VERSION "HNNBNNNYNNNNNNNNNNNNNNNNNNNNNNNNNNNNNNNNNN/4/%%%/4/'%**4NNN///"

NS_ :

BS_:

BU_: _4CL_C6 _6HP_C6 Airbag_C6 CVT_C6 DME_EDC16CP3000 DME_ME7_MED9_C6 DME_SIMOS6_C6 DME_Slave EPB_C6 ESP8_C6 Gateway_C6 LWR_AFS_C6 LWS_C6

BO_ 1088 Getriebe_1: 8 _6HP_C6
 SG_ Schaltung_aktiv : 0|1@1+ (1.0,0.0) [0.0|1.0] ""  DME_EDC16CP3000,DME_ME7_MED9_C6,DME_SIMOS6_C6,ESP8_C6,Gateway_C6
 SG_ Status_Wandlerschutz : 1|1@1+ (1.0,0.0) [0.0|1.0] ""  DME_ME7_MED9_C6,DME_SIMOS6_C6,Gateway_C6
 SG_ Klimakompressor_aus : 2|1@1+ (1.0,0.0) [0.0|1.0] ""  DME_EDC16CP3000,DME_ME7_MED9_C6,DME_SIMOS6_C6,Gateway_C6
 SG_ Wandlerkupplung : 3|2@1+ (1.0,0.0) [0.0|3.0] ""  DME_EDC16CP3000,DME_ME7_MED9_C6,DME_SIMOS6_C6,EPB_C6,Gateway_C6
 SG_ Geschwindigkeit_halten : 5|1@1+ (1.0,0.0) [0.0|1.0] ""  Gateway_C6
 SG_ Codierung_MSG : 6|1@1+ (1.0,0.0) [0.0|1.0] ""  DME_SIMOS6_C6,ESP8_C6,Gateway_C6
 SG_ EGS_Anforderung : 7|1@1+ (1.0,0.0) [0.0|1.0] ""  DME_EDC16CP3000,DME_ME7_MED9_C6,DME_SIMOS6_C6,Gateway_C6
 SG_ Zielgang : 8|4@1+ (1.0,0.0) [0.0|15.0] ""  DME_EDC16CP3000,DME_ME7_MED9_C6,DME_SIMOS6_C6,EPB_C6,ESP8_C6,Gateway_C6
 SG_ Waehlhebelposition : 12|4@1+ (1.0,0.0) [0.0|15.0] ""  DME_EDC16CP3000,DME_ME7_MED9_C6,DME_SIMOS6_C6,EPB_C6,ESP8_C6,Gateway_C6
 SG_ Uebertragungsfunktion_8Bit : 16|8@1+ (0.1,0.0) [0.0|25.4] ""  DME_EDC16CP3000,DME_ME7_MED9_C6,Gateway_C6
 SG_ Inneres_Sollmotormoment : 24|8@1+ (0.39,0.0) [0.0|99.06] "%MDI"  DME_EDC16CP3000,DME_ME7_MED9_C6,DME_SIMOS6_C6,Gateway_C6
 SG_ Fahrwiderstandsindex : 32|8@1+ (0.249,-31.623) [-31.623|31.623] ""  DME_EDC16CP3000,DME_ME7_MED9_C6,DME_SIMOS6_C6,Gateway_C6
 SG_ Getriebe_Notlauf : 40|4@1+ (1.0,0.0) [0.0|15.0] ""  DME_EDC16CP3000,DME_ME7_MED9_C6,DME_SIMOS6_C6,Gateway_C6
 SG_ Kuehlleistung : 44|2@1+ (1.0,0.0) [0.0|3.0] ""  DME_ME7_MED9_C6,DME_SIMOS6_C6,Gateway_C6
 SG_ Geschwindigkeit_Umkehr : 46|1@1+ (1.0,0.0) [0.0|1.0] ""  Gateway_C6
 SG_ OBD_Status : 47|1@1+ (1.0,0.0) [0.0|1.0] ""  DME_EDC16CP3000,DME_ME7_MED9_C6,DME_SIMOS6_C6,Gateway_C6
 SG_ Motor_aus : 48|1@1+ (1.0,0.0) [0.0|1.0] ""  Gateway_C6
 SG_ Getriebeinfo : 49|1@1+ (1.0,0.0) [0.0|1.0] ""  Gateway_C6
 SG_ SIB_Getriebe : 50|1@1+ (1.0,0.0) [0.0|1.0] ""  Gateway_C6
 SG_ BZ_Getriebe1 : 51|4@1+ (1.0,0.0) [0.0|15.0] ""  DME_ME7_MED9_C6,DME_SIMOS6_C6,EPB_C6,ESP8_C6,Gateway_C6
 SG_ FSPE_Getriebe1 : 55|1@1+ (1.0,0.0) [0.0|1.0] ""  Gateway_C6
 SG_ Aufnahmemoment_Leerlauf : 56|8@1+ (0.39,0.0) [0.0|99.06] "%MDI"  DME_EDC16CP3000,DME_ME7_MED9_C6,DME_SIMOS6_C6,Gateway_C6

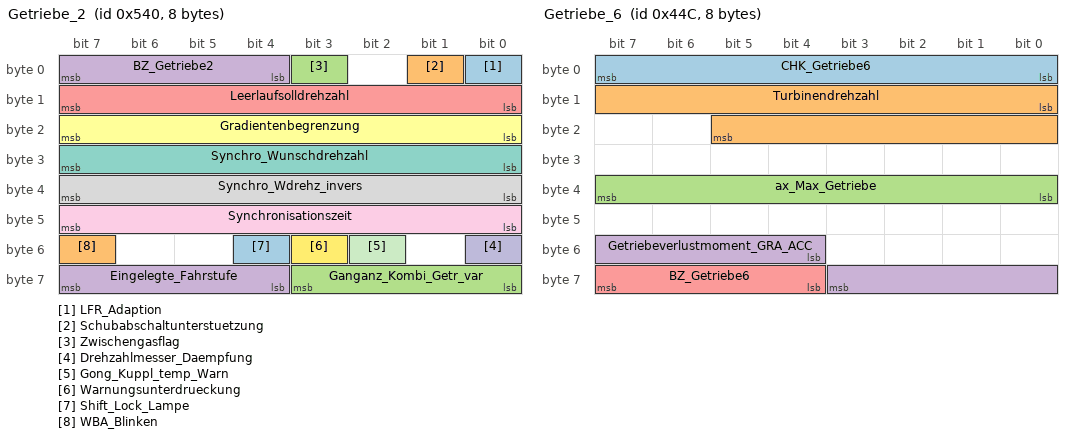
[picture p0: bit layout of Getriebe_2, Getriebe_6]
BO_ 1344 Getriebe_2: 8 _6HP_C6
 SG_ LFR_Adaption : 0|1@1+ (1.0,0.0) [0.0|1.0] ""  DME_EDC16CP3000,DME_ME7_MED9_C6,DME_SIMOS6_C6,Gateway_C6
 SG_ Schubabschaltunterstuetzung : 1|1@1+ (1.0,0.0) [0.0|1.0] ""  DME_ME7_MED9_C6,DME_SIMOS6_C6,Gateway_C6
 SG_ Zwischengasflag : 3|1@1+ (1.0,0.0) [0.0|1.0] ""  DME_EDC16CP3000,DME_ME7_MED9_C6,Gateway_C6
 SG_ BZ_Getriebe2 : 4|4@1+ (1.0,0.0) [0.0|15.0] ""  DME_EDC16CP3000,DME_ME7_MED9_C6,DME_SIMOS6_C6,Gateway_C6
 SG_ Leerlaufsolldrehzahl : 8|8@1+ (10.0,0.0) [0.0|2540.0] "1/min"  DME_EDC16CP3000,DME_ME7_MED9_C6,DME_SIMOS6_C6,Gateway_C6
 SG_ Gradientenbegrenzung : 16|8@1+ (10.0,0.0) [0.0|2540.0] "Nm/s"  DME_EDC16CP3000,DME_ME7_MED9_C6,DME_SIMOS6_C6,Gateway_C6
 SG_ Synchro_Wunschdrehzahl : 24|8@1+ (25.0,0.0) [0.0|6350.0] "1/min"  DME_EDC16CP3000,DME_ME7_MED9_C6,Gateway_C6
 SG_ Synchro_Wdrehz_invers : 32|8@1+ (-25.0,6375.0) [0.0|6350.0] "1/min"  DME_EDC16CP3000,DME_ME7_MED9_C6,Gateway_C6
 SG_ Synchronisationszeit : 40|8@1+ (20.0,0.0) [0.0|5080.0] "ms"  DME_ME7_MED9_C6,Gateway_C6
 SG_ Drehzahlmesser_Daempfung : 48|1@1+ (1.0,0.0) [0.0|1.0] ""  Gateway_C6
 SG_ Gong_Kuppl_temp_Warn : 50|1@1+ (1.0,0.0) [0.0|1.0] ""  Gateway_C6
 SG_ Warnungsunterdrueckung : 51|1@1+ (1.0,0.0) [0.0|1.0] ""  Gateway_C6
 SG_ Shift_Lock_Lampe : 52|1@1+ (1.0,0.0) [0.0|1.0] ""  Gateway_C6
 SG_ WBA_Blinken : 55|1@1+ (1.0,0.0) [0.0|1.0] ""  DME_ME7_MED9_C6,Gateway_C6
 SG_ Ganganz_Kombi_Getr_var : 56|4@1+ (1.0,0.0) [0.0|15.0] ""  Gateway_C6
 SG_ Eingelegte_Fahrstufe : 60|4@1+ (1.0,0.0) [0.0|15.0] ""  Gateway_C6

BO_ 1100 Getriebe_6: 8 _6HP_C6
 SG_ CHK_Getriebe6 : 0|8@1+ (1.0,0.0) [0.0|255.0] ""  DME_EDC16CP3000,Gateway_C6
 SG_ Turbinendrehzahl : 8|14@1+ (1.0,0.0) [0.0|16381.0] "1/min"  DME_EDC16CP3000,Gateway_C6
 SG_ ax_Max_Getriebe : 32|8@1+ (0.024,-2.112) [2.112|3.984] "m/s2"  Gateway_C6
 SG_ Getriebeverlustmoment_GRA_ACC : 52|8@1+ (0.39,0.0) [0.0|99.06] "%MDI"  Gateway_C6
 SG_ BZ_Getriebe6 : 60|4@1+ (1.0,0.0) [0.0|15.0] ""  DME_EDC16CP3000,Gateway_C6

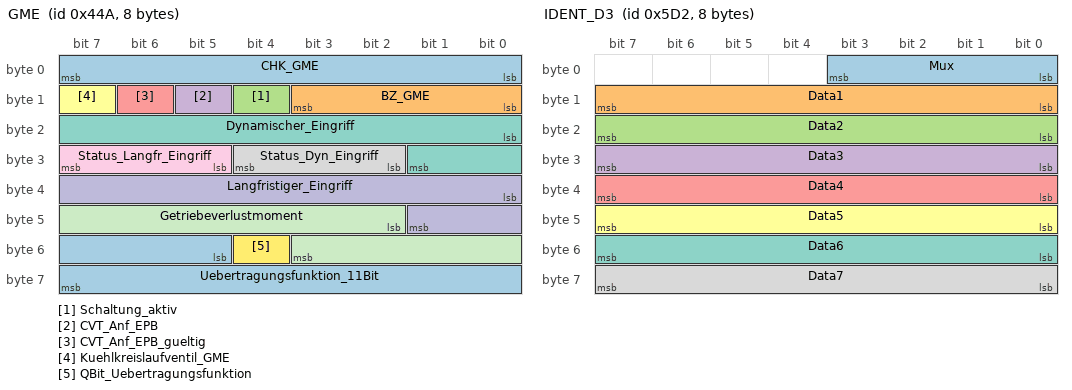
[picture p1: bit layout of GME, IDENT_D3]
BO_ 1098 GME: 8 _6HP_C6
 SG_ CHK_GME : 0|8@1+ (1.0,0.0) [0.0|255.0] ""  DME_EDC16CP3000,DME_ME7_MED9_C6,DME_SIMOS6_C6,ESP8_C6
 SG_ BZ_GME : 8|4@1+ (1.0,0.0) [0.0|15.0] ""  DME_EDC16CP3000,DME_ME7_MED9_C6,DME_SIMOS6_C6,ESP8_C6
 SG_ Schaltung_aktiv : 12|1@1+ (1.0,0.0) [0.0|1.0] ""  DME_ME7_MED9_C6,DME_SIMOS6_C6
 SG_ CVT_Anf_EPB : 13|1@1+ (1.0,0.0) [0.0|1.0] ""  Vector__XXX
 SG_ CVT_Anf_EPB_gueltig : 14|1@1+ (1.0,0.0) [0.0|1.0] ""  Vector__XXX
 SG_ Kuehlkreislaufventil_GME : 15|1@1+ (1.0,0.0) [0.0|1.0] ""  Vector__XXX
 SG_ Dynamischer_Eingriff : 16|10@1+ (1.0,0.0) [0.0|1021.0] "Nm"  DME_EDC16CP3000,DME_ME7_MED9_C6
 SG_ Status_Dyn_Eingriff : 26|3@1+ (1.0,0.0) [0.0|7.0] ""  DME_EDC16CP3000,DME_ME7_MED9_C6,DME_SIMOS6_C6
 SG_ Status_Langfr_Eingriff : 29|3@1+ (1.0,0.0) [0.0|7.0] ""  DME_EDC16CP3000,DME_ME7_MED9_C6,DME_SIMOS6_C6
 SG_ Langfristiger_Eingriff : 32|10@1+ (1.0,0.0) [0.0|1021.0] "Nm"  DME_EDC16CP3000,DME_ME7_MED9_C6,DME_SIMOS6_C6
 SG_ Getriebeverlustmoment : 42|10@1+ (1.0,0.0) [0.0|1021.0] "Nm"  DME_ME7_MED9_C6,ESP8_C6
 SG_ QBit_Uebertragungsfunktion : 52|1@1+ (1.0,0.0) [0.0|1.0] ""  Vector__XXX
 SG_ Uebertragungsfunktion_11Bit : 53|11@1+ (0.025,0.0) [0.0|51.15] ""  Vector__XXX

BO_ 906 GRA_Neu: 4 Gateway_C6
 SG_ CHK_GRA_Neu : 0|8@1+ (1.0,0.0) [0.0|255.0] ""  _6HP_C6,DME_EDC16CP3000,DME_ME7_MED9_C6,DME_SIMOS6_C6
 SG_ GRA_Hauptschalter : 8|1@1+ (1.0,0.0) [0.0|1.0] ""  DME_EDC16CP3000,DME_ME7_MED9_C6,DME_SIMOS6_C6
 SG_ Abbrechen : 9|1@1+ (1.0,0.0) [0.0|1.0] ""  DME_EDC16CP3000,DME_ME7_MED9_C6,DME_SIMOS6_C6
 SG_ KurzTip_down : 10|1@1+ (1.0,0.0) [0.0|1.0] ""  DME_EDC16CP3000,DME_ME7_MED9_C6,DME_SIMOS6_C6
 SG_ KurzTip_up : 11|1@1+ (1.0,0.0) [0.0|1.0] ""  DME_EDC16CP3000,DME_ME7_MED9_C6,DME_SIMOS6_C6
 SG_ LangTip_down : 12|1@1+ (1.0,0.0) [0.0|1.0] ""  DME_EDC16CP3000,DME_ME7_MED9_C6,DME_SIMOS6_C6
 SG_ LangTip_up : 13|1@1+ (1.0,0.0) [0.0|1.0] ""  DME_EDC16CP3000,DME_ME7_MED9_C6,DME_SIMOS6_C6
 SG_ Bedienteil_Fehler : 14|1@1+ (1.0,0.0) [0.0|1.0] ""  DME_EDC16CP3000,DME_ME7_MED9_C6,DME_SIMOS6_C6
 SG_ Codierinfo_SMLS : 15|1@1+ (1.0,0.0) [0.0|1.0] ""  DME_EDC16CP3000,DME_ME7_MED9_C6,DME_SIMOS6_C6
 SG_ Tip_Setzen : 16|1@1+ (1.0,0.0) [0.0|1.0] ""  DME_EDC16CP3000,DME_ME7_MED9_C6,DME_SIMOS6_C6
 SG_ Tip_Wiederaufnahme : 17|1@1+ (1.0,0.0) [0.0|1.0] ""  DME_EDC16CP3000,DME_ME7_MED9_C6,DME_SIMOS6_C6
 SG_ Sendercodierung : 18|2@1+ (1.0,0.0) [0.0|3.0] ""  DME_EDC16CP3000,DME_ME7_MED9_C6,DME_SIMOS6_C6
 SG_ BZ_GRA_Neu : 20|4@1+ (1.0,0.0) [0.0|15.0] ""  _6HP_C6,DME_EDC16CP3000,DME_ME7_MED9_C6,DME_SIMOS6_C6
 SG_ Tiptronic_Tip_Down : 24|1@1+ (1.0,0.0) [0.0|1.0] ""  _6HP_C6,DME_EDC16CP3000,DME_ME7_MED9_C6,DME_SIMOS6_C6
 SG_ Tiptronic_Tip_Up : 25|1@1+ (1.0,0.0) [0.0|1.0] ""  _6HP_C6,DME_EDC16CP3000,DME_ME7_MED9_C6,DME_SIMOS6_C6
 SG_ ACC_Zeitlueckenverstellung : 26|2@1+ (1.0,0.0) [0.0|3.0] ""  DME_EDC16CP3000,DME_ME7_MED9_C6,DME_SIMOS6_C6
 SG_ Tiptronic_Limiter : 28|1@1+ (1.0,0.0) [0.0|1.0] ""  DME_EDC16CP3000,DME_ME7_MED9_C6,DME_SIMOS6_C6
 SG_ Typ_Hauptschalter : 29|1@1+ (1.0,0.0) [0.0|1.0] ""  DME_EDC16CP3000,DME_ME7_MED9_C6,DME_SIMOS6_C6
 SG_ Tiptronic_Tip_Fehler : 31|1@1+ (1.0,0.0) [0.0|1.0] ""  _6HP_C6,DME_EDC16CP3000,DME_ME7_MED9_C6,DME_SIMOS6_C6

BO_ 1490 IDENT_D3: 8 Gateway_C6
 SG_ Mux : 0|4@1+ (1.0,0.0) [0.0|15.0] ""  _4CL_C6
 SG_ Data1 : 8|8@1+ (1.0,0.0) [0.0|255.0] ""  _4CL_C6
 SG_ Data2 : 16|8@1+ (1.0,0.0) [0.0|255.0] ""  _4CL_C6
 SG_ Data3 : 24|8@1+ (1.0,0.0) [0.0|255.0] ""  _4CL_C6
 SG_ Data4 : 32|8@1+ (1.0,0.0) [0.0|255.0] ""  _4CL_C6
 SG_ Data5 : 40|8@1+ (1.0,0.0) [0.0|255.0] ""  _4CL_C6
 SG_ Data6 : 48|8@1+ (1.0,0.0) [0.0|255.0] ""  _4CL_C6
 SG_ Data7 : 56|8@1+ (1.0,0.0) [0.0|255.0] ""  _4CL_C6

BO_ 2016 ISO_Request_ECU_1: 8 Gateway_C6
 SG_ ISO_Request_ECU_Data : 0|64@1+ (1.0,0.0) [0.0|1.8446744073709552E19] ""  Vector__XXX

BO_ 2017 ISO_Request_ECU_2: 8 Gateway_C6
 SG_ ISO_Request_ECU_Data : 0|64@1+ (1.0,0.0) [0.0|1.8446744073709552E19] ""  Vector__XXX

BO_ 2018 ISO_Request_ECU_3: 8 Gateway_C6
 SG_ ISO_Request_ECU_Data : 0|64@1+ (1.0,0.0) [0.0|1.8446744073709552E19] ""  Vector__XXX

BO_ 2019 ISO_Request_ECU_4: 8 Gateway_C6
 SG_ ISO_Request_ECU_Data : 0|64@1+ (1.0,0.0) [0.0|1.8446744073709552E19] ""  Vector__XXX

BO_ 2020 ISO_Request_ECU_5: 8 Gateway_C6
 SG_ ISO_Request_ECU_Data : 0|64@1+ (1.0,0.0) [0.0|1.8446744073709552E19] ""  Vector__XXX

BO_ 2021 ISO_Request_ECU_6: 8 Gateway_C6
 SG_ ISO_Request_ECU_Data : 0|64@1+ (1.0,0.0) [0.0|1.8446744073709552E19] ""  Vector__XXX

BO_ 2022 ISO_Request_ECU_7: 8 Gateway_C6
 SG_ ISO_Request_ECU_Data : 0|64@1+ (1.0,0.0) [0.0|1.8446744073709552E19] ""  Vector__XXX

BO_ 2023 ISO_Request_ECU_8: 8 Gateway_C6
 SG_ ISO_Request_ECU_Data : 0|64@1+ (1.0,0.0) [0.0|1.8446744073709552E19] ""  Vector__XXX

BO_ 2015 ISO_Request_ECU_9: 8 Gateway_C6
 SG_ ISO_Request_ECU_Data : 0|64@1+ (1.0,0.0) [0.0|1.8446744073709552E19] ""  Vector__XXX

BO_ 2024 ISO_Response_ECU_1: 8 Vector__XXX
 SG_ ISO_Response_ECU_Data : 0|64@1+ (1.0,0.0) [0.0|1.8446744073709552E19] ""  Gateway_C6

BO_ 2025 ISO_Response_ECU_2: 8 Vector__XXX
 SG_ ISO_Response_ECU_Data : 0|64@1+ (1.0,0.0) [0.0|1.8446744073709552E19] ""  Gateway_C6

BO_ 2026 ISO_Response_ECU_3: 8 Vector__XXX
 SG_ ISO_Response_ECU_Data : 0|64@1+ (1.0,0.0) [0.0|1.8446744073709552E19] ""  Gateway_C6

BO_ 2027 ISO_Response_ECU_4: 8 Vector__XXX
 SG_ ISO_Response_ECU_Data : 0|64@1+ (1.0,0.0) [0.0|1.8446744073709552E19] ""  Gateway_C6

BO_ 2028 ISO_Response_ECU_5: 8 Vector__XXX
 SG_ ISO_Response_ECU_Data : 0|64@1+ (1.0,0.0) [0.0|1.8446744073709552E19] ""  Gateway_C6

BO_ 2029 ISO_Response_ECU_6: 8 Vector__XXX
 SG_ ISO_Response_ECU_Data : 0|64@1+ (1.0,0.0) [0.0|1.8446744073709552E19] ""  Gateway_C6

BO_ 2030 ISO_Response_ECU_7: 8 Vector__XXX
 SG_ ISO_Response_ECU_Data : 0|64@1+ (1.0,0.0) [0.0|1.8446744073709552E19] ""  Gateway_C6

BO_ 2031 ISO_Response_ECU_8: 8 Vector__XXX
 SG_ ISO_Response_ECU_Data : 0|64@1+ (1.0,0.0) [0.0|1.8446744073709552E19] ""  Gateway_C6

BO_ 1504 Klima1_D3_ACAN: 8 Gateway_C6
 SG_ Signal_fuer_Drehzahlanhebung : 0|1@1+ (1.0,0.0) [0.0|1.0] ""  DME_EDC16CP3000,DME_ME7_MED9_C6,DME_SIMOS6_C6
 SG_ Zuheizer_ein : 1|1@1+ (1.0,0.0) [0.0|1.0] ""  DME_EDC16CP3000,DME_ME7_MED9_C6,DME_SIMOS6_C6
 SG_ HeizungHeckscheibe_ein : 2|1@1+ (1.0,0.0) [0.0|1.0] ""  DME_ME7_MED9_C6
 SG_ HeizungFrontscheibe_ein : 3|1@1+ (1.0,0.0) [0.0|1.0] ""  DME_ME7_MED9_C6
 SG_ Kompressor_ein : 4|1@1+ (1.0,0.0) [0.0|1.0] ""  DME_EDC16CP3000,DME_ME7_MED9_C6,DME_SIMOS6_C6
 SG_ Heizung_ausgeschaltet : 5|1@1+ (1.0,0.0) [0.0|1.0] ""  DME_EDC16CP3000,DME_ME7_MED9_C6
 SG_ Kompressormoment_alt : 6|1@1+ (1.0,0.0) [0.0|1.0] ""  Vector__XXX
 SG_ Kaeltemitteldruck_alt : 7|1@1+ (1.0,0.0) [0.0|1.0] ""  Vector__XXX
 SG_ AussenTemp_aus_Wasserkasten : 8|8@1+ (0.5,-50.0) [-50.0|77.0] "°C"  Vector__XXX
 SG_ KaeltemittelDruck : 16|8@1+ (0.2,0.0) [0.0|50.8] "bar"  DME_ME7_MED9_C6,DME_SIMOS6_C6
 SG_ Kompressorlastinfo : 24|8@1+ (0.25,0.0) [0.0|63.5] "Nm"  DME_EDC16CP3000,DME_ME7_MED9_C6,DME_SIMOS6_C6
 SG_ Geblaeselastinfo : 32|8@1+ (0.4,0.0) [0.0|101.6] "%"  DME_ME7_MED9_C6
 SG_ Ansteuerung_Kuehlerluefter : 40|8@1+ (0.4,0.0) [0.0|101.6] "%"  DME_EDC16CP3000,DME_ME7_MED9_C6,DME_SIMOS6_C6
 SG_ Temp_in_F : 48|1@1+ (1.0,0.0) [0.0|1.0] ""  Vector__XXX
 SG_ Zustand_Klima : 49|1@1+ (1.0,0.0) [0.0|1.0] ""  DME_SIMOS6_C6
 SG_ Restwaermefunktion : 51|1@1+ (1.0,0.0) [0.0|1.0] ""  Vector__XXX
 SG_ SH_aktiv_Flag : 52|1@1+ (1.0,0.0) [0.0|1.0] ""  Vector__XXX
 SG_ SH_MVW : 53|1@1+ (1.0,0.0) [0.0|1.0] ""  Vector__XXX
 SG_ KD_Fehler_Klima : 55|1@1+ (1.0,0.0) [0.0|1.0] ""  Vector__XXX
 SG_ Aussentemp_Stossf_ungef : 56|8@1+ (0.5,-50.0) [-50.0|77.0] "°C"  Vector__XXX

BO_ 800 Kombi_1: 8 Gateway_C6
 SG_ SIB_Kombi : 0|1@1+ (1.0,0.0) [0.0|1.0] ""  Vector__XXX
 SG_ FStatus_Tank : 1|1@1+ (1.0,0.0) [0.0|1.0] ""  DME_ME7_MED9_C6,DME_SIMOS6_C6
 SG_ Oeldruck : 2|1@1+ (1.0,0.0) [0.0|1.0] ""  Vector__XXX
 SG_ Dyn_Oeldr_warn : 3|1@1+ (1.0,0.0) [0.0|1.0] ""  Vector__XXX
 SG_ Kuehlmittelmangel : 4|1@1+ (1.0,0.0) [0.0|1.0] ""  Vector__XXX
 SG_ Wakeup_Komfort : 5|1@1+ (1.0,0.0) [0.0|1.0] ""  Vector__XXX
 SG_ Tankwarnlampe : 6|1@1+ (1.0,0.0) [0.0|1.0] ""  DME_EDC16CP3000,DME_SIMOS6_C6
 SG_ Vorgluehlampe_Kombi : 7|1@1+ (1.0,0.0) [0.0|1.0] ""  DME_EDC16CP3000
 SG_ Bremsfluessigkeitswarnung : 8|1@1+ (1.0,0.0) [0.0|1.0] ""  Vector__XXX
 SG_ Handbremse_angezogen : 9|1@1+ (1.0,0.0) [0.0|1.0] ""  Vector__XXX
 SG_ Ladekontroll_Lampe : 10|1@1+ (1.0,0.0) [0.0|1.0] ""  Vector__XXX
 SG_ Kombi_im_Stellgliedtest : 11|1@1+ (1.0,0.0) [0.0|1.0] ""  Vector__XXX
 SG_ ACC_Zusatzanzeige : 12|3@1+ (1.0,0.0) [0.0|7.0] ""  Vector__XXX
 SG_ Tankstop : 15|1@1+ (1.0,0.0) [0.0|1.0] ""  Vector__XXX
 SG_ Tankinhalt : 16|7@1+ (1.0,0.0) [0.0|126.0] "l"  DME_ME7_MED9_C6,DME_SIMOS6_C6
 SG_ Tankwarnung : 23|1@1+ (1.0,0.0) [0.0|1.0] ""  DME_ME7_MED9_C6,DME_SIMOS6_C6
 SG_ Signalquelle_Geschwindigkeit : 24|1@1+ (1.0,0.0) [0.0|1.0] ""  Vector__XXX
 SG_ BZ_Kombi1 : 40|4@1+ (1.0,0.0) [0.0|15.0] ""  Vector__XXX
 SG_ Konsistenz_ACC_Botschaften : 44|1@1+ (1.0,0.0) [0.0|1.0] ""  Vector__XXX
 SG_ ACC_Anzeigefehler : 45|1@1+ (1.0,0.0) [0.0|1.0] ""  Vector__XXX
 SG_ angez_Geschw : 46|10@1+ (0.31988,0.0) [0.0|325.0] "km/h"  Vector__XXX
 SG_ Einheit_angez_Geschw : 56|1@1+ (1.0,0.0) [0.0|1.0] ""  Vector__XXX
 SG_ ABS_Lampe_ein : 57|1@1+ (1.0,0.0) [0.0|1.0] ""  Vector__XXX
 SG_ ASR_ESP_Lampe_ein : 58|1@1+ (1.0,0.0) [0.0|1.0] ""  Vector__XXX
 SG_ BKL_ein : 59|1@1+ (1.0,0.0) [0.0|1.0] ""  Vector__XXX
 SG_ Airbag_Lampe_ein : 60|1@1+ (1.0,0.0) [0.0|1.0] ""  Vector__XXX
 SG_ Lenkhilfe_Lampe_ein : 61|1@1+ (1.0,0.0) [0.0|1.0] ""  Vector__XXX
 SG_ LDW_Anzeigefehler : 62|1@1+ (1.0,0.0) [0.0|1.0] ""  Vector__XXX
 SG_ SILA_gueltig : 63|1@1+ (1.0,0.0) [0.0|1.0] ""  Vector__XXX

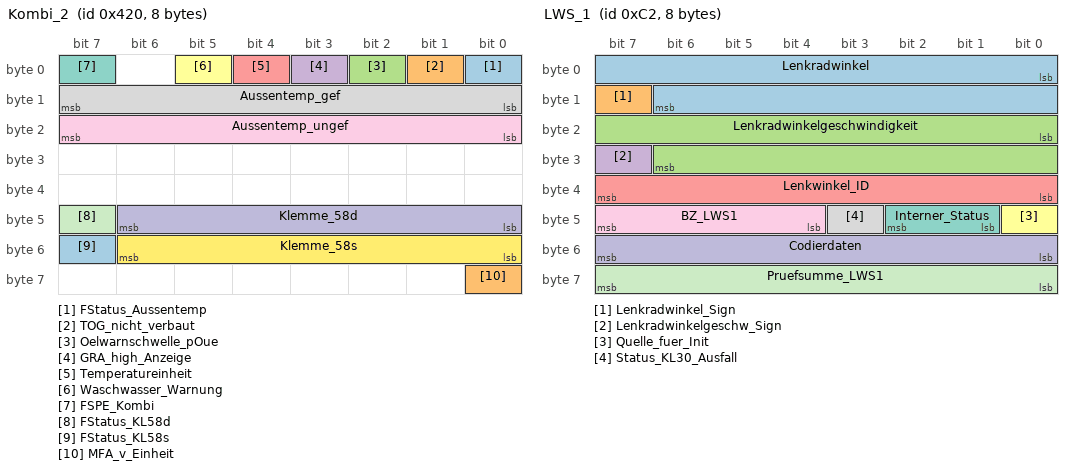
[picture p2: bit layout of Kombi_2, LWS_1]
BO_ 1056 Kombi_2: 8 Gateway_C6
 SG_ FStatus_Aussentemp : 0|1@1+ (1.0,0.0) [0.0|1.0] ""  DME_EDC16CP3000,DME_SIMOS6_C6,EPB_C6,ESP8_C6
 SG_ TOG_nicht_verbaut : 1|1@1+ (1.0,0.0) [0.0|1.0] ""  DME_ME7_MED9_C6
 SG_ Oelwarnschwelle_pOue : 2|1@1+ (1.0,0.0) [0.0|1.0] ""  Vector__XXX
 SG_ GRA_high_Anzeige : 3|1@1+ (1.0,0.0) [0.0|1.0] ""  Vector__XXX
 SG_ Temperatureinheit : 4|1@1+ (1.0,0.0) [0.0|1.0] ""  Vector__XXX
 SG_ Waschwasser_Warnung : 5|1@1+ (1.0,0.0) [0.0|1.0] ""  Vector__XXX
 SG_ FSPE_Kombi : 7|1@1+ (1.0,0.0) [0.0|1.0] ""  Vector__XXX
 SG_ Aussentemp_gef : 8|8@1+ (0.5,-50.0) [-50.0|77.0] "°C"  _6HP_C6,DME_EDC16CP3000,DME_ME7_MED9_C6,DME_SIMOS6_C6,EPB_C6,ESP8_C6
 SG_ Aussentemp_ungef : 16|8@1+ (0.5,-50.0) [-50.0|77.0] "°C"  DME_SIMOS6_C6
 SG_ Klemme_58d : 40|7@1+ (1.0,0.0) [0.0|100.0] "%"  Airbag_C6
 SG_ FStatus_KL58d : 47|1@1+ (1.0,0.0) [0.0|1.0] ""  Airbag_C6
 SG_ Klemme_58s : 48|7@1+ (1.0,0.0) [0.0|100.0] "%"  Vector__XXX
 SG_ FStatus_KL58s : 55|1@1+ (1.0,0.0) [0.0|1.0] ""  Vector__XXX
 SG_ MFA_v_Einheit : 56|1@1+ (1.0,0.0) [0.0|1.0] ""  Vector__XXX

BO_ 1312 Kombi_3: 8 Gateway_C6
 SG_ Multiplex_Sprachvariante m0  : 0|8@1+ (1.0,0.0) [0.0|255.0] ""  Airbag_C6
 SG_ Derivat m1  : 0|4@1+ (1.0,0.0) [0.0|15.0] ""  Vector__XXX
 SG_ Reifenumfang m2  : 0|12@1+ (1.0,0.0) [0.0|4095.0] "mm"  ESP8_C6
 SG_ Verbauliste m3  : 0|11@1+ (1.0,0.0) [0.0|2047.0] ""  Vector__XXX
 SG_ Generation m1  : 4|4@1+ (1.0,0.0) [0.0|15.0] ""  Vector__XXX
 SG_ Multiplex_Laendervariante m0  : 8|6@1+ (1.0,0.0) [0.0|63.0] ""  Airbag_C6
 SG_ Baureihe m1  : 8|3@1+ (1.0,0.0) [0.0|7.0] ""  Vector__XXX
 SG_ Marke m1  : 11|3@1+ (1.0,0.0) [0.0|7.0] ""  Vector__XXX
 SG_ Mux_Code_Kombi3 M  : 14|2@1+ (1.0,0.0) [0.0|3.0] ""  Airbag_C6,ESP8_C6
 SG_ Schluesselinfo : 16|4@1+ (1.0,0.0) [0.0|15.0] ""  Vector__XXX
 SG_ Standzeit : 24|15@1+ (4.0,0.0) [0.0|131068.0] "s"  DME_ME7_MED9_C6,DME_SIMOS6_C6,EPB_C6,ESP8_C6
 SG_ Reset_Standzeit : 39|1@1+ (1.0,0.0) [0.0|1.0] ""  DME_ME7_MED9_C6,EPB_C6,ESP8_C6
 SG_ Kilometerstand : 40|20@1+ (1.0,0.0) [0.0|1048574.0] "km"  _6HP_C6,DME_ME7_MED9_C6,DME_SIMOS6_C6

BO_ 916 LWR_Zustand: 8 LWR_AFS_C6
 SG_ LWR_AFS_Parametrisierung : 0|1@1+ (1.0,0.0) [0.0|1.0] ""  Gateway_C6
 SG_ LWR_AFS_Grundeinstellung : 1|1@1+ (1.0,0.0) [0.0|1.0] ""  Gateway_C6
 SG_ LWR_Modus : 2|1@1+ (1.0,0.0) [0.0|1.0] ""  Gateway_C6
 SG_ LWR_Initialisierungslauf : 3|1@1+ (1.0,0.0) [0.0|1.0] ""  Gateway_C6
 SG_ LWR_Sicherheitsposition : 4|1@1+ (1.0,0.0) [0.0|1.0] ""  Gateway_C6
 SG_ AFS_Fehlerlampe : 5|1@1+ (1.0,0.0) [0.0|1.0] ""  Gateway_C6
 SG_ LWR_Fehlerlampe : 6|1@1+ (1.0,0.0) [0.0|1.0] ""  Gateway_C6
 SG_ FSPE_LWR_AFS : 7|1@1+ (1.0,0.0) [0.0|1.0] ""  Gateway_C6
 SG_ Einfederung_Karosse_vorn : 8|8@1+ (1.0,-127.0) [-126.0|126.0] ""  Gateway_C6
 SG_ Einfederung_Karosse_hinten : 16|8@1+ (1.0,-127.0) [-126.0|126.0] ""  Gateway_C6
 SG_ Stellung_Schrittmotoren : 24|8@1+ (0.4,0.0) [0.0|100.0] "%"  Gateway_C6
 SG_ Sollwert_LD_EVG : 32|8@1+ (0.4,50.0) [50.0|151.2] "%"  Gateway_C6
 SG_ Ersatzlichtfunktion_links : 40|1@1+ (1.0,0.0) [0.0|1.0] ""  Gateway_C6
 SG_ Ersatzlichtfunktion_rechts : 41|1@1+ (1.0,0.0) [0.0|1.0] ""  Gateway_C6
 SG_ AFS_LED_Blinkmode : 42|1@1+ (1.0,0.0) [0.0|1.0] ""  Gateway_C6
 SG_ AFS_Fehlertext : 43|1@1+ (1.0,0.0) [0.0|1.0] ""  Gateway_C6
 SG_ BZ_LWR_Zustand : 60|4@1+ (1.0,0.0) [0.0|15.0] ""  Gateway_C6

BO_ 194 LWS_1: 8 LWS_C6
 SG_ Lenkradwinkel : 0|15@1+ (0.04375,0.0) [0.0|1433.55625] "Grad"  _4CL_C6,_6HP_C6,DME_ME7_MED9_C6,DME_SIMOS6_C6,ESP8_C6,Gateway_C6,LWR_AFS_C6
 SG_ Lenkradwinkel_Sign : 15|1@1+ (1.0,0.0) [0.0|1.0] ""  _4CL_C6,_6HP_C6,DME_SIMOS6_C6,ESP8_C6,Gateway_C6,LWR_AFS_C6
 SG_ Lenkradwinkelgeschwindigkeit : 16|15@1+ (0.04375,0.0) [0.0|1433.55625] "Grad/s"  _4CL_C6,DME_ME7_MED9_C6,DME_SIMOS6_C6,Gateway_C6
 SG_ Lenkradwinkelgeschw_Sign : 31|1@1+ (1.0,0.0) [0.0|1.0] ""  _4CL_C6,DME_SIMOS6_C6,Gateway_C6
 SG_ Lenkwinkel_ID : 32|8@1+ (1.0,0.0) [0.0|255.0] ""  ESP8_C6,Gateway_C6
 SG_ Quelle_fuer_Init : 40|1@1+ (1.0,0.0) [0.0|1.0] ""  Gateway_C6
 SG_ Interner_Status : 41|2@1+ (1.0,0.0) [0.0|4.0] ""  _4CL_C6,DME_ME7_MED9_C6,DME_SIMOS6_C6,ESP8_C6,Gateway_C6,LWR_AFS_C6
 SG_ Status_KL30_Ausfall : 43|1@1+ (1.0,0.0) [0.0|1.0] ""  Gateway_C6
 SG_ BZ_LWS1 : 44|4@1+ (1.0,0.0) [0.0|15.0] ""  _4CL_C6,DME_SIMOS6_C6,ESP8_C6,Gateway_C6
 SG_ Codierdaten : 48|8@1+ (1.0,0.0) [0.0|255.0] ""  ESP8_C6,Gateway_C6
 SG_ Pruefsumme_LWS1 : 56|8@1+ (1.0,0.0) [0.0|255.0] ""  _4CL_C6,DME_SIMOS6_C6,ESP8_C6,Gateway_C6

BO_ 1984 LWS_Calib: 2 ESP8_C6
 SG_ Command_Code_Word : 0|4@1+ (1.0,0.0) [0.0|15.0] ""  LWS_C6
 SG_ LWS_Identifier : 8|7@1+ (1.0,0.0) [0.0|127.0] ""  LWS_C6

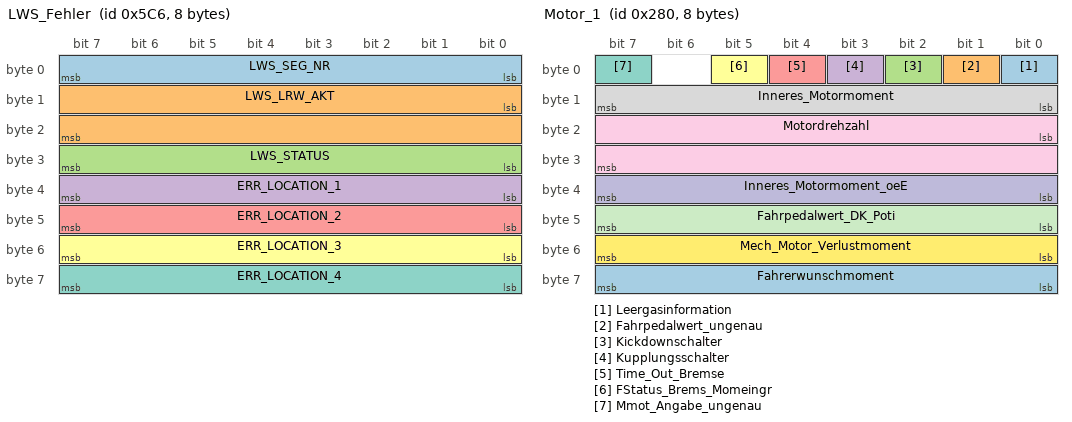
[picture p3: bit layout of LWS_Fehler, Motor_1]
BO_ 1478 LWS_Fehler: 8 LWS_C6
 SG_ LWS_SEG_NR : 0|8@1+ (1.0,0.0) [0.0|255.0] ""  ESP8_C6
 SG_ LWS_LRW_AKT : 8|16@1+ (1.0,0.0) [0.0|65535.0] ""  ESP8_C6
 SG_ LWS_STATUS : 24|8@1+ (1.0,0.0) [0.0|255.0] ""  ESP8_C6
 SG_ ERR_LOCATION_1 : 32|8@1+ (1.0,0.0) [0.0|255.0] ""  ESP8_C6
 SG_ ERR_LOCATION_2 : 40|8@1+ (1.0,0.0) [0.0|255.0] ""  ESP8_C6
 SG_ ERR_LOCATION_3 : 48|8@1+ (1.0,0.0) [0.0|255.0] ""  ESP8_C6
 SG_ ERR_LOCATION_4 : 56|8@1+ (1.0,0.0) [0.0|255.0] ""  ESP8_C6

BO_ 1986 LWS_Init: 4 ESP8_C6
 SG_ ID_fuer_LWS_Init : 0|8@1+ (1.0,0.0) [0.0|255.0] ""  LWS_C6
 SG_ Codierbytes : 8|24@1+ (1.0,0.0) [0.0|255.0] ""  LWS_C6

BO_ 640 Motor_1: 8 DME_EDC16CP3000
 SG_ Leergasinformation : 0|1@1+ (1.0,0.0) [0.0|1.0] ""  EPB_C6,ESP8_C6,Gateway_C6
 SG_ Fahrpedalwert_ungenau : 1|1@1+ (1.0,0.0) [0.0|1.0] ""  _6HP_C6,ESP8_C6,Gateway_C6
 SG_ Kickdownschalter : 2|1@1+ (1.0,0.0) [0.0|1.0] ""  _6HP_C6,Gateway_C6
 SG_ Kupplungsschalter : 3|1@1+ (1.0,0.0) [0.0|1.0] ""  EPB_C6,ESP8_C6,Gateway_C6
 SG_ Time_Out_Bremse : 4|1@1+ (1.0,0.0) [0.0|1.0] ""  ESP8_C6,Gateway_C6
 SG_ FStatus_Brems_Momeingr : 5|1@1+ (1.0,0.0) [0.0|1.0] ""  ESP8_C6,Gateway_C6
 SG_ Mmot_Angabe_ungenau : 7|1@1+ (1.0,0.0) [0.0|1.0] ""  _6HP_C6,EPB_C6,ESP8_C6,Gateway_C6
 SG_ Inneres_Motormoment : 8|8@1+ (0.39,0.0) [0.0|99.06] "%MDI"  _6HP_C6,EPB_C6,ESP8_C6,Gateway_C6
 SG_ Motordrehzahl : 16|16@1+ (0.25,0.0) [0.0|16256.0] "1/min"  _4CL_C6,_6HP_C6,EPB_C6,ESP8_C6,Gateway_C6,LWR_AFS_C6
 SG_ Inneres_Motormoment_oeE : 32|8@1+ (0.39,0.0) [0.0|99.06] "%MDI"  _6HP_C6,Gateway_C6
 SG_ Fahrpedalwert_DK_Poti : 40|8@1+ (0.4,0.0) [0.0|101.6] "%"  _6HP_C6,ESP8_C6,Gateway_C6
 SG_ Mech_Motor_Verlustmoment : 48|8@1+ (0.39,0.0) [0.0|99.06] "%MDI"  _6HP_C6,EPB_C6,ESP8_C6,Gateway_C6
 SG_ Fahrerwunschmoment : 56|8@1+ (0.39,0.0) [0.0|99.06] "%MDI"  _4CL_C6,_6HP_C6,EPB_C6,ESP8_C6,Gateway_C6

BO_ 648 Motor_2: 8 DME_EDC16CP3000
 SG_ CAN_Stand m0  : 0|6@1+ (1.0,0.0) [0.0|63.0] ""  Gateway_C6
 SG_ Motorcode m1  : 0|6@1+ (1.0,0.0) [0.0|63.0] ""  Gateway_C6
 SG_ Getriebecode m2  : 0|6@1+ (1.0,0.0) [0.0|63.0] ""  Gateway_C6
 SG_ MDI_max m3  : 0|6@1+ (10.0,0.0) [0.0|630.0] "Nm"  _6HP_C6,EPB_C6,ESP8_C6,Gateway_C6
 SG_ Mux_Code_Motor2 M  : 6|2@1+ (1.0,0.0) [0.0|3.0] ""  _6HP_C6,EPB_C6,ESP8_C6,Gateway_C6
 SG_ Kuehlmitteltemperatur : 8|8@1+ (0.75,-48.0) [-47.25|142.5] "°C"  _6HP_C6,Gateway_C6
 SG_ Bremslichtschalter_Motor : 16|1@1+ (1.0,0.0) [0.0|1.0] ""  _6HP_C6,Gateway_C6
 SG_ Bremstestschalter_Motor : 17|1@1+ (1.0,0.0) [0.0|1.0] ""  _6HP_C6,Gateway_C6
 SG_ FStatus_Kuehlmitteltemp_Motor : 18|1@1+ (1.0,0.0) [0.0|1.0] ""  _6HP_C6,Gateway_C6
 SG_ Ansteuerung_Klima : 19|1@1+ (1.0,0.0) [0.0|1.0] ""  _6HP_C6,Gateway_C6
 SG_ Status_Normalbetrieb : 20|1@1+ (1.0,0.0) [0.0|1.0] ""  _6HP_C6,Gateway_C6
 SG_ OBD2_Freeze_Frame : 21|1@1+ (1.0,0.0) [0.0|1.0] ""  Gateway_C6
 SG_ GRA_Status : 22|2@1+ (1.0,0.0) [0.0|3.0] ""  _6HP_C6,Gateway_C6
 SG_ GRA_auf_angez_Geschw : 26|1@1+ (1.0,0.0) [0.0|1.0] ""  Gateway_C6
 SG_ Soll_Geschw_GRA : 32|8@1+ (1.28,0.0) [0.0|325.12] "km/h"  _6HP_C6,Gateway_C6
 SG_ Leerlaufsolldrehzahl : 40|8@1+ (10.0,0.0) [0.0|2540.0] "1/min"  _6HP_C6,Gateway_C6
 SG_ Begrenzungsmoment : 48|8@1+ (0.39,0.0) [0.0|99.06] "%MDI"  Gateway_C6
 SG_ Min_Mmot__ZW_Rueckn : 56|8@1+ (0.39,0.0) [0.0|99.06] "%MDI"  ESP8_C6,Gateway_C6

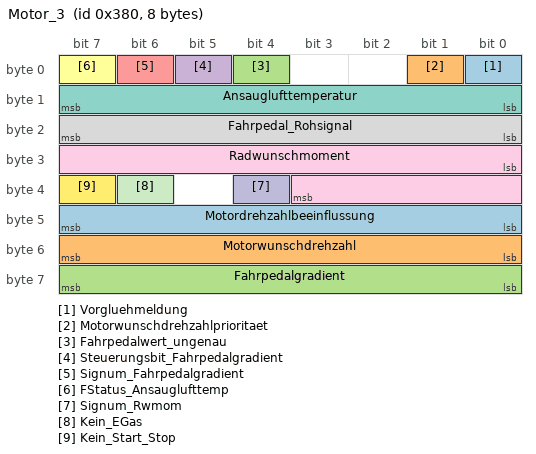
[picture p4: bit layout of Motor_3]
BO_ 896 Motor_3: 8 DME_EDC16CP3000
 SG_ Vorgluehmeldung : 0|1@1+ (1.0,0.0) [0.0|1.0] ""  Gateway_C6
 SG_ Motorwunschdrehzahlprioritaet : 1|1@1+ (1.0,0.0) [0.0|1.0] ""  Gateway_C6
 SG_ Fahrpedalwert_ungenau : 4|1@1+ (1.0,0.0) [0.0|1.0] ""  EPB_C6,Gateway_C6
 SG_ Steuerungsbit_Fahrpedalgradient : 5|1@1+ (1.0,0.0) [0.0|1.0] ""  Gateway_C6
 SG_ Signum_Fahrpedalgradient : 6|1@1+ (1.0,0.0) [0.0|1.0] ""  Gateway_C6
 SG_ FStatus_Ansauglufttemp : 7|1@1+ (1.0,0.0) [0.0|1.0] ""  Gateway_C6
 SG_ Ansauglufttemperatur : 8|8@1+ (0.75,-48.0) [-48.0|142.5] "°C"  Gateway_C6
 SG_ Fahrpedal_Rohsignal : 16|8@1+ (0.4,0.0) [0.0|101.6] "%"  EPB_C6,Gateway_C6
 SG_ Radwunschmoment : 24|12@1+ (0.39,0.0) [0.0|1597.05] "%MDI"  Gateway_C6
 SG_ Signum_Rwmom : 36|1@1+ (1.0,0.0) [0.0|1.0] ""  Gateway_C6
 SG_ Kein_EGas : 38|1@1+ (1.0,0.0) [0.0|1.0] ""  Gateway_C6
 SG_ Kein_Start_Stop : 39|1@1+ (1.0,0.0) [0.0|1.0] ""  Gateway_C6
 SG_ Motordrehzahlbeeinflussung : 40|8@1+ (0.39,0.0) [0.0|99.45] "%"  Gateway_C6
 SG_ Motorwunschdrehzahl : 48|8@1+ (25.0,0.0) [0.0|6325.0] "1/min"  Gateway_C6
 SG_ Fahrpedalgradient : 56|8@1+ (25.0,0.0) [0.0|6375.0] "%/s"  Gateway_C6

BO_ 1152 Motor_5: 8 DME_EDC16CP3000
 SG_ Max_Drehmoment_630Nm m0  : 0|6@1+ (10.0,0.0) [0.0|630.0] "Nm"  Gateway_C6
 SG_ Drehzahl_max_Drehmoment m1  : 0|6@1+ (100.0,0.0) [0.0|6300.0] "1/min"  Gateway_C6
 SG_ Motortyp m2  : 0|6@1+ (1.0,0.0) [0.0|63.0] ""  Gateway_C6
 SG_ Abgastyp m3  : 0|6@1+ (1.0,0.0) [0.0|63.0] "360°/2^32"  _6HP_C6,Gateway_C6
 SG_ Mux_Code_Motor5 M  : 6|2@1+ (1.0,0.0) [0.0|3.0] ""  _6HP_C6,Gateway_C6
 SG_ Ladekontroll_Lampe : 8|1@1+ (1.0,0.0) [0.0|1.0] ""  Gateway_C6
 SG_ Vorgluehlampe_Motor : 9|1@1+ (1.0,0.0) [0.0|1.0] ""  Gateway_C6
 SG_ EGas_Lampe : 10|1@1+ (1.0,0.0) [0.0|1.0] ""  Gateway_C6
 SG_ OBD2_Lampe : 11|1@1+ (1.0,0.0) [0.0|1.0] ""  Gateway_C6
 SG_ Heissleuchte : 12|1@1+ (1.0,0.0) [0.0|1.0] ""  Gateway_C6
 SG_ KK_aus : 13|1@1+ (1.0,0.0) [0.0|1.0] ""  Gateway_C6
 SG_ Kennfeldkuehlung : 14|1@1+ (1.0,0.0) [0.0|1.0] ""  Gateway_C6
 SG_ KK_Leistungsreduzierung : 15|1@1+ (1.0,0.0) [0.0|1.0] ""  Gateway_C6
 SG_ Kraftstoffverbrauchsignal : 16|15@1+ (1.0,0.0) [0.0|32767.0] "ul"  Gateway_C6
 SG_ Verbrauch_Ueberlauf : 31|1@1+ (1.0,0.0) [0.0|1.0] ""  Gateway_C6
 SG_ Kuehlerluefteransteuerung : 32|8@1+ (0.4,0.0) [0.0|101.6] "%"  Gateway_C6
 SG_ HLVW_Motor : 40|1@1+ (1.0,0.0) [0.0|1.0] ""  Gateway_C6
 SG_ Partikelfilter_Lampe : 41|1@1+ (1.0,0.0) [0.0|1.0] ""  Gateway_C6
 SG_ FStatus_BKU_Pumpe : 42|1@1+ (1.0,0.0) [0.0|1.0] ""  Gateway_C6
 SG_ Typ_Startersteuerung : 43|1@1+ (1.0,0.0) [0.0|1.0] ""  Gateway_C6
 SG_ Lampe_Tankdeckelwarnung : 44|1@1+ (1.0,0.0) [0.0|1.0] ""  Gateway_C6
 SG_ Textbit_Tankdeckelwarn : 45|1@1+ (1.0,0.0) [0.0|1.0] ""  Gateway_C6
 SG_ Drehzahlmesser_Daempfung : 46|1@1+ (1.0,0.0) [0.0|1.0] ""  Gateway_C6
 SG_ Interlock_Schalter : 47|1@1+ (1.0,0.0) [0.0|1.0] ""  Gateway_C6
 SG_ Anlasser_Freigabe : 48|1@1+ (1.0,0.0) [0.0|1.0] ""  Gateway_C6
 SG_ Anlasser_Ausspuren : 49|1@1+ (1.0,0.0) [0.0|1.0] ""  Gateway_C6
 SG_ GRA_Hauptschalter : 50|1@1+ (1.0,0.0) [0.0|1.0] ""  Gateway_C6
 SG_ Doppelte_Momente : 51|1@1+ (1.0,0.0) [0.0|1.0] ""  _6HP_C6,ESP8_C6,Gateway_C6
 SG_ Motortext_Bits : 52|4@1+ (1.0,0.0) [0.0|15.0] ""  Gateway_C6
 SG_ CHK_Motor5 : 56|8@1+ (1.0,0.0) [0.0|255.0] ""  ESP8_C6,Gateway_C6

BO_TX_BU_ 1088 :_6HP_C6,CVT_C6;
BO_TX_BU_ 1344 :_6HP_C6,CVT_C6;
BO_TX_BU_ 1100 :_6HP_C6,CVT_C6;
BO_TX_BU_ 1098 :_6HP_C6,CVT_C6;
BO_TX_BU_ 640 :DME_EDC16CP3000,DME_ME7_MED9_C6,DME_SIMOS6_C6;
BO_TX_BU_ 648 :DME_EDC16CP3000,DME_ME7_MED9_C6,DME_SIMOS6_C6;
BO_TX_BU_ 896 :DME_EDC16CP3000,DME_ME7_MED9_C6,DME_SIMOS6_C6;
BO_TX_BU_ 1152 :DME_EDC16CP3000,DME_ME7_MED9_C6,DME_SIMOS6_C6;
CM_ BO_ 2016 "Gesetzlich vorgeschrieber ISO-Diagnose-Kanal für OBD.";
CM_ BO_ 2017 "Gesetzlich vorgeschrieber ISO-Diagnose-Kanal für OBD.";
CM_ BO_ 2018 "Gesetzlich vorgeschrieber ISO-Diagnose-Kanal für OBD.";
CM_ BO_ 2019 "Gesetzlich vorgeschrieber ISO-Diagnose-Kanal für OBD.";
CM_ BO_ 2020 "Gesetzlich vorgeschrieber ISO-Diagnose-Kanal für OBD.";
CM_ BO_ 2021 "Gesetzlich vorgeschrieber ISO-Diagnose-Kanal für OBD.";
CM_ BO_ 2022 "Gesetzlich vorgeschrieber ISO-Diagnose-Kanal für OBD.";
CM_ BO_ 2023 "Gesetzlich vorgeschrieber ISO-Diagnose-Kanal für OBD.";
CM_ BO_ 2015 "Gesetzlich vorgeschrieber ISO-Diagnose-Kanal für OBD.";
CM_ BO_ 2024 "Gesetzlich vorgeschrieber ISO-Diagnose-Kanal für OBD.";
CM_ BO_ 2025 "Gesetzlich vorgeschrieber ISO-Diagnose-Kanal für OBD.";
CM_ BO_ 2026 "Gesetzlich vorgeschrieber ISO-Diagnose-Kanal für OBD.";
CM_ BO_ 2027 "Gesetzlich vorgeschrieber ISO-Diagnose-Kanal für OBD.";
CM_ BO_ 2028 "Gesetzlich vorgeschrieber ISO-Diagnose-Kanal für OBD.";
CM_ BO_ 2029 "Gesetzlich vorgeschrieber ISO-Diagnose-Kanal für OBD.";
CM_ BO_ 2030 "Gesetzlich vorgeschrieber ISO-Diagnose-Kanal für OBD.";
CM_ BO_ 2031 "Gesetzlich vorgeschrieber ISO-Diagnose-Kanal für OBD.";

CM_ SG_ 1088 Aufnahmemoment_Leerlauf "Kupplungsmoment bei ASG- oder DQ-Getriebe; wird als Vorsteuermoment für LFR genutzt; Gesamtes Aufnahmemoment des Getriebes

0xFF = Fehler";
CM_ SG_ 1088 BZ_Getriebe1 "Freilaufender 4Bit-Botschaftszähler. BZ_Getriebe1 läuft synchron mit dem BZ_Getriebe_2 zur Sicherstellung der Synchronität.";
CM_ SG_ 1088 Codierung_MSG "Getriebe-Codierung im Motorsteuergerät ist in Ordnung

0x0 = Codierung niO
0x1 = Codierung iO";
CM_ SG_ 1088 EGS_Anforderung "QBit für Datum 'Inneres Sollmoment', Byte 4 wird damit gültig

0x0 = keine Anforderung
0x1 = EGS angefordert";
CM_ SG_ 1088 Fahrwiderstandsindex "Auf % Steigung am Berg normiert

0xFF = Fehler";
CM_ SG_ 1088 FSPE_Getriebe1 "Bei gesetztem Bit ist mindestens ein Kundendienstfehler eingetragen

0x0 = kein KD_Fehler eingetragen
0x1 = KD_Fehler eingetragen
";
CM_ SG_ 1088 Geschwindigkeit_halten "Bremse verhindert, daß das Fahrzeug beim Schalten des Längsgetriebes zu schnell wird. Nur Colorado!

0x0 = keine Anforderung
0x1 = Geschwindigkeit halten";
CM_ SG_ 1088 Geschwindigkeit_Umkehr "Bremse verhindert, daß das Fahrzeug beim Schalten des Längsgetriebes (Getriebe in N) zurückrollt. Nur Colorado!

0x0 = keine Bremsunterstützung
0x1 = Bremsunterstützung notwendig";
CM_ SG_ 1088 Getriebe_Notlauf "Die Signalspec der Gertiebenotlaufbits wurde nicht abwärtskompatibel verändert, neue Festlegung nach folgender Tabelle:

0x0 = kein Notlauf, Gangwechsel = 0, Zielgang erreicht =0
0x1 = kein Schalten
0x2 = Schalten nach N
0x3 = 50% Schalten
0x4 = Fah";
CM_ SG_ 1088 Getriebeinfo "CVT-Getriebe (VL30, ...) setzen Bit auf '1'; Sonstige Getriebe (bspw. Stufenautomat) geben '0' aus

0x0 = Stufenautomat
0x1 = CVT";
CM_ SG_ 1088 Inneres_Sollmotormoment "Getriebeeingriff an den Motor

0xFF = Fehler";
CM_ SG_ 1088 Klimakompressor_aus "Bit wird an Motor weitergeleitet, der Klima ausschaltet

0x0 = keine Anforderung
0x1 = Kompressor aus";
CM_ SG_ 1088 Kuehlleistung "0x0 = keine zusätzliche Kühlleistung
0x1 = Lüfterleistung um 20% erhöhen
0x2 = Lüfterleistung um 40% erhöhen, Wassertemperatur -10
0x3 = maximale Lüfterleistung; Wassertemperatur Senken (max)";
CM_ SG_ 1088 Motor_aus "Motor soll beim Umschalten des Bits ausgeschaltet (Mengenstellwerk stromlos) bzw. eingeschaltet werden; nur Direktschalter-Projekte bspw. ASG im W10 oder PQ24

0x0 = Motor startbereit
0x1 = Motor aus";
CM_ SG_ 1088 OBD_Status "Dieses Bit steuert die MIL-Lampe an (Motorsteuergerät reicht diese Info an Kombi weiter).

0x0 = MIL aus
0x1 = MIL ein";
CM_ SG_ 1088 Schaltung_aktiv "0x0 = keine Schaltung
0x1 = Schaltung aktiv";
CM_ SG_ 1088 SIB_Getriebe "Die Sleep-Bereitschaft wird nach KL15 aus durch Setzen dieses Bits signalisiert.

0x0 = CAN wird benötigt
0x1 = Sleep bereit";
CM_ SG_ 1088 Status_Wandlerschutz "Umschaltung permanente Leistungsreduzierung (Einspritzausblendung) oder Zündwinkelverstellung (Otto)

0x0 = kein Schutz
0x1 = Schutz angefordert";
CM_ SG_ 1088 Uebertragungsfunktion_8Bit "Übersetzungs-Verhältnis des Getriebes inkl. Antriebsstrang (ohne Berücksichtigung Wirkungsgrade bzw. Verlustmomente)

Bei AL: 

Übertragungsfunktion = mueWandler * ( nTurbine / nRad ), 
mit mueWandler = Wandlerverstärkung, nTurbine = Drehzahl am Wand";
CM_ SG_ 1088 Wandlerkupplung "Auch für Anfahrkupplung beim VL30 und Kupplung beim Ecodrive (geregelt bedeutet in diesem Fall die Kupplung ist nicht vollständig getrennt bzw. hat Schlupf) genutzt; bei starken Verstellwegen wird 'geöffnet' gesendet (VQ250)

0x0 = Wandlerkupplung geöff";
CM_ SG_ 1088 Zielgang "Zielgang, wenn Schaltung aktiv; ansonsten aktuell eingelegter Gang

0x0 = Gang P/N (ausgekuppelt)	
0x1 = Gang 1
0x2 = Gang 2
0x3 = Gang 3
0x4 = Gang 4
0x5 = Gang 5
0x6 = 1m Gang
0x7 = R
0x8 = Gang 6
0x9 = Gang 7
0xA ... 0xD = frei
0xE = Istga";

CM_ SG_ 1344 BZ_Getriebe2 "Freilaufender 4Bit-Botschaftszähler. BZ_Getriebe2 läuft synchron mit dem BZ_Getriebe_1 zur Sicherstellung der Synchronität.";
CM_ SG_ 1344 Drehzahlmesser_Daempfung "Beim DQ-Getriebe kann die Anzeigedämpfung des Drehzahlmessers beim Schalten geändert werden. 

0x0 = normale Dämpfung
0x1 = dynamische Dämpfung";
CM_ SG_ 1344 Gong_Kuppl_temp_Warn "Wichtiger Warnhinweis vom Getriebe: Textanzeige Kupplungstemperaturwarnung für DQ-Getriebe: 'Stop Anhalten Getriebe' (z.Zt. nur Vorhalt)";
CM_ SG_ 1344 Gradientenbegrenzung "Drehmomenten-Gradientenbegrenzung für Teillastanfahrten mit dem VL30-Getriebe und Standabkopplung beim 5HPx, 6HPx";
CM_ SG_ 1344 Leerlaufsolldrehzahl "Wunschvorgabewert vom CVT-Getriebe, 5HPx, 6HPx, DQ und ASG an Motor";
CM_ SG_ 1344 LFR_Adaption "Da das VL30-Getriebe im Stillstand unter gewissen Randbedingungen wechselnde Kupplungsmomente einstellt (z.B. Hillholder), sollte die Leerlaufauffüllungsadaption im Motorsteuergerät für diese Zustände gesperrt werden. 

";
CM_ SG_ 1344 Schubabschaltunterstuetzung "Wenn die SAS-Unterstützung aktiv ist, wird vom VL30-Steuergerät sichergestellt, daß die Kupplung nicht schlagartig geöffnet wird.";
CM_ SG_ 1344 Shift_Lock_Lampe "Wählhebel ist durch Shift-Lock-Funktion blockiert.";
CM_ SG_ 1344 Warnungsunterdrueckung "Unterdrueckung der dynamischen Öldruckwarnung und der Ansteuerung von Warnlampen durch das Getriebe (z.Zt. Generator und Öldrucklampe)";
CM_ SG_ 1344 WBA_Blinken "Dieses Bit steuert die Fehlerlampe an oder wird zum Blinken der WBA-Anzeige genutzt (5HP, 6HP, PNG, ASG, VL30)";
CM_ SG_ 1344 Zwischengasflag "Byte 4,5 und 6 sollen ausgeführt werden";

CM_ SG_ 1100 ax_Max_Getriebe "Maximale Sollbeschleunigung Getriebe. Information empfängt ACC2 ab C6/AU716.

0x58 = Init
0xFF = Fehlerwert
";
CM_ SG_ 1100 BZ_Getriebe6 "Freilaufender 4Bit-Botschaftszähler";
CM_ SG_ 1100 CHK_Getriebe6 "XOR über Summe aller Bytes siehe High-Speed-CAN-Lastenheft";
CM_ SG_ 1100 Getriebeverlustmoment_GRA_ACC "Verlustmoment des Lieferumfangs Getriebes (ohne separate Anbauteile wie Verteilergetriebe, Vorderachsdifferential) bezogen auf die Kurbelwelle (Moment das am Wandler ansteht) beim Stufenautomat wird die Wandlerverstärkung mit eingerechnet (beim Kupplungsa";
CM_ SG_ 1100 Turbinendrehzahl "Wird gesendet, um das Lastschlagverhalten bei Schaltvorgängen zu verbessern. 

0x3FFE = Init
0x3FFF = Fehler";

CM_ SG_ 1098 CVT_Anf_EPB "EPB setzt nach Plausibilisierung die Anforderung (schließen/öffnen) um";
CM_ SG_ 1098 CVT_Anf_EPB_gueltig "Anforderung an EPB gültig, d.h. Byte 2, Bit 5 ausführen!";
CM_ SG_ 1098 Dynamischer_Eingriff "Schalt-/Verstelleingriff";
CM_ SG_ 1098 Getriebeverlustmoment "Verlustmoment ohne Nutzanteil für ESP.";
CM_ SG_ 1098 Kuehlkreislaufventil_GME "In der ZKE verbauter Treiber steuert das Kühlkreislaufventil an";
CM_ SG_ 1098 Langfristiger_Eingriff "Voreilende Momenteninformation, um den Motor auf kommende Momentenanforderung (durch Motorsollmoment) vorzubereiten. In Verbindung mit den Status-Bits kann der Motor den passenden Betriebspunkt voreinstellen.";
CM_ SG_ 1098 QBit_Uebertragungsfunktion "0x0 = gültiger Wert
0x1 =  Ersatzwert oder Initwert
";
CM_ SG_ 1098 Schaltung_aktiv "Es findet aktuell eine Schaltung statt.";
CM_ SG_ 1098 Status_Dyn_Eingriff "Wenn während eines Zyklus einmal '0x7 = Fehler erkannt' gesetzt wurde, darf für den restlichen Zyklus (bis KL15 Aus/Ein) kein momentenerhöhender Eingriff mehr ausgeführt werden. ";
CM_ SG_ 1098 Uebertragungsfunktion_11Bit "Redundant zur Übertragungsfunktion_8Bit in Getriebe_1, eingeführt wegen höherer Auflösung

Übersetzungs-Verhältnis des Getriebes inkl. Antriebsstrang (ohne Berücksichtigung Wirkungsgrade bzw. Verlustmomente)

Bei AL: 

Übertragungsfunktion = mueWand";

CM_ SG_ 906 Abbrechen "0 = Tippschalter nicht betaetigt
1 = Tippschalter betaetigt
GRA : aus mit speichern
ACC : Soft aus";
CM_ SG_ 906 ACC_Zeitlueckenverstellung "00 = Taste nicht betaetigt
01 = Dist -1
10 = Dist +1
11 = nicht belegt

DIST -1 = Zeitluecke um 1 Stufe kleiner
DIST +1 = Zeitluecke um 1 Stufe groeßer";
CM_ SG_ 906 Bedienteil_Fehler "0 = in Ordnung
1 = Fehler Bedienteil";
CM_ SG_ 906 BZ_GRA_Neu "Botschaftszaehler, Definition im CAN-Lastenheft V 2.0";
CM_ SG_ 906 CHK_GRA_Neu "XOR über Summe aller Bytes
siehe High-Speed-CAN-Lastenheft";
CM_ SG_ 906 Codierinfo_SMLS "0 = GRA codiert
1 = ACC codiert";
CM_ SG_ 906 GRA_Hauptschalter "0 = Gerastet Aus; 1 = Ein";
CM_ SG_ 906 KurzTip_down "0 = Tippschalter nicht betaetigt
1 = Tippschalter betaetigt
GRA : Verzögern
ACC : Kurz Tip down";
CM_ SG_ 906 KurzTip_up "0 = Tippschalter nicht betaetigt
1 = Tippschalter betaetigt
GRA : Beschleunigen
ACC : Kurz Tip up";
CM_ SG_ 906 LangTip_down "0 = Tippschalter nicht betaetigt
1 = Tippschalter betaetigt
GRA : Verzögern
ACC : Lang Tip down";
CM_ SG_ 906 LangTip_up "0 = Tippschalter nicht betaetigt
1 = Tippschalter betaetigt
GRA : Beschleunigen
ACC : Lang Tip up";
CM_ SG_ 906 Sendercodierung "00 = Bordnetzsteuergeraet
01 = Lensäulenmodul
10 = Motor SG
11 = nicht belegt";
CM_ SG_ 906 Tip_Setzen "0 = Tippschalter nicht betaetigt
1 = Tippschalter betaetigt
ACC : Tippschalter Set";
CM_ SG_ 906 Tip_Wiederaufnahme "0 = Tippschalter nicht betaetigt
1 = Tippschalter betaetigt
ACC : Tippschalter Resume";
CM_ SG_ 906 Tiptronic_Limiter "0 = Limiter aus
1 = Limiter ein";
CM_ SG_ 906 Tiptronic_Tip_Down "0 = Tippschalter nicht betaetigt
1 = Tippschalter betaetigt";
CM_ SG_ 906 Tiptronic_Tip_Fehler "0 = i. O.
1 = Fehler erkannt";
CM_ SG_ 906 Tiptronic_Tip_Up "0 = Tippschalter nicht betaetigt
1 = Tippschalter betaetigt";

CM_ SG_ 1504 Ansteuerung_Kuehlerluefter "FFH  Fehler";
CM_ SG_ 1504 AussenTemp_aus_Wasserkasten "FFH  Fehler";
CM_ SG_ 1504 Aussentemp_Stossf_ungef "Dieses Signal wird im D3 nicht bedient; Klima sendet immer FFh";
CM_ SG_ 1504 Geblaeselastinfo "FFH  Fehler";
CM_ SG_ 1504 Heizung_ausgeschaltet "1 = beide Temperaturklappen stehen auf Kaltanschlag";
CM_ SG_ 1504 HeizungFrontscheibe_ein "1 = Frontscheibenheizung ein";
CM_ SG_ 1504 HeizungHeckscheibe_ein "1 = Heckscheibenheizung ein";
CM_ SG_ 1504 KaeltemittelDruck "FFH  Fehler";
CM_ SG_ 1504 Kaeltemitteldruck_alt "1 = veraltet, bei Kl 15 aus";
CM_ SG_ 1504 KD_Fehler_Klima "1 = min ein KD - Fehlerspeichereintrag vorhanden";
CM_ SG_ 1504 Kompressor_ein "1 = Kompressor ein";
CM_ SG_ 1504 Kompressorlastinfo "FFH  Fehler";
CM_ SG_ 1504 Kompressormoment_alt "1 = veraltet, bzw Ermittlung des Moments nicht moeglich
(z.B. keine Drehzahl, kein Kaeltemitteldruck)";
CM_ SG_ 1504 Restwaermefunktion "Status der Restwaermefunktion fuer das Motor-SG 
0 = nicht aktiviert; 1 = aktiviert";
CM_ SG_ 1504 SH_aktiv_Flag "1 = Standheizung ist bzw. war die letzte Stunde aktiv; 
Achtung : Bit ist in VW D1 anders belegt";
CM_ SG_ 1504 SH_MVW "0 = SH ohne Motorvorwärmung (kl. Kreis); 1 = SH mit Motorvorwärmung (gr. Kreis); Achtung : Bit ist in VW D1 anders belegt";
CM_ SG_ 1504 Signal_fuer_Drehzahlanhebung "1 = Drehzahlanhebung, Forderung an den Motor";
CM_ SG_ 1504 Temp_in_F "1 = Temperaturanzeige der Klimaanlage in °F
0 = Temperaturanzeige der Klimaanlage in °C
Temperatur auf Bus immer in °C !!!";
CM_ SG_ 1504 Zuheizer_ein "1 = Zuheizerfreigabe";
CM_ SG_ 1504 Zustand_Klima "Zustand der Klimasteuerung 0 =  Off; 1 = On";

CM_ SG_ 800 ABS_Lampe_ein "ABS-Sicherheits-Lampe wurde eingeschaltet.

0x0 = ABS Lampe aus
0x1 = ABS Lampe ein";
CM_ SG_ 800 ACC_Anzeigefehler "Bit wird bei einem ACC/ADR relevanten Fehler (Anzeige/Gong) gesetzt.

0x0 = kein Fehler
0x1 = ACC Anzeige defekt";
CM_ SG_ 800 ACC_Zusatzanzeige "Nur in ADR/ACC-Fahrzeugen: ACC Zusatzanzeige: 0 = aus / ungleich 0 = ein; angezeigte ADR-Zeitlücke wird auf 3 Bits begrenzt

0x0 = keine Anzeige
0x1 = Zeitlücke 1
...
0x7 = Zeitlücke 7
";
CM_ SG_ 800 Airbag_Lampe_ein "Airbag Sicherheits-Lampe wurde eingeschaltet 

0x0 = Airbag Lampe aus
0x1 = Airbag Lampe ein";
CM_ SG_ 800 angez_Geschw "Low Byte 6 (Bit 7,6), High Byte 7; Am Tacho angezeigte Geschwindigkeit inkl. Voreilung

0xFF im Byte7 = Fehler 
";
CM_ SG_ 800 ASR_ESP_Lampe_ein "ASR-/ESP-Sicherheits-Lampe wurde eingeschaltet 

0x0 = ASR/ESP Lampe aus
0x1 = ASR/ESP Lampe ein";
CM_ SG_ 800 BKL_ein "Sicherheits-Lampe Bremskontrolle wurde eingeschaltet; Besonderheit (VW PQ35/46): Lampe wird auch zur Handbremskontrolle (Audi: auch von EPB) und Bremsflüssigkeitswarnung (auch bei Audi) verwendet und vom Kombi aufgeprüft

0x0 = BKL aus
0x1 = BKL ein
";
CM_ SG_ 800 Bremsfluessigkeitswarnung "0x0 = iO
0x1 = Bremsflüssigkeitswarnung";
CM_ SG_ 800 BZ_Kombi1 "Freilaufender 4Bit-Botschaftszähler";
CM_ SG_ 800 Dyn_Oeldr_warn "Öldruckwarnung könnte auch vom Empfänger des Öldruckschalters generiert werden.

0x0 = iO
0x1 = Warnung";
CM_ SG_ 800 Einheit_angez_Geschw "Dem Fahrer wird die Geschwindigkeit in km/h oder in miles/hour angezeigt (konstanter Wert).

0x0 = km/h
0x1 = mph";
CM_ SG_ 800 FStatus_Tank "Nach 2 Sekunden liegt spätestens die Tankinfo vor

0x0 = Tankfüllstand i.O.
0x1 = Tankfüllstand n.i.O
";
CM_ SG_ 800 Handbremse_angezogen "Umgesetzt bei VW, Audi B6,B7; Nicht Audi-Fahrzeuge mit EPB (Audi D3, C6), wird wieder bedient im AU716; Sonderfall PQ46: Hardware-Eingang von EPB zur Ansteuerung der BKL-Lampe, auch im Betriebsfall BKL-Blinken;

0x0 = nicht angezogen
0x1 = angezogen
";
CM_ SG_ 800 Kombi_im_Stellgliedtest "Im Stellgliedtest werden auch Lampen angesteuert. Achtung: Rückmeldebits können gesetzt sein!

0x0 = nein
0x1 = ja";
CM_ SG_ 800 Konsistenz_ACC_Botschaften "Rückmeldung zum ACC-/ADR- System bzgl. CAN- Lastenheft

0x0 = iO
0x1 = Fehler";
CM_ SG_ 800 Kuehlmittelmangel "0x0 = iO
0x1 = Mangel

";
CM_ SG_ 800 Ladekontroll_Lampe "Kombi hat seine Ladekontroll-Lampe eingeschaltet (Empfänger: z.Zt. Batman) ; nicht PQ35/46, nicht Audi D3/C6

0x0 = Lampe aus
0x1 = Lampe ein";
CM_ SG_ 800 LDW_Anzeigefehler "Kombiinstrument hat Fehler erkannt

0x0 = kein Fehler
0x1 = Fehler";
CM_ SG_ 800 Lenkhilfe_Lampe_ein "Lenkhilfe-Sicherheits-Lampe wurde eingeschaltet

0x0 = Lenkhilfe Lampe aus
0x1 = Lenkhilfe Lampe ein";
CM_ SG_ 800 Oeldruck "Öldruckschalter

0x0 = kleiner als Schwellwert
0x1 = größer Schwellwert
";
CM_ SG_ 800 SIB_Kombi "SleepIndication-Bit zwischen Kombi und Gateway. Wird bedient z.Zt. nur Audi D3/C6, Audi AB2 und VW PQ46.
Bit hält im PQ35/46 den CAN-Infotainment wach

0x0 = CAN wird benötigt
0x1 = Sleep bereit
";
CM_ SG_ 800 Signalquelle_Geschwindigkeit "Die Fahrzeuggeschwindigkeit wird aus einem Tachogeber (eigener Hallgeber, eigener Reed-Kontakt, Fahrtenschreiber) oder aus der Referenzgeschwindigkeit vom ABS berechnet (nicht Audi D3/C6)

0x0 = Tachogeber
0x1 = ABS-Signal";
CM_ SG_ 800 SILA_gueltig "Rückmeldeinformation (Bit 1-6) ist gültig

0x0 = ungueltig
0x1 = gueltig";
CM_ SG_ 800 Tankinhalt "Restmenge 2 bzw. 2,5l nicht auflösbar

0x7F = Fehler

";
CM_ SG_ 800 Tankstop "Kombi hat Tankstop erkannt (Vorsicht: Wartezeit nach Klemme 15 ein berücksichtigen); Flag wird nach 5 Sekunden bei fahrendem Fahrzeug gelöscht

0x0 = kein Tankstop
0x1 = Tankstop erkannt";
CM_ SG_ 800 Tankwarnlampe "Fahrer wird gewarnt, z.Zt. liegt die Warnschwelle bei 7 Liter.

0x0 = Lampe aus
0x1 = Lampe ein";
CM_ SG_ 800 Tankwarnung "OBD-Schwelle, z. Zt. 15 %, applizierbar

0x0 = iO
0x1 = Tankwarnung";
CM_ SG_ 800 Vorgluehlampe_Kombi "Rückmeldeinformation für das Motorsteuergerät

0x0 = Lampe aus
0x1 = Lampe ein";
CM_ SG_ 800 Wakeup_Komfort "Das Audi PQ35-/ VW PQ46 Kombi kann durch Setzen dieses Bits bei aktivem Kombi-CAN den Komfort-CAN aufwecken oder wachhalten.

0x0 = keine Anforderung
0x1 = Wakeup Komfort
";

CM_ SG_ 1056 Aussentemp_gef "Realer Meßbereich ~  -45 bis +58 Grad; 

0x0 = nicht verbaut
0xFF = Fehler";
CM_ SG_ 1056 Aussentemp_ungef "Klima-Steuergerät kann aus dem Rohsignal eigene Plausibilitäten berechnen; 0 für nicht verbaut; im Hochlauf alter abgespeicherter Wert bis neuer vorliegt

0xFF = Fehler";
CM_ SG_ 1056 FSPE_Kombi "Bei gesetztem Bit ist mindestens ein Kundendienstfehler eingetragen

0x0 = kein Fehlerspeichereintrag
0x1 = mindestens ein Fehlerspeichereintrag";
CM_ SG_ 1056 FStatus_Aussentemp "n.i.O. steht für Fehlerwert, außerhalb des Meßbereichs (ungenau), nicht verbaut oder noch kein aktueller Wert

0x0 = iO
0x1 = niO";
CM_ SG_ 1056 FStatus_KL58d "n.i.O. steht für nicht verfügbar oder Ersatzwert in Bit 6..0 wird vorgegeben (Standard); VW Highline / Mini-DOT und Audi Kombis geben das mit dem Fototransister bewertete Signal aus

0x0 = KL58d iO
0x1 = KL58d niO";
CM_ SG_ 1056 FStatus_KL58s "n.i.O. steht für nicht verfügbar (z. Zt. bei VW) oder Ersatzwert in Bit 6..0 wird vorgegeben

0x0 = KL58s iO
0x1 = KL58s niO";
CM_ SG_ 1056 GRA_high_Anzeige "Kombi unterstützt die 'GRA High'-Anzeige, Sollgeschwindigkeit wird im Kombi angezeigt

0x0 = nein
0x1 = ja";
CM_ SG_ 1056 Klemme_58d "Display-Beleuchtung, Tastverhältnis in Prozent

0x7F = kein Ersatzwert";
CM_ SG_ 1056 Klemme_58s "Schalter-Beleuchtung (z.Zt. nur Audi) ,Tastverhältnis in Prozent

0x7F = kein Ersatzwert";
CM_ SG_ 1056 MFA_v_Einheit "Meldung an den Motor, mit welcher Einheit die GRA-Geschwindigkeit dargestellt wird, damit der Motor in der Botschaft Motor_8 die GRA-Wunschgeschwindigkeit anzeigeoptimiert ausgeben kann (Verhinderung von Werten, die kleiner Meilengröße entsprechen). (Im B";
CM_ SG_ 1056 Oelwarnschwelle_pOue "Ölwarnschwelle plus Offset überschritten (s. TOG1, Byte 8, Bit 1)

0x0 = nein
0x1 = ja

";
CM_ SG_ 1056 Temperatureinheit "Außentemperatur Anzeige im Kombi wird in Grad Celsius oder Fahrenheit gemacht

0x0 = °C
0x1 = °F";
CM_ SG_ 1056 TOG_nicht_verbaut "TOG ist nicht am Kombi angeschlossen, die TOG-Botschaft wird nicht vom Kombi gesendet. (Bit wird bei Audi nicht unterstützt und mit
0x0 ausgegeben).

0x0 = TOG verbaut
0x1 = TOG nicht verbaut";
CM_ SG_ 1056 Waschwasser_Warnung "Zusatzinfo zur Scheinwerferreinigungsanlage (z.Zt. nur Audi D3)

0x0 = keine Warnung
0x1 = Waschwasserwarnung aktiv";

CM_ SG_ 1312 Kilometerstand "Low Byte 6, High Byte 7 und in Byte 8 Bit 3..0 (additiv); Wertebereich geht bis (220 - 1), Fehler wird ausgegeben, falls Kilometerstand nicht restaurierbar

0xFFFFF = Fehler
";
CM_ SG_ 1312 Multiplex_Sprachvariante "


";
CM_ SG_ 1312 Mux_Code_Kombi3 "0x0 = Länder und Sprachvariante werden nur ausgegeben, wenn Sie im Kombi vorliegen (z.B. Highline)

0x1 = Plattforminformation

0x2 = mittlerer Reifenumfang in Millimeter (Byte 2 Bit 5,4 reserviert; Byte 2, Bit 0=>3 und Byte 1 Bit0=>7; Wertebereich 0 ";
CM_ SG_ 1312 Reifenumfang "Mittlerer Radumfang aus der K-Zahl gerechnet in Millimeter.  Byte 2 Bit 5,4 reserviert, Byte 2 Bit 3..0 und Byte 1 Bit 7..0; Wertebereich 0..4096 mm
";
CM_ SG_ 1312 Reset_Standzeit "0x0 = Standzeit iO
0x1 = KL30 war weg";
CM_ SG_ 1312 Schluesselinfo "15 Schlüssel-Infos; nur wenn WFS im Kombi implementiert ist!

0x0 = keine Info
0x1 = Schlüssel Nr.1
...
0xF = Schlüssel Nr.15
";
CM_ SG_ 1312 Standzeit "Low Byte 4, High Byte 5;
Standzeit in 4 Sekunden Auflösung; mit diesen 15 Bits läßt sich eine Zeit bis 36 Stunden, 24 Minuten und 28 Sekunden darstellen; 
Der Standzeitzähler wird mit KL15_Aus gestartet, er bleibt 2 Minuten vor einem Überlauf stehen, di";

CM_ SG_ 916 AFS_Fehlerlampe "Status der Fehlerlampe: aktuell anliegender Fehlerzustand des dynamischen oder statischen Kurvenlichtes

0x0 = AFS Fehlerlampe aus
0x1 = AFS Fehlerlampe ein";
CM_ SG_ 916 AFS_Fehlertext "Fehlertext wird im Kombi angezeigt (z.Zt nur bei VW)

0x0 = kein Text
0x1 = AFS ohne Funktion";
CM_ SG_ 916 AFS_LED_Blinkmode "Lampe soll im Warnfall mit 1Hz blinken, wenn das Bit gesetzt ist (z.Zt nur bei VW)

0x0 = kein Blinkmode angefordert
0x1 =Blinkmode angefordert";
CM_ SG_ 916 BZ_LWR_Zustand "Freilaufender 4Bit-Botschaftszähler";
CM_ SG_ 916 Einfederung_Karosse_hinten "Aktueller Höhensensorwert hinten (bei PQ35/46 links), oder bei Verbau Luftfederung aus der Niveau 2-Botschaft gespiegelt (M-Ausstattung C6/AU716, Serie D3, M-Ausstattung MangeRide TTNF).

0x7F = 0 mm
0xFE = nicht initialisiert
0xFF = Fehler";
CM_ SG_ 916 Einfederung_Karosse_vorn "Aktueller Höhensensorwert vorne (bei PQ35/46 links), oder bei Verbau Luftfederung aus der Niveau 2-Botschaft gespiegelt (M-Ausstattung C6/AU716, Serie D3, M-Ausstattung MagneRide TT NF).

0x7F = 0 mm
0xFE = nicht initialisiert
0xFF = Fehler
";
CM_ SG_ 916 Ersatzlichtfunktion_links "Bei aktivierter Ersatzlichtfunktion wird das Abblendlicht ausgeschaltet und eine Ersatzlichtquelle eingeschaltet (z.Zt. B7)

0x0 = keine Ersatzlichtfunktion links
0x1 = Ersatzlichtfunktion links";
CM_ SG_ 916 Ersatzlichtfunktion_rechts "Bei aktivierter Ersatzlichtfunktion wird das Abblendlicht ausgeschaltet und eine Ersatzlichtquelle eingeschaltet (z.Zt. B7)

0x0 = keine Ersatzlichtfunktion rechts
0x1 = Ersatzlichtfunktion rechts";
CM_ SG_ 916 FSPE_LWR_AFS "Bei gesetztem Bit ist mindestens ein Kundendienstfehler eingetragen

0x0 = kein KD_Fehler eingetragen
0x1 = KD_Fehler eingetragen
";
CM_ SG_ 916 LWR_AFS_Grundeinstellung "Grundeinstellung des Abblendlichtes am Lichteinstellkasten im Service oder Bandende mit Tester erfolgt! (auch für das dynamische Kurvernlicht)

0x0 = Grundeinstellung nicht erfolgt
0x1 = Grundeinstellung erfolgt";
CM_ SG_ 916 LWR_AFS_Parametrisierung "Parametrisierung wählt die Fahrzeugvariante und die AFS-Variante aus

0x0 = Parametrisierung nicht erfolgt
0x1 = Parametrisierung erfolgt
";
CM_ SG_ 916 LWR_Fehlerlampe "Status der Fehlerlampe: aktuell anliegender Fehlerzustand

0x0 = LWR Fehlerlampe aus
0x1 = LWR Fehlerlampe ein";
CM_ SG_ 916 LWR_Initialisierungslauf "Initialisierungslauf der Schrittmotoren, erfolgt defaultmäßig beim Motorstart

0x0 = Initialisierungslauf nicht erfolgt
0x1 = Initialisierungslauf erfolgt
";
CM_ SG_ 916 LWR_Modus "Schnelle oder langsame Regelart der LWR

0x0 = LWR statisch
0x1 = LWR dynamisch";
CM_ SG_ 916 LWR_Sicherheitsposition "LWR Sicherheitsposition beider Scheinwerfers

0x0 = Sicherheitsposition aus
0x1 = Sicherheitsposition ein";
CM_ SG_ 916 Sollwert_LD_EVG "100 % entsprechen 35 Watt. Die Last schaltet nur das ILM

0xFE = Init
0xFF = Fehler

";
CM_ SG_ 916 Stellung_Schrittmotoren "Position des Aktuators in Prozent des maximalen Stellweges; vor dem Initialisierungslauf (Motorstart) wird der Initwert ausgegeben: 
0% : tiefste Stellung (auf Block) des Schrittmotors;
100% : maximaler Verstellweg des Schrittmotors (nicht die Grenze de";

CM_ SG_ 640 Fahrerwunschmoment "Moment vor Filter, nutzbar zur Zug- / Schuberkennung beim Getriebe (beim TDI identisch mit innerem Moment)

0xFF = Fehler";
CM_ SG_ 640 Fahrpedalwert_DK_Poti "Bei EGAS wird hier der Fahrpedalwert ausgegeben; Maximum aus Rohsignal, gefiltertem Wert (TDI) und virtuellem Wert aus Kennfeld (bei aktiver integrierter GRA), Wert wird bei Doppelpotis auch bei einer defekten Poti-Spur ausgegeben, genutzter Wertebereich ";
CM_ SG_ 640 Fahrpedalwert_ungenau "Ersatzwert aus Modellrechnung oder Fehlerwert in Byte , Leergas- oder Kickdown-Info können betroffen sein. Qualifizierungsbit!

0x0 = Fahrpedal i.O
0x1 = Ersatzwert
";
CM_ SG_ 640 FStatus_Brems_Momeingr "Eingriffswunsch (ASR oder MSR) vom Bremsensteuergerät (ABS) kann nicht ausgeführt werden, weil im Motorsteuergerät ein statischer Fehler vorliegt oder die Funktion durch die Applikation abgeschaltet ist.

0x0 = erfüllbar
0x1 = statisch nicht erfüllbar";
CM_ SG_ 640 Inneres_Motormoment "Indiziertes Motormoment, d.h. idealisiertes berechnetes Moment ohne mechanische Verluste, aber mit externen Eingriffen.

0xFF = Fehler";
CM_ SG_ 640 Inneres_Motormoment_oeE "Indiziertes Motormoment ohne externe Eingriffe (ASR, MSR, Getriebe ...) aber inklusive integrierter GRA

0xFF = Fehler";
CM_ SG_ 640 Kickdownschalter "Wert '0' kann für nicht verbaut stehen, bei Doppelanalogpedalwertgeber ggfs. errechneter Wert.

0x0 = kein Kickdown
0x1 = Kickdown
";
CM_ SG_ 640 Kupplungsschalter "Nur Handschalter; aktiv, wenn Schalter verbaut; sonst konstant auf '0' gesetzt; Bit wird gesetzt, wenn Kupplungspedal nicht 
betätigt wird (Kupplungsschalter hoch), Triebstrang kann noch eingekuppelt sein.

0x0 = Schalter sagt ausgekuppelt
0x1 = Schal";
CM_ SG_ 640 Leergasinformation "Fahrpedal-Leergasschalter, Leergasinfo aus Fahrpedalwert oder Leerlaufschalter bei Drosselklappe (wird zur Freigabe der MSR-Funktion im ABS verwendet).

0x0 = kein Leergas
0x1 = Leergas
";
CM_ SG_ 640 Mech_Motor_Verlustmoment "Beinhaltet z.Zt. Reibung vom Motor und Klimakompressor, beim TDI z.T. auch die Generatorverluste

0xFF = Fehler";
CM_ SG_ 640 Mmot_Angabe_ungenau "Ungenaue Momentenangaben, weil die Momente aus Ersatzwerten berechnet wurden (z.B. HFM ausgefallen). Qualifizierungsbit für die Motormomente.

0x0 = nein (Werte iO)
0x1 = ja

";
CM_ SG_ 640 Motordrehzahl "Low Byte 3, High Byte 4; es wird der letzte aktuelle Meßwert gesendet, d.h. die Zeit für das letzte Arbeitsspiel (180 Grad KW beim 4 Zylinder) wird herangezogen; der Fehlerwert wird gesendet, wenn das Motorsteuergerät keine plausible Drehzahlinformation h";
CM_ SG_ 640 Time_Out_Bremse "500 ms Timeout auf Bremsen-Botschaft ist >= 1 mal aufgelaufen, Löschen des Bits nach Neustart (KL15).

0x0 = Empfang i.O.
0x1 = Time Out
";

CM_ SG_ 648 Ansteuerung_Klima "Zustand des Klimakompressors, d.h. Rückmeldung der bidirektionalen Schnittstelle (konventionell oder CAN)

0x0 = Klima aus
0x1 = Klima ein
";
CM_ SG_ 648 Begrenzungsmoment "Inneres maximal mögliches Moment bei einer Drehzahl (z.B. Rauchbegrenzung oder Fehlerfall)

0xFF = Fehler";
CM_ SG_ 648 Bremslichtschalter_Motor "Ungefiltertes Rohsignal des Bremslichtschalters

0x0 = kein Bremsen
0x1 = Bremse betätigt

";
CM_ SG_ 648 Bremstestschalter_Motor "Ein Empfänger kann BLS und BTS miteinander plausibilisieren ('0' für nicht verbaut). Fzg. ohne BTS (z.B. PQ46): Bit aus Bremse 1, Byte 2, Bit 3 Bremsdruckschwelle überschritten wird gespiegelt.

0x0 = kein Bremsen
0x1 = Bremse betätigt
";
CM_ SG_ 648 CAN_Stand "CAN-Version

Code    CAN-Stand

0x19 = CAN V4.3.5 (erste Version Audi D3)
0x1A = CAN V4.3.6 (erste Version Audi AB2)
0x1F= CAN V4.4.5 (zweite Version Audi D3)
0x26 = CAN V4.6.5 / V4.6.7 (dritte Version Audi D3  zu SOP / erste Version Audi C6)
0x27";
CM_ SG_ 648 FStatus_Kuehlmitteltemp_Motor "'niO' steht für Ersatzwert oder Fehlerwert in Byte2

0x0 = Temperatur iO
0x1 = Temperatur niO
";
CM_ SG_ 648 Getriebecode "Getriebecodierung des Motors 

0x0 = 5HP19
0x1 = 5HP24
0x2 = AG4
0x3 = VL300 (CVT)
0x4 = VQ250
0x5 = VQ35
0x6 = AG4 (Jatco, u.a.)
0x7 = AG5 (Jatco, u.a.)
0x8 = Automatisierte Kupplung
0x9 = Automatisierte Kupplung mit ASG
0xA = AG6 (Jatco, ZF ";
CM_ SG_ 648 GRA_auf_angez_Geschw "GRA regelt auf die im Kombi angezeigte Geschwindigkeit: 'GRA High Funktion'

0x0 = GRA regelt nicht auf angezeigte Geschwindigkeit
0x1 = GRA regelt auf angezeigte Geschwindigkeit";
CM_ SG_ 648 GRA_Status "0x0 = steht auch für nicht verbaut und ADR nicht zulässig; 
0x1 = bedeutet eingeschaltet, GRA vom Fahrer aktiviert und z.Zt. im Regelbetrieb oder ADR erlaubt; 
0x2 = Fahrer gibt mehr Gas als der Regler; 
0x3 = Fehler in Motorsteuerung oder Timeout oder";
CM_ SG_ 648 Kuehlmitteltemperatur "Motor-Kühlmitteltemperatur oder Ersatzwert; Initwert '0' ist außerhalb des Wertebereichs!

0xFF = Fehler";
CM_ SG_ 648 Leerlaufsolldrehzahl "Wunschvorgabewert vom CVT-Getriebe, 5HPx, 6HPx, DQ und ASG an Motor";
CM_ SG_ 648 MDI_max "Maximales Moment (Normierwert MDI)";
CM_ SG_ 648 Min_Mmot__ZW_Rueckn "Nur bei Ottomotoren (Diesel setzt Byte auf 0)

0xFF = Fehler";
CM_ SG_ 648 Motorcode "Motorcodierinformation






";
CM_ SG_ 648 Mux_Code_Motor2 "Multiplex-Code und Multiplex-Info sind verkettet; der Multiplex-Code wird nach 4 Übertragungen weitergeschaltet; dieser Mechanismus wiederholt sich somit nach 4x4 = 16 Umlaufzeiten";
CM_ SG_ 648 OBD2_Freeze_Frame "Motor zeigt den anderen OBD-pflichtigen Steuergeräten an, daß er einen OBD2 Freeze Frame gespeichert hat

0x0 = kein OBD Freeze Frame gespeichert
0x1 = OBD Freeze Frame gespeichert
";
CM_ SG_ 648 Soll_Geschw_GRA "Eingestellte GRA-Sollgeschwindigkeit

0xFF = Fehler";
CM_ SG_ 648 Status_Normalbetrieb "Normalbetrieb steht für KL15 ein, Initialisierungsphase abgeschlossen und kein Motorstartvorgang (aus Sicht des Motorsteuergerätes)

0x0 = kein Normalbetrieb
0x1 = Normalbetrieb
";

CM_ SG_ 896 Ansauglufttemperatur "In Fahrzeugen ohne Außentemperatur vom Kombi kann aus der Ansauglufttemperatur auf die Außentemperatur geschlossen werden. Beim SDI ist das mit einer gewissen Genauigkeit gegeben. Genutzt wird es vom ASG.

0xFF = Fehler";
CM_ SG_ 896 Fahrpedal_Rohsignal "Siehe Fahrpedalspezifikation

0xFF = Fehler";
CM_ SG_ 896 Fahrpedalgradient "Das Motorsteuergerät besitzt 2 analoge Fahrpedalsignale. Diese werden alle 4ms abgetastet. Entsprechend der Steuergeräte spezifischen Zykluszeit (Otto-Motor-Steuergeräte: alle10ms, Diesel-Motor-Steuergeräte: alle 20ms), dann die einzelnen Gradienten berec";
CM_ SG_ 896 Fahrpedalwert_ungenau "Ersatzwert in Byte 3, Leergas- oder Kickdown-Info können betroffen sein. Qualifizierungsbit für Fahrpedalwert.

0x0 = Fahrpedal iO
0x1 = Ersatzwert
";
CM_ SG_ 896 FStatus_Ansauglufttemp "Ersatzwert oder Fehlerwert. Qualifizierungsbit für die Ansauglufttemperatur. 

0x0 = Geber iO
0x1 = Ersatzwert
";
CM_ SG_ 896 Kein_EGas "Dieses Bit dient als Vorhalt, um die Motor3 Botschaft verwenden zu können, falls es in Zukunft ein Motorsteuergerät
ohne EGas geben wird, das diese Botschaft senden muß, z.Zt. kein Projekt.

0x0 = EGas Motor
0x1 = kein EGas Motor";
CM_ SG_ 896 Kein_Start_Stop "Start-Stop-Betrieb wird vom Motorsteuergerät verboten. (PQ24-3L-Autoprojekte)

0x0 = Start Stop erlaubt
0x1 = kein Start Stop
";
CM_ SG_ 896 Motordrehzahlbeeinflussung "Mit diesem Faktor kann das Motorsteuergerät die vom CVT-Getriebe einzustellende Sollmotodrehzahl beeinflussen. Im CVT-Steuergerät ist ein verbrauchsoptimales Kennfeld und ein abgasoptimiertes Kennfeld abgelegt. Mit dem Wert von 0-100% wird zwischen diesen";
CM_ SG_ 896 Motorwunschdrehzahl "Wenn das Bit 'Motorwunschdrehzahl Priorität' gesetzt wird, wird hier vom Motor-SG eine wegen Übertemperaturschutz oder wegen Motor internen Fehlern bedingte maximale Motordrehzahl ausgegeben, die das Getriebe-SG druch Rückschaltungen nicht überschreiten d";
CM_ SG_ 896 Motorwunschdrehzahlprioritaet "Motorwunschdrehzahl in Byte 7 ist als Zwang oder als Wunsch an das Getriebe zu interpretieren.

0x0 = Wunsch
0x1 = Zwang";
CM_ SG_ 896 Radwunschmoment "Low Byte 4; High Nibbel in Byte 5; der Wertebereich geht damit von 0 bis 4094 x 0,39 Prozent MDI (Byte 4 entspricht in der Darstellung den anderen Motormomenten, Nibbel in Byte 5 ist die Erweiterung).

0xFFF = Fehler";
CM_ SG_ 896 Signum_Fahrpedalgradient "Kennzeichnet das Vorzeichen des Signal 'Fahrpedalgradient' (Motor 3 Byte 8 Bit 7..0). Die Ausgabe erfolgt nur bei parallel statisch mit gesendetem Signal: 'Steuerungsbit Fahrpedalgradient' (Motor 3 Byte 1 Bit 5)

0x0 = Fahrpedalgradient positiv
0x1 = F";
CM_ SG_ 896 Signum_Rwmom "Vorzeichenbit des Radwunschmomentes

0x0 = Radwunschmoment positiv
0x1 = Radwunschmoment negativ";
CM_ SG_ 896 Steuerungsbit_Fahrpedalgradient "Nur wenn das Bit 'Steuerungsbit Fahrpedalgradient' gesetzt ist werden die beide Signale: 'Fahrpedalgradient' (Motor 3 Byte 8 Bit 7..0) und 'Vorzeichen Fahrpedalgradient' (Motor 3 Byte 3 Bit 6) vom ESP-Steuergerät zur Vorbefüllung der Radbremsen zur Verkür";
CM_ SG_ 896 Vorgluehmeldung "Bei kaltem Motor muß der Motor gestartet werden oder der nächste Start darf nur nach Vorglühung erfolgen.

0x0 = keine Anforderung
0x1 = Motor muß gestartet werden
";

CM_ SG_ 1152 Abgastyp "Bit 0:

0x0 = kein EOBD
0x1 = EOBD

Bit 1:

0x0 = kein OBD (US-Norm)
0x1 = OBD (US-Norm)";
CM_ SG_ 1152 Anlasser_Ausspuren "Bit wird gesetzt, wenn der Motorhochlauf ohne Anlasserunterstützung beendet werden kann oder ein Start-Timeout erreicht wurde.

0x0 = Motor läuft nicht stabil
0x1 = Anlasser ausspuren (Motor läuft stabil)";
CM_ SG_ 1152 Anlasser_Freigabe "Bit wird gesetzt, wenn der Motor beim Automatikstart gestartet werden darf (Motorstillstand, Emissionsmaßnahmen sind erfüllt).

0x0 = Start nicht zulässig
0x1 = Startfreigabe";
CM_ SG_ 1152 CHK_Motor5 "XOR über Summe aller Bytes siehe High-Speed-CAN-Lastenheft";
CM_ SG_ 1152 Doppelte_Momente "Normwert MDI wird verdoppelt. Konstante für jeden Motor.";
CM_ SG_ 1152 Drehzahl_max_Drehmoment "Drehzahl bei maximalem Drehmoment";
CM_ SG_ 1152 Drehzahlmesser_Daempfung "Beim DQ-Getriebe kann die Anzeigedämpfung des Drehzahlmessers beim Schalten geändert werden. 

0x0 = normale Dämpfung
0x1 = dynamische Dämpfung";
CM_ SG_ 1152 EGas_Lampe "EGas Systemlampe (EPC) im Kombi, z.Zt. nur Otto-Motoren

0x0 = Lampe aus
0x1 = Lampe ein";
CM_ SG_ 1152 FStatus_BKU_Pumpe "Der Defekt der elektrischen Pumpe zur Verbesserung der Unterdruckversorgung wird angezeigt (nur Porsche Colorado)

0x0 = iO oder nicht verbaut 
0x1 = niO";
CM_ SG_ 1152 GRA_Hauptschalter "Schalter gerastet ein (bei Taster der Ausgang des Status Flipflops) macht GRA Lampe an: GRA ist aktivierbar; Porsche: Anforderung GRA/Bereitschafts-Lampe an/aus";
CM_ SG_ 1152 Heissleuchte "Ansteuerung der Kühlwassertemperatur-Heißleuchte (Sensor nur noch am Motorsteuergerät): Temperaturschaltschwellen mit Hysterese (bei VW D1/Colorado Kombi derzeit noch nicht genutzt).

0x0 = Lampe aus
0x1 = Lampe ein";
CM_ SG_ 1152 HLVW_Motor "Klimaanlage muß aufgrund einer Übertemperaturerkennung abgeschaltet werden (Schwelle entspricht der Heißleuchtenvorwarnungsschwelle)

0x0 = keine Warnung
0x1 = Vorwarnung";
CM_ SG_ 1152 Interlock_Schalter "Der Interlockschalter muß beim Handschalter betätigt sein, damit ein Motorstart erlaubt ist (z.Zt. nur bei Audi-Handschalter mit Automatikschalter).

0x0 = Interlockschalter nicht betätigt
0x1 = Interlockschalter betätigt";
CM_ SG_ 1152 Kennfeldkuehlung "Die Kennfeldkühlung ist in diesem Fahrzeug verbaut und hat keinen Systemfehler

0x0 = keine Kennfeldkühlung vorhanden
0x1 = Lampe ein";
CM_ SG_ 1152 KK_aus "Motorsteuergerät schaltet Klimakompressor aus

0x0 = keine Anforderung
0x1 = Klimakompressor ausschalten";
CM_ SG_ 1152 KK_Leistungsreduzierung "Klimakompressor-Leistungsreduzierung

0x0 = keine Leistungsreduzierung
0x1 = Leistungsreduzierung gewünscht";
CM_ SG_ 1152 Kraftstoffverbrauchsignal "Motorsteuergerätinterner Verbrauchszähler, der vom Kombi zyklisch ausgelesen wird, um die Einspritzmenge zur Verbrauchsmessung aufzusummieren; aus diesem Zählerstand werden Momentan- und Durchschnittsverbrauch berechnet; das Überlauf-Bit ist zu berücksich";
CM_ SG_ 1152 Kuehlerluefteransteuerung "Istzustand der Kühlerlüfteransteuerung über die PWM Schnittstelle; Lüfterstufen (z.B. 14) werden in Prozente umgerechnet; Werte >100% sind unzulässig

0xFF = Fehler";
CM_ SG_ 1152 Ladekontroll_Lampe "Generator-Ladekontroll-Lampe (neue Generatorschnittstelle)";
CM_ SG_ 1152 Lampe_Tankdeckelwarnung "Ansteuerung Tankdeckel-Warnlampe Kombiinstrument (nur Ottomotoren)

0x0 = Lampe aus
0x1 = Lampe ein";
CM_ SG_ 1152 Max_Drehmoment_630Nm "Maximales Drehmoment des Motors";
CM_ SG_ 1152 Motortext_Bits "0000  keine Fehlertextanzeige im Kombi
xxx1  Motorsteuerung Werkstatt
xx1x  nicht bedient - bislang 'Abgas Werkstatt' - aus Gesetzesgründen nicht mehr verwenden
x1xx  Fehler im Kraftstoffsystem
1xxx  Partikelfilter benötigt Regeneration
";
CM_ SG_ 1152 Motortyp "Bit 0..3:

0x2 = Zweizylinder
0x3 = Dreizylinder
0x4 = Vierzylinder
0x5 = Fünfzylinder
0x6 = Sechszylinder
0x8 = Achtzylinder
0xA = Zehnzylinder
0xC = Zwölfzylinder
0xD = Fünfzehnzylinder
0xE = Sechzehnzylinder
0xF = Achtzehnzylinder

Bit 4:";
CM_ SG_ 1152 Mux_Code_Motor5 "Motor Multiplex-Code und Multiplex-Info sind verkettet; der Multiplex-Code wird nach 4 Übertragungen weitergeschaltet; dieser Mechanismus wiederholt sich somit nach 4x4 = 16 Umlaufzeiten";
CM_ SG_ 1152 OBD2_Lampe "OBD bzw. MIL-Lampe wird vom Motorsteuergerät angesteuert, die Information in der Getriebe1 Botschaft (Byte 6, Bit 7...4) wird 
vom Motorsteuergerät an das Kombi weitergereicht

0x0 = Lampe aus
0x1 = Lampe ein";
CM_ SG_ 1152 Partikelfilter_Lampe "Partikelfilter-Lampe wird eingeschaltet

0x0 = Lampe aus
0x1 = Lampe ein";
CM_ SG_ 1152 Textbit_Tankdeckelwarn "Anzeige im Kombiinstrument, daß Tankdeckel offen sein könnte (nur Ottomotoren)

0x0 = Lampe aus
0x1 = Lampe ein";
CM_ SG_ 1152 Typ_Startersteuerung "Automatikstart wird gesetzt, wenn das Motorsteuergerät den Motorstart automatisch steuert

0x0 = Start über BSG/Kessy oder Fahrer direkt
0x1 = Automatikstart";
CM_ SG_ 1152 Verbrauch_Ueberlauf "Der motorsteuergeräteinterne Verbrauchszähler ist mindestens einmal übergelaufen. Dieses Bit wird genutzt, um erkennen zu können, daß das Motorsteuergerät aus dem Reset-Zustand hochläuft.

0x0 = kein Ueberlauf
0x1 = Kraftstoffverbrauchsignale mindesten";
CM_ SG_ 1152 Vorgluehlampe_Motor "Diesel-Vorglühlampe und Diesel-Systemlampe";
BA_DEF_ BO_  "GenMsgAutoGenDsp" ENUM "No", "Yes";
BA_DEF_ BO_  "GenMsgAutoGenSnd" ENUM "No", "Yes";
BA_DEF_ BO_  "GenMsgCycleTime" INT 0 65535;
BA_DEF_ BO_  "GenMsgCycleTimeFast" INT 0 65535;
BA_DEF_ BO_  "GenMsgDelayTime" INT 0 100000;
BA_DEF_ BO_  "GenMsgILSupport" ENUM "No", "Yes";
BA_DEF_ BO_  "GenMsgSendType" ENUM "cyclicX", "spontanX", "cyclicIfActiveX", "spontanWithDelay", "cyclicAndSpontanX", "cyclicAndSpontanWithDelay", "spontanWithRepetition", "cyclicIfActiveAndSpontanWD", "cyclicIfActiveFast", "cyclicWithRepeatOnDemand";
BA_DEF_ BO_  "GenMsgStartDelayTime" INT 0 100000;
BA_DEF_ BO_  "NmMessage" ENUM "No", "Yes";
BA_DEF_ BO_  "NWM-Botschaft" ENUM "No", "Yes";
BA_DEF_ BO_  "VAGTP20_API" HEX 0 255;
BA_DEF_ BO_  "VAGTP20_DynConnection" ENUM "No", "Yes";
BA_DEF_ BO_  "VAGTP20_DynSetup" ENUM "No", "Yes";
BA_DEF_ BO_  "VAGTP20_StatConnection" ENUM "No", "Yes";
BA_DEF_ SG_  "GenSigAltSetting" STRING;
BA_DEF_ SG_  "GenSigAssignSetting" STRING;
BA_DEF_ SG_  "GenSigAutoGenDsp" ENUM "No", "Yes";
BA_DEF_ SG_  "GenSigAutoGenSnd" ENUM "No", "Yes";
BA_DEF_ SG_  "GenSigConditionalSend" STRING;
BA_DEF_ SG_  "GenSigEnvVarType" ENUM "int", "float", "undef";
BA_DEF_ SG_  "GenSigEVName" STRING;
BA_DEF_ SG_  "GenSigInactiveValue" INT -2147483648 2147483647;
BA_DEF_ SG_  "GenSigPostIfSetting" STRING;
BA_DEF_ SG_  "GenSigPostSetting" STRING;
BA_DEF_ SG_  "GenSigPreIfSetting" STRING;
BA_DEF_ SG_  "GenSigPreSetting" STRING;
BA_DEF_ SG_  "GenSigSendType" ENUM "Cyclic", "OnWrite", "OnWriteWithRepetition", "OnChange", "OnChangeWithRepetition", "IfActive", "IfActiveWithRepetition", "NoSigSendType";
BA_DEF_ SG_  "GenSigStartValue" INT -2147483648 2147483647;
BA_DEF_ SG_  "NWM-WakeupAllowed" ENUM "No", "Yes";
BA_DEF_ SG_  "GenSigTimeoutMsg_ESP8_C6" HEX 0 2047;
BA_DEF_ SG_  "GenSigTimeoutMsg_DME_EDC16CP3000" HEX 0 2047;
BA_DEF_ SG_  "GenSigTimeoutMsg_DME_ME7_MED9_C6" HEX 0 2047;
BA_DEF_ SG_  "GenSigTimeoutMsg_DME_SIMOS6_C6" HEX 0 2047;
BA_DEF_ SG_  "GenSigTimeoutMsg__6HP_C6" HEX 0 2047;
BA_DEF_ SG_  "GenSigTimeoutMsg_Gateway_C6" HEX 0 2047;
BA_DEF_ SG_  "GenSigTimeoutMsg_EPB_C6" HEX 0 2047;
BA_DEF_ SG_  "GenSigTimeoutMsg__4CL_C6" HEX 0 2047;
BA_DEF_ SG_  "GenSigTimeoutMsg_Airbag_C6" HEX 0 2047;
BA_DEF_ SG_  "GenSigTimeoutMsg_LWR_AFS_C6" HEX 0 2047;
BA_DEF_ SG_  "GenSigTimeoutMsg_LWS_C6" HEX 0 2047;
BA_DEF_ SG_  "GenSigTimeoutMsg_CVT_C6" HEX 0 2047;
BA_DEF_ SG_  "GenSigTimeoutMsg_DME_Slave" HEX 0 2047;
BA_DEF_DEF_  "GenMsgAutoGenDsp" "Yes";
BA_DEF_DEF_  "GenMsgAutoGenSnd" "Yes";
BA_DEF_DEF_  "GenMsgCycleTime" 0;
BA_DEF_DEF_  "GenMsgCycleTimeFast" 0;
BA_DEF_DEF_  "GenMsgDelayTime" 0;
BA_DEF_DEF_  "GenMsgILSupport" "";
BA_DEF_DEF_  "GenMsgSendType" "cyclicX";
BA_DEF_DEF_  "GenMsgStartDelayTime" 0;
BA_DEF_DEF_  "NmMessage" "No";
BA_DEF_DEF_  "NWM-Botschaft" "No";
BA_DEF_DEF_  "VAGTP20_API" 0;
BA_DEF_DEF_  "VAGTP20_DynConnection" "No";
BA_DEF_DEF_  "VAGTP20_DynSetup" "No";
BA_DEF_DEF_  "VAGTP20_StatConnection" "No";
BA_DEF_DEF_  "GenSigAltSetting" "";
BA_DEF_DEF_  "GenSigAssignSetting" "";
BA_DEF_DEF_  "GenSigAutoGenDsp" "";
BA_DEF_DEF_  "GenSigAutoGenSnd" "";
BA_DEF_DEF_  "GenSigConditionalSend" "";
BA_DEF_DEF_  "GenSigEnvVarType" "undef";
BA_DEF_DEF_  "GenSigEVName" "";
BA_DEF_DEF_  "GenSigInactiveValue" 0;
BA_DEF_DEF_  "GenSigPostIfSetting" "";
BA_DEF_DEF_  "GenSigPostSetting" "";
BA_DEF_DEF_  "GenSigPreIfSetting" "";
BA_DEF_DEF_  "GenSigPreSetting" "";
BA_DEF_DEF_  "GenSigSendType" "Cyclic";
BA_DEF_DEF_  "GenSigStartValue" 0;
BA_DEF_DEF_  "NWM-WakeupAllowed" "";
BA_DEF_DEF_  "GenSigTimeoutMsg_ESP8_C6" 0;
BA_DEF_DEF_  "GenSigTimeoutMsg_DME_EDC16CP3000" 0;
BA_DEF_DEF_  "GenSigTimeoutMsg_DME_ME7_MED9_C6" 0;
BA_DEF_DEF_  "GenSigTimeoutMsg_DME_SIMOS6_C6" 0;
BA_DEF_DEF_  "GenSigTimeoutMsg__6HP_C6" 0;
BA_DEF_DEF_  "GenSigTimeoutMsg_Gateway_C6" 0;
BA_DEF_DEF_  "GenSigTimeoutMsg_EPB_C6" 0;
BA_DEF_DEF_  "GenSigTimeoutMsg__4CL_C6" 0;
BA_DEF_DEF_  "GenSigTimeoutMsg_Airbag_C6" 0;
BA_DEF_DEF_  "GenSigTimeoutMsg_LWR_AFS_C6" 0;
BA_DEF_DEF_  "GenSigTimeoutMsg_LWS_C6" 0;
BA_DEF_DEF_  "GenSigTimeoutMsg_CVT_C6" 0;
BA_DEF_DEF_  "GenSigTimeoutMsg_DME_Slave" 0;
BA_ "GenMsgAutoGenSnd" BO_ 1088 0;
BA_ "GenMsgCycleTime" BO_ 1088 10;
BA_ "GenMsgILSupport" BO_ 1088 0;
BA_ "GenMsgAutoGenSnd" BO_ 1344 0;
BA_ "GenMsgCycleTime" BO_ 1344 10;
BA_ "GenMsgILSupport" BO_ 1344 0;
BA_ "GenMsgCycleTime" BO_ 1100 20;
BA_ "GenMsgILSupport" BO_ 1100 0;
BA_ "GenMsgAutoGenSnd" BO_ 1098 0;
BA_ "GenMsgCycleTime" BO_ 1098 10;
BA_ "GenMsgILSupport" BO_ 1098 0;
BA_ "GenMsgAutoGenSnd" BO_ 906 0;
BA_ "GenMsgCycleTime" BO_ 906 20;
BA_ "GenMsgILSupport" BO_ 906 0;
BA_ "GenMsgCycleTime" BO_ 1490 1000;
BA_ "GenMsgILSupport" BO_ 1490 0;
BA_ "GenMsgAutoGenSnd" BO_ 2016 0;
BA_ "GenMsgILSupport" BO_ 2016 0;
BA_ "GenMsgSendType" BO_ 2016 7;
BA_ "GenMsgAutoGenSnd" BO_ 2017 0;
BA_ "GenMsgILSupport" BO_ 2017 0;
BA_ "GenMsgSendType" BO_ 2017 7;
BA_ "GenMsgAutoGenSnd" BO_ 2018 0;
BA_ "GenMsgILSupport" BO_ 2018 0;
BA_ "GenMsgSendType" BO_ 2018 7;
BA_ "GenMsgAutoGenSnd" BO_ 2019 0;
BA_ "GenMsgILSupport" BO_ 2019 0;
BA_ "GenMsgSendType" BO_ 2019 7;
BA_ "GenMsgAutoGenSnd" BO_ 2020 0;
BA_ "GenMsgILSupport" BO_ 2020 0;
BA_ "GenMsgSendType" BO_ 2020 7;
BA_ "GenMsgAutoGenSnd" BO_ 2021 0;
BA_ "GenMsgILSupport" BO_ 2021 0;
BA_ "GenMsgSendType" BO_ 2021 7;
BA_ "GenMsgAutoGenSnd" BO_ 2022 0;
BA_ "GenMsgILSupport" BO_ 2022 0;
BA_ "GenMsgSendType" BO_ 2022 7;
BA_ "GenMsgAutoGenSnd" BO_ 2023 0;
BA_ "GenMsgILSupport" BO_ 2023 0;
BA_ "GenMsgSendType" BO_ 2023 7;
BA_ "GenMsgAutoGenSnd" BO_ 2015 0;
BA_ "GenMsgILSupport" BO_ 2015 0;
BA_ "GenMsgSendType" BO_ 2015 7;
BA_ "GenMsgAutoGenSnd" BO_ 2024 0;
BA_ "GenMsgILSupport" BO_ 2024 0;
BA_ "GenMsgSendType" BO_ 2024 7;
BA_ "GenMsgAutoGenSnd" BO_ 2025 0;
BA_ "GenMsgILSupport" BO_ 2025 0;
BA_ "GenMsgSendType" BO_ 2025 7;
BA_ "GenMsgAutoGenSnd" BO_ 2026 0;
BA_ "GenMsgILSupport" BO_ 2026 0;
BA_ "GenMsgSendType" BO_ 2026 7;
BA_ "GenMsgAutoGenSnd" BO_ 2027 0;
BA_ "GenMsgILSupport" BO_ 2027 0;
BA_ "GenMsgSendType" BO_ 2027 7;
BA_ "GenMsgAutoGenSnd" BO_ 2028 0;
BA_ "GenMsgILSupport" BO_ 2028 0;
BA_ "GenMsgSendType" BO_ 2028 7;
BA_ "GenMsgAutoGenSnd" BO_ 2029 0;
BA_ "GenMsgILSupport" BO_ 2029 0;
BA_ "GenMsgSendType" BO_ 2029 7;
BA_ "GenMsgAutoGenSnd" BO_ 2030 0;
BA_ "GenMsgILSupport" BO_ 2030 0;
BA_ "GenMsgSendType" BO_ 2030 7;
BA_ "GenMsgAutoGenSnd" BO_ 2031 0;
BA_ "GenMsgILSupport" BO_ 2031 0;
BA_ "GenMsgSendType" BO_ 2031 7;
BA_ "GenMsgAutoGenSnd" BO_ 1504 0;
BA_ "GenMsgCycleTime" BO_ 1504 100;
BA_ "GenMsgILSupport" BO_ 1504 0;
BA_ "GenMsgAutoGenSnd" BO_ 800 0;
BA_ "GenMsgCycleTime" BO_ 800 20;
BA_ "GenMsgILSupport" BO_ 800 0;
BA_ "GenMsgAutoGenSnd" BO_ 1056 0;
BA_ "GenMsgCycleTime" BO_ 1056 200;
BA_ "GenMsgILSupport" BO_ 1056 0;
BA_ "GenMsgAutoGenSnd" BO_ 1312 0;
BA_ "GenMsgCycleTime" BO_ 1312 200;
BA_ "GenMsgILSupport" BO_ 1312 0;
BA_ "GenMsgAutoGenSnd" BO_ 916 0;
BA_ "GenMsgCycleTime" BO_ 916 100;
BA_ "GenMsgILSupport" BO_ 916 0;
BA_ "GenMsgAutoGenSnd" BO_ 194 0;
BA_ "GenMsgCycleTime" BO_ 194 10;
BA_ "GenMsgILSupport" BO_ 194 0;
BA_ "GenMsgAutoGenSnd" BO_ 1984 0;
BA_ "GenMsgILSupport" BO_ 1984 0;
BA_ "GenMsgSendType" BO_ 1984 7;
BA_ "GenMsgAutoGenSnd" BO_ 1478 0;
BA_ "GenMsgCycleTime" BO_ 1478 100;
BA_ "GenMsgILSupport" BO_ 1478 0;
BA_ "GenMsgSendType" BO_ 1478 2;
BA_ "GenMsgAutoGenSnd" BO_ 1986 0;
BA_ "GenMsgILSupport" BO_ 1986 0;
BA_ "GenMsgSendType" BO_ 1986 7;
BA_ "GenMsgAutoGenSnd" BO_ 640 0;
BA_ "GenMsgCycleTime" BO_ 640 20;
BA_ "GenMsgCycleTimeFast" BO_ 640 10;
BA_ "GenMsgILSupport" BO_ 640 0;
BA_ "GenMsgAutoGenSnd" BO_ 648 0;
BA_ "GenMsgCycleTime" BO_ 648 20;
BA_ "GenMsgCycleTimeFast" BO_ 648 10;
BA_ "GenMsgILSupport" BO_ 648 0;
BA_ "GenMsgAutoGenSnd" BO_ 896 0;
BA_ "GenMsgCycleTime" BO_ 896 20;
BA_ "GenMsgCycleTimeFast" BO_ 896 10;
BA_ "GenMsgILSupport" BO_ 896 0;
BA_ "GenMsgAutoGenSnd" BO_ 1152 0;
BA_ "GenMsgCycleTime" BO_ 1152 20;
BA_ "GenMsgILSupport" BO_ 1152 0;
BA_ "GenSigAutoGenDsp" SG_ 1088 Aufnahmemoment_Leerlauf 0;
BA_ "GenSigAutoGenSnd" SG_ 1088 Aufnahmemoment_Leerlauf 0;
BA_ "GenSigSendType" SG_ 1088 Aufnahmemoment_Leerlauf 7;
BA_ "NWM-WakeupAllowed" SG_ 1088 Aufnahmemoment_Leerlauf 0;
BA_ "GenSigTimeoutMsg_DME_EDC16CP3000" SG_ 1088 Aufnahmemoment_Leerlauf 1088;
BA_ "GenSigTimeoutMsg_DME_ME7_MED9_C6" SG_ 1088 Aufnahmemoment_Leerlauf 1088;
BA_ "GenSigTimeoutMsg_DME_SIMOS6_C6" SG_ 1088 Aufnahmemoment_Leerlauf 1088;
BA_ "GenSigTimeoutMsg_Gateway_C6" SG_ 1088 Aufnahmemoment_Leerlauf 1088;
BA_ "GenSigAutoGenDsp" SG_ 1088 BZ_Getriebe1 0;
BA_ "GenSigAutoGenSnd" SG_ 1088 BZ_Getriebe1 0;
BA_ "GenSigSendType" SG_ 1088 BZ_Getriebe1 7;
BA_ "NWM-WakeupAllowed" SG_ 1088 BZ_Getriebe1 0;
BA_ "GenSigTimeoutMsg_DME_ME7_MED9_C6" SG_ 1088 BZ_Getriebe1 1088;
BA_ "GenSigTimeoutMsg_DME_SIMOS6_C6" SG_ 1088 BZ_Getriebe1 1088;
BA_ "GenSigTimeoutMsg_EPB_C6" SG_ 1088 BZ_Getriebe1 1088;
BA_ "GenSigTimeoutMsg_ESP8_C6" SG_ 1088 BZ_Getriebe1 1088;
BA_ "GenSigTimeoutMsg_Gateway_C6" SG_ 1088 BZ_Getriebe1 1088;
BA_ "GenSigAutoGenDsp" SG_ 1088 Codierung_MSG 0;
BA_ "GenSigAutoGenSnd" SG_ 1088 Codierung_MSG 0;
BA_ "GenSigSendType" SG_ 1088 Codierung_MSG 7;
BA_ "NWM-WakeupAllowed" SG_ 1088 Codierung_MSG 0;
BA_ "GenSigTimeoutMsg_DME_SIMOS6_C6" SG_ 1088 Codierung_MSG 1088;
BA_ "GenSigTimeoutMsg_ESP8_C6" SG_ 1088 Codierung_MSG 1088;
BA_ "GenSigTimeoutMsg_Gateway_C6" SG_ 1088 Codierung_MSG 1088;
BA_ "GenSigAutoGenDsp" SG_ 1088 EGS_Anforderung 0;
BA_ "GenSigAutoGenSnd" SG_ 1088 EGS_Anforderung 0;
BA_ "GenSigSendType" SG_ 1088 EGS_Anforderung 7;
BA_ "NWM-WakeupAllowed" SG_ 1088 EGS_Anforderung 0;
BA_ "GenSigTimeoutMsg_DME_EDC16CP3000" SG_ 1088 EGS_Anforderung 1088;
BA_ "GenSigTimeoutMsg_DME_ME7_MED9_C6" SG_ 1088 EGS_Anforderung 1088;
BA_ "GenSigTimeoutMsg_DME_SIMOS6_C6" SG_ 1088 EGS_Anforderung 1088;
BA_ "GenSigTimeoutMsg_Gateway_C6" SG_ 1088 EGS_Anforderung 1088;
BA_ "GenSigAutoGenDsp" SG_ 1088 Fahrwiderstandsindex 0;
BA_ "GenSigAutoGenSnd" SG_ 1088 Fahrwiderstandsindex 0;
BA_ "GenSigSendType" SG_ 1088 Fahrwiderstandsindex 7;
BA_ "GenSigStartValue" SG_ 1088 Fahrwiderstandsindex 127;
BA_ "NWM-WakeupAllowed" SG_ 1088 Fahrwiderstandsindex 0;
BA_ "GenSigTimeoutMsg_DME_EDC16CP3000" SG_ 1088 Fahrwiderstandsindex 1088;
BA_ "GenSigTimeoutMsg_DME_ME7_MED9_C6" SG_ 1088 Fahrwiderstandsindex 1088;
BA_ "GenSigTimeoutMsg_DME_SIMOS6_C6" SG_ 1088 Fahrwiderstandsindex 1088;
BA_ "GenSigTimeoutMsg_Gateway_C6" SG_ 1088 Fahrwiderstandsindex 1088;
BA_ "GenSigAutoGenDsp" SG_ 1088 FSPE_Getriebe1 0;
BA_ "GenSigAutoGenSnd" SG_ 1088 FSPE_Getriebe1 0;
BA_ "GenSigSendType" SG_ 1088 FSPE_Getriebe1 7;
BA_ "NWM-WakeupAllowed" SG_ 1088 FSPE_Getriebe1 0;
BA_ "GenSigTimeoutMsg_Gateway_C6" SG_ 1088 FSPE_Getriebe1 1088;
BA_ "GenSigAutoGenDsp" SG_ 1088 Geschwindigkeit_halten 0;
BA_ "GenSigAutoGenSnd" SG_ 1088 Geschwindigkeit_halten 0;
BA_ "GenSigSendType" SG_ 1088 Geschwindigkeit_halten 7;
BA_ "NWM-WakeupAllowed" SG_ 1088 Geschwindigkeit_halten 0;
BA_ "GenSigTimeoutMsg_Gateway_C6" SG_ 1088 Geschwindigkeit_halten 1088;
BA_ "GenSigAutoGenDsp" SG_ 1088 Geschwindigkeit_Umkehr 0;
BA_ "GenSigAutoGenSnd" SG_ 1088 Geschwindigkeit_Umkehr 0;
BA_ "GenSigSendType" SG_ 1088 Geschwindigkeit_Umkehr 7;
BA_ "NWM-WakeupAllowed" SG_ 1088 Geschwindigkeit_Umkehr 0;
BA_ "GenSigTimeoutMsg_Gateway_C6" SG_ 1088 Geschwindigkeit_Umkehr 1088;
BA_ "GenSigAutoGenDsp" SG_ 1088 Getriebe_Notlauf 0;
BA_ "GenSigAutoGenSnd" SG_ 1088 Getriebe_Notlauf 0;
BA_ "GenSigSendType" SG_ 1088 Getriebe_Notlauf 7;
BA_ "NWM-WakeupAllowed" SG_ 1088 Getriebe_Notlauf 0;
BA_ "GenSigTimeoutMsg_DME_EDC16CP3000" SG_ 1088 Getriebe_Notlauf 1088;
BA_ "GenSigTimeoutMsg_DME_ME7_MED9_C6" SG_ 1088 Getriebe_Notlauf 1088;
BA_ "GenSigTimeoutMsg_DME_SIMOS6_C6" SG_ 1088 Getriebe_Notlauf 1088;
BA_ "GenSigTimeoutMsg_Gateway_C6" SG_ 1088 Getriebe_Notlauf 1088;
BA_ "GenSigAutoGenDsp" SG_ 1088 Getriebeinfo 0;
BA_ "GenSigAutoGenSnd" SG_ 1088 Getriebeinfo 0;
BA_ "GenSigSendType" SG_ 1088 Getriebeinfo 7;
BA_ "NWM-WakeupAllowed" SG_ 1088 Getriebeinfo 0;
BA_ "GenSigTimeoutMsg_Gateway_C6" SG_ 1088 Getriebeinfo 1088;
BA_ "GenSigAutoGenDsp" SG_ 1088 Inneres_Sollmotormoment 0;
BA_ "GenSigAutoGenSnd" SG_ 1088 Inneres_Sollmotormoment 0;
BA_ "GenSigSendType" SG_ 1088 Inneres_Sollmotormoment 7;
BA_ "GenSigStartValue" SG_ 1088 Inneres_Sollmotormoment 254;
BA_ "NWM-WakeupAllowed" SG_ 1088 Inneres_Sollmotormoment 0;
BA_ "GenSigTimeoutMsg_DME_EDC16CP3000" SG_ 1088 Inneres_Sollmotormoment 1088;
BA_ "GenSigTimeoutMsg_DME_ME7_MED9_C6" SG_ 1088 Inneres_Sollmotormoment 1088;
BA_ "GenSigTimeoutMsg_DME_SIMOS6_C6" SG_ 1088 Inneres_Sollmotormoment 1088;
BA_ "GenSigTimeoutMsg_Gateway_C6" SG_ 1088 Inneres_Sollmotormoment 1088;
BA_ "GenSigAutoGenDsp" SG_ 1088 Klimakompressor_aus 0;
BA_ "GenSigAutoGenSnd" SG_ 1088 Klimakompressor_aus 0;
BA_ "GenSigSendType" SG_ 1088 Klimakompressor_aus 7;
BA_ "NWM-WakeupAllowed" SG_ 1088 Klimakompressor_aus 0;
BA_ "GenSigTimeoutMsg_DME_EDC16CP3000" SG_ 1088 Klimakompressor_aus 1088;
BA_ "GenSigTimeoutMsg_DME_ME7_MED9_C6" SG_ 1088 Klimakompressor_aus 1088;
BA_ "GenSigTimeoutMsg_DME_SIMOS6_C6" SG_ 1088 Klimakompressor_aus 1088;
BA_ "GenSigTimeoutMsg_Gateway_C6" SG_ 1088 Klimakompressor_aus 1088;
BA_ "GenSigAutoGenDsp" SG_ 1088 Kuehlleistung 0;
BA_ "GenSigAutoGenSnd" SG_ 1088 Kuehlleistung 0;
BA_ "GenSigSendType" SG_ 1088 Kuehlleistung 7;
BA_ "NWM-WakeupAllowed" SG_ 1088 Kuehlleistung 0;
BA_ "GenSigTimeoutMsg_DME_ME7_MED9_C6" SG_ 1088 Kuehlleistung 1088;
BA_ "GenSigTimeoutMsg_DME_SIMOS6_C6" SG_ 1088 Kuehlleistung 1088;
BA_ "GenSigTimeoutMsg_Gateway_C6" SG_ 1088 Kuehlleistung 1088;
BA_ "GenSigAutoGenDsp" SG_ 1088 Motor_aus 0;
BA_ "GenSigAutoGenSnd" SG_ 1088 Motor_aus 0;
BA_ "GenSigSendType" SG_ 1088 Motor_aus 7;
BA_ "NWM-WakeupAllowed" SG_ 1088 Motor_aus 0;
BA_ "GenSigTimeoutMsg_Gateway_C6" SG_ 1088 Motor_aus 1088;
BA_ "GenSigAutoGenDsp" SG_ 1088 OBD_Status 0;
BA_ "GenSigAutoGenSnd" SG_ 1088 OBD_Status 0;
BA_ "GenSigSendType" SG_ 1088 OBD_Status 7;
BA_ "NWM-WakeupAllowed" SG_ 1088 OBD_Status 0;
BA_ "GenSigTimeoutMsg_DME_EDC16CP3000" SG_ 1088 OBD_Status 1088;
BA_ "GenSigTimeoutMsg_DME_ME7_MED9_C6" SG_ 1088 OBD_Status 1088;
BA_ "GenSigTimeoutMsg_DME_SIMOS6_C6" SG_ 1088 OBD_Status 1088;
BA_ "GenSigTimeoutMsg_Gateway_C6" SG_ 1088 OBD_Status 1088;
BA_ "GenSigAutoGenDsp" SG_ 1088 Schaltung_aktiv 0;
BA_ "GenSigAutoGenSnd" SG_ 1088 Schaltung_aktiv 0;
BA_ "GenSigSendType" SG_ 1088 Schaltung_aktiv 7;
BA_ "NWM-WakeupAllowed" SG_ 1088 Schaltung_aktiv 0;
BA_ "GenSigTimeoutMsg_DME_EDC16CP3000" SG_ 1088 Schaltung_aktiv 1088;
BA_ "GenSigTimeoutMsg_DME_ME7_MED9_C6" SG_ 1088 Schaltung_aktiv 1088;
BA_ "GenSigTimeoutMsg_DME_SIMOS6_C6" SG_ 1088 Schaltung_aktiv 1088;
BA_ "GenSigTimeoutMsg_ESP8_C6" SG_ 1088 Schaltung_aktiv 1088;
BA_ "GenSigTimeoutMsg_Gateway_C6" SG_ 1088 Schaltung_aktiv 1088;
BA_ "GenSigAutoGenDsp" SG_ 1088 SIB_Getriebe 0;
BA_ "GenSigAutoGenSnd" SG_ 1088 SIB_Getriebe 0;
BA_ "GenSigSendType" SG_ 1088 SIB_Getriebe 7;
BA_ "NWM-WakeupAllowed" SG_ 1088 SIB_Getriebe 0;
BA_ "GenSigTimeoutMsg_Gateway_C6" SG_ 1088 SIB_Getriebe 1088;
BA_ "GenSigAutoGenDsp" SG_ 1088 Status_Wandlerschutz 0;
BA_ "GenSigAutoGenSnd" SG_ 1088 Status_Wandlerschutz 0;
BA_ "GenSigSendType" SG_ 1088 Status_Wandlerschutz 7;
BA_ "NWM-WakeupAllowed" SG_ 1088 Status_Wandlerschutz 0;
BA_ "GenSigTimeoutMsg_DME_ME7_MED9_C6" SG_ 1088 Status_Wandlerschutz 1088;
BA_ "GenSigTimeoutMsg_DME_SIMOS6_C6" SG_ 1088 Status_Wandlerschutz 1088;
BA_ "GenSigTimeoutMsg_Gateway_C6" SG_ 1088 Status_Wandlerschutz 1088;
BA_ "GenSigAutoGenDsp" SG_ 1088 Uebertragungsfunktion_8Bit 0;
BA_ "GenSigAutoGenSnd" SG_ 1088 Uebertragungsfunktion_8Bit 0;
BA_ "GenSigSendType" SG_ 1088 Uebertragungsfunktion_8Bit 7;
BA_ "NWM-WakeupAllowed" SG_ 1088 Uebertragungsfunktion_8Bit 0;
BA_ "GenSigTimeoutMsg_DME_EDC16CP3000" SG_ 1088 Uebertragungsfunktion_8Bit 1088;
BA_ "GenSigTimeoutMsg_DME_ME7_MED9_C6" SG_ 1088 Uebertragungsfunktion_8Bit 1088;
BA_ "GenSigTimeoutMsg_Gateway_C6" SG_ 1088 Uebertragungsfunktion_8Bit 1088;
BA_ "GenSigAutoGenDsp" SG_ 1088 Waehlhebelposition 0;
BA_ "GenSigAutoGenSnd" SG_ 1088 Waehlhebelposition 0;
BA_ "GenSigSendType" SG_ 1088 Waehlhebelposition 7;
BA_ "NWM-WakeupAllowed" SG_ 1088 Waehlhebelposition 0;
BA_ "GenSigTimeoutMsg_DME_EDC16CP3000" SG_ 1088 Waehlhebelposition 1088;
BA_ "GenSigTimeoutMsg_DME_ME7_MED9_C6" SG_ 1088 Waehlhebelposition 1088;
BA_ "GenSigTimeoutMsg_DME_SIMOS6_C6" SG_ 1088 Waehlhebelposition 1088;
BA_ "GenSigTimeoutMsg_EPB_C6" SG_ 1088 Waehlhebelposition 1088;
BA_ "GenSigTimeoutMsg_ESP8_C6" SG_ 1088 Waehlhebelposition 1088;
BA_ "GenSigTimeoutMsg_Gateway_C6" SG_ 1088 Waehlhebelposition 1088;
BA_ "GenSigAutoGenDsp" SG_ 1088 Wandlerkupplung 0;
BA_ "GenSigAutoGenSnd" SG_ 1088 Wandlerkupplung 0;
BA_ "GenSigSendType" SG_ 1088 Wandlerkupplung 7;
BA_ "NWM-WakeupAllowed" SG_ 1088 Wandlerkupplung 0;
BA_ "GenSigTimeoutMsg_DME_EDC16CP3000" SG_ 1088 Wandlerkupplung 1088;
BA_ "GenSigTimeoutMsg_DME_ME7_MED9_C6" SG_ 1088 Wandlerkupplung 1088;
BA_ "GenSigTimeoutMsg_DME_SIMOS6_C6" SG_ 1088 Wandlerkupplung 1088;
BA_ "GenSigTimeoutMsg_EPB_C6" SG_ 1088 Wandlerkupplung 1088;
BA_ "GenSigTimeoutMsg_Gateway_C6" SG_ 1088 Wandlerkupplung 1088;
BA_ "GenSigAutoGenDsp" SG_ 1088 Zielgang 0;
BA_ "GenSigAutoGenSnd" SG_ 1088 Zielgang 0;
BA_ "GenSigSendType" SG_ 1088 Zielgang 7;
BA_ "NWM-WakeupAllowed" SG_ 1088 Zielgang 0;
BA_ "GenSigTimeoutMsg_DME_EDC16CP3000" SG_ 1088 Zielgang 1088;
BA_ "GenSigTimeoutMsg_DME_ME7_MED9_C6" SG_ 1088 Zielgang 1088;
BA_ "GenSigTimeoutMsg_DME_SIMOS6_C6" SG_ 1088 Zielgang 1088;
BA_ "GenSigTimeoutMsg_EPB_C6" SG_ 1088 Zielgang 1088;
BA_ "GenSigTimeoutMsg_ESP8_C6" SG_ 1088 Zielgang 1088;
BA_ "GenSigTimeoutMsg_Gateway_C6" SG_ 1088 Zielgang 1088;
BA_ "GenSigAutoGenDsp" SG_ 1344 BZ_Getriebe2 0;
BA_ "GenSigAutoGenSnd" SG_ 1344 BZ_Getriebe2 0;
BA_ "GenSigSendType" SG_ 1344 BZ_Getriebe2 7;
BA_ "NWM-WakeupAllowed" SG_ 1344 BZ_Getriebe2 0;
BA_ "GenSigTimeoutMsg_DME_EDC16CP3000" SG_ 1344 BZ_Getriebe2 1344;
BA_ "GenSigTimeoutMsg_DME_ME7_MED9_C6" SG_ 1344 BZ_Getriebe2 1344;
BA_ "GenSigTimeoutMsg_DME_SIMOS6_C6" SG_ 1344 BZ_Getriebe2 1344;
BA_ "GenSigTimeoutMsg_Gateway_C6" SG_ 1344 BZ_Getriebe2 1344;
BA_ "GenSigAutoGenDsp" SG_ 1344 Drehzahlmesser_Daempfung 0;
BA_ "GenSigAutoGenSnd" SG_ 1344 Drehzahlmesser_Daempfung 0;
BA_ "GenSigSendType" SG_ 1344 Drehzahlmesser_Daempfung 7;
BA_ "NWM-WakeupAllowed" SG_ 1344 Drehzahlmesser_Daempfung 0;
BA_ "GenSigTimeoutMsg_Gateway_C6" SG_ 1344 Drehzahlmesser_Daempfung 1344;
BA_ "GenSigAutoGenDsp" SG_ 1344 Eingelegte_Fahrstufe 0;
BA_ "GenSigAutoGenSnd" SG_ 1344 Eingelegte_Fahrstufe 0;
BA_ "GenSigSendType" SG_ 1344 Eingelegte_Fahrstufe 7;
BA_ "NWM-WakeupAllowed" SG_ 1344 Eingelegte_Fahrstufe 0;
BA_ "GenSigTimeoutMsg_Gateway_C6" SG_ 1344 Eingelegte_Fahrstufe 1344;
BA_ "GenSigAutoGenDsp" SG_ 1344 Ganganz_Kombi_Getr_var 0;
BA_ "GenSigAutoGenSnd" SG_ 1344 Ganganz_Kombi_Getr_var 0;
BA_ "GenSigSendType" SG_ 1344 Ganganz_Kombi_Getr_var 7;
BA_ "NWM-WakeupAllowed" SG_ 1344 Ganganz_Kombi_Getr_var 0;
BA_ "GenSigTimeoutMsg_Gateway_C6" SG_ 1344 Ganganz_Kombi_Getr_var 1344;
BA_ "GenSigAutoGenDsp" SG_ 1344 Gong_Kuppl_temp_Warn 0;
BA_ "GenSigAutoGenSnd" SG_ 1344 Gong_Kuppl_temp_Warn 0;
BA_ "GenSigSendType" SG_ 1344 Gong_Kuppl_temp_Warn 7;
BA_ "NWM-WakeupAllowed" SG_ 1344 Gong_Kuppl_temp_Warn 0;
BA_ "GenSigTimeoutMsg_Gateway_C6" SG_ 1344 Gong_Kuppl_temp_Warn 1344;
BA_ "GenSigAutoGenDsp" SG_ 1344 Gradientenbegrenzung 0;
BA_ "GenSigAutoGenSnd" SG_ 1344 Gradientenbegrenzung 0;
BA_ "GenSigSendType" SG_ 1344 Gradientenbegrenzung 7;
BA_ "GenSigStartValue" SG_ 1344 Gradientenbegrenzung 255;
BA_ "NWM-WakeupAllowed" SG_ 1344 Gradientenbegrenzung 0;
BA_ "GenSigTimeoutMsg_DME_EDC16CP3000" SG_ 1344 Gradientenbegrenzung 1344;
BA_ "GenSigTimeoutMsg_DME_ME7_MED9_C6" SG_ 1344 Gradientenbegrenzung 1344;
BA_ "GenSigTimeoutMsg_DME_SIMOS6_C6" SG_ 1344 Gradientenbegrenzung 1344;
BA_ "GenSigTimeoutMsg_Gateway_C6" SG_ 1344 Gradientenbegrenzung 1344;
BA_ "GenSigAutoGenDsp" SG_ 1344 Leerlaufsolldrehzahl 0;
BA_ "GenSigAutoGenSnd" SG_ 1344 Leerlaufsolldrehzahl 0;
BA_ "GenSigSendType" SG_ 1344 Leerlaufsolldrehzahl 7;
BA_ "NWM-WakeupAllowed" SG_ 1344 Leerlaufsolldrehzahl 0;
BA_ "GenSigTimeoutMsg_DME_EDC16CP3000" SG_ 1344 Leerlaufsolldrehzahl 1344;
BA_ "GenSigTimeoutMsg_DME_ME7_MED9_C6" SG_ 1344 Leerlaufsolldrehzahl 1344;
BA_ "GenSigTimeoutMsg_DME_SIMOS6_C6" SG_ 1344 Leerlaufsolldrehzahl 1344;
BA_ "GenSigTimeoutMsg_Gateway_C6" SG_ 1344 Leerlaufsolldrehzahl 1344;
BA_ "GenSigAutoGenDsp" SG_ 1344 LFR_Adaption 0;
BA_ "GenSigAutoGenSnd" SG_ 1344 LFR_Adaption 0;
BA_ "GenSigSendType" SG_ 1344 LFR_Adaption 7;
BA_ "NWM-WakeupAllowed" SG_ 1344 LFR_Adaption 0;
BA_ "GenSigTimeoutMsg_DME_EDC16CP3000" SG_ 1344 LFR_Adaption 1344;
BA_ "GenSigTimeoutMsg_DME_ME7_MED9_C6" SG_ 1344 LFR_Adaption 1344;
BA_ "GenSigTimeoutMsg_DME_SIMOS6_C6" SG_ 1344 LFR_Adaption 1344;
BA_ "GenSigTimeoutMsg_Gateway_C6" SG_ 1344 LFR_Adaption 1344;
BA_ "GenSigAutoGenDsp" SG_ 1344 Schubabschaltunterstuetzung 0;
BA_ "GenSigAutoGenSnd" SG_ 1344 Schubabschaltunterstuetzung 0;
BA_ "GenSigSendType" SG_ 1344 Schubabschaltunterstuetzung 7;
BA_ "NWM-WakeupAllowed" SG_ 1344 Schubabschaltunterstuetzung 0;
BA_ "GenSigTimeoutMsg_DME_ME7_MED9_C6" SG_ 1344 Schubabschaltunterstuetzung 1344;
BA_ "GenSigTimeoutMsg_DME_SIMOS6_C6" SG_ 1344 Schubabschaltunterstuetzung 1344;
BA_ "GenSigTimeoutMsg_Gateway_C6" SG_ 1344 Schubabschaltunterstuetzung 1344;
BA_ "GenSigAutoGenDsp" SG_ 1344 Shift_Lock_Lampe 0;
BA_ "GenSigAutoGenSnd" SG_ 1344 Shift_Lock_Lampe 0;
BA_ "GenSigSendType" SG_ 1344 Shift_Lock_Lampe 7;
BA_ "NWM-WakeupAllowed" SG_ 1344 Shift_Lock_Lampe 0;
BA_ "GenSigTimeoutMsg_Gateway_C6" SG_ 1344 Shift_Lock_Lampe 1344;
BA_ "GenSigAutoGenDsp" SG_ 1344 Synchro_Wdrehz_invers 0;
BA_ "GenSigAutoGenSnd" SG_ 1344 Synchro_Wdrehz_invers 0;
BA_ "GenSigSendType" SG_ 1344 Synchro_Wdrehz_invers 7;
BA_ "GenSigStartValue" SG_ 1344 Synchro_Wdrehz_invers 255;
BA_ "NWM-WakeupAllowed" SG_ 1344 Synchro_Wdrehz_invers 0;
BA_ "GenSigTimeoutMsg_DME_EDC16CP3000" SG_ 1344 Synchro_Wdrehz_invers 1344;
BA_ "GenSigTimeoutMsg_DME_ME7_MED9_C6" SG_ 1344 Synchro_Wdrehz_invers 1344;
BA_ "GenSigTimeoutMsg_Gateway_C6" SG_ 1344 Synchro_Wdrehz_invers 1344;
BA_ "GenSigAutoGenDsp" SG_ 1344 Synchro_Wunschdrehzahl 0;
BA_ "GenSigAutoGenSnd" SG_ 1344 Synchro_Wunschdrehzahl 0;
BA_ "GenSigSendType" SG_ 1344 Synchro_Wunschdrehzahl 7;
BA_ "NWM-WakeupAllowed" SG_ 1344 Synchro_Wunschdrehzahl 0;
BA_ "GenSigTimeoutMsg_DME_EDC16CP3000" SG_ 1344 Synchro_Wunschdrehzahl 1344;
BA_ "GenSigTimeoutMsg_DME_ME7_MED9_C6" SG_ 1344 Synchro_Wunschdrehzahl 1344;
BA_ "GenSigTimeoutMsg_Gateway_C6" SG_ 1344 Synchro_Wunschdrehzahl 1344;
BA_ "GenSigAutoGenDsp" SG_ 1344 Synchronisationszeit 0;
BA_ "GenSigAutoGenSnd" SG_ 1344 Synchronisationszeit 0;
BA_ "GenSigSendType" SG_ 1344 Synchronisationszeit 7;
BA_ "NWM-WakeupAllowed" SG_ 1344 Synchronisationszeit 0;
BA_ "GenSigTimeoutMsg_DME_ME7_MED9_C6" SG_ 1344 Synchronisationszeit 1344;
BA_ "GenSigTimeoutMsg_Gateway_C6" SG_ 1344 Synchronisationszeit 1344;
BA_ "GenSigAutoGenDsp" SG_ 1344 Warnungsunterdrueckung 0;
BA_ "GenSigAutoGenSnd" SG_ 1344 Warnungsunterdrueckung 0;
BA_ "GenSigSendType" SG_ 1344 Warnungsunterdrueckung 7;
BA_ "NWM-WakeupAllowed" SG_ 1344 Warnungsunterdrueckung 0;
BA_ "GenSigTimeoutMsg_Gateway_C6" SG_ 1344 Warnungsunterdrueckung 1344;
BA_ "GenSigAutoGenDsp" SG_ 1344 WBA_Blinken 0;
BA_ "GenSigAutoGenSnd" SG_ 1344 WBA_Blinken 0;
BA_ "GenSigSendType" SG_ 1344 WBA_Blinken 7;
BA_ "NWM-WakeupAllowed" SG_ 1344 WBA_Blinken 0;
BA_ "GenSigTimeoutMsg_DME_ME7_MED9_C6" SG_ 1344 WBA_Blinken 1344;
BA_ "GenSigTimeoutMsg_Gateway_C6" SG_ 1344 WBA_Blinken 1344;
BA_ "GenSigAutoGenDsp" SG_ 1344 Zwischengasflag 0;
BA_ "GenSigAutoGenSnd" SG_ 1344 Zwischengasflag 0;
BA_ "GenSigSendType" SG_ 1344 Zwischengasflag 7;
BA_ "NWM-WakeupAllowed" SG_ 1344 Zwischengasflag 0;
BA_ "GenSigTimeoutMsg_DME_EDC16CP3000" SG_ 1344 Zwischengasflag 1344;
BA_ "GenSigTimeoutMsg_DME_ME7_MED9_C6" SG_ 1344 Zwischengasflag 1344;
BA_ "GenSigTimeoutMsg_Gateway_C6" SG_ 1344 Zwischengasflag 1344;
BA_ "GenSigAutoGenDsp" SG_ 1100 ax_Max_Getriebe 1;
BA_ "GenSigAutoGenSnd" SG_ 1100 ax_Max_Getriebe 1;
BA_ "GenSigSendType" SG_ 1100 ax_Max_Getriebe 7;
BA_ "GenSigStartValue" SG_ 1100 ax_Max_Getriebe 88;
BA_ "NWM-WakeupAllowed" SG_ 1100 ax_Max_Getriebe 0;
BA_ "GenSigTimeoutMsg_Gateway_C6" SG_ 1100 ax_Max_Getriebe 1100;
BA_ "GenSigAutoGenDsp" SG_ 1100 BZ_Getriebe6 1;
BA_ "GenSigAutoGenSnd" SG_ 1100 BZ_Getriebe6 1;
BA_ "GenSigSendType" SG_ 1100 BZ_Getriebe6 7;
BA_ "NWM-WakeupAllowed" SG_ 1100 BZ_Getriebe6 0;
BA_ "GenSigTimeoutMsg_DME_EDC16CP3000" SG_ 1100 BZ_Getriebe6 1100;
BA_ "GenSigTimeoutMsg_Gateway_C6" SG_ 1100 BZ_Getriebe6 1100;
BA_ "GenSigAutoGenDsp" SG_ 1100 CHK_Getriebe6 1;
BA_ "GenSigAutoGenSnd" SG_ 1100 CHK_Getriebe6 1;
BA_ "GenSigSendType" SG_ 1100 CHK_Getriebe6 7;
BA_ "NWM-WakeupAllowed" SG_ 1100 CHK_Getriebe6 0;
BA_ "GenSigTimeoutMsg_DME_EDC16CP3000" SG_ 1100 CHK_Getriebe6 1100;
BA_ "GenSigTimeoutMsg_Gateway_C6" SG_ 1100 CHK_Getriebe6 1100;
BA_ "GenSigAutoGenDsp" SG_ 1100 Getriebeverlustmoment_GRA_ACC 0;
BA_ "GenSigAutoGenSnd" SG_ 1100 Getriebeverlustmoment_GRA_ACC 0;
BA_ "GenSigSendType" SG_ 1100 Getriebeverlustmoment_GRA_ACC 7;
BA_ "NWM-WakeupAllowed" SG_ 1100 Getriebeverlustmoment_GRA_ACC 0;
BA_ "GenSigTimeoutMsg_Gateway_C6" SG_ 1100 Getriebeverlustmoment_GRA_ACC 1100;
BA_ "GenSigAutoGenDsp" SG_ 1100 Turbinendrehzahl 1;
BA_ "GenSigAutoGenSnd" SG_ 1100 Turbinendrehzahl 1;
BA_ "GenSigSendType" SG_ 1100 Turbinendrehzahl 7;
BA_ "GenSigStartValue" SG_ 1100 Turbinendrehzahl 16382;
BA_ "NWM-WakeupAllowed" SG_ 1100 Turbinendrehzahl 0;
BA_ "GenSigTimeoutMsg_DME_EDC16CP3000" SG_ 1100 Turbinendrehzahl 1100;
BA_ "GenSigTimeoutMsg_Gateway_C6" SG_ 1100 Turbinendrehzahl 1100;
BA_ "GenSigAutoGenDsp" SG_ 1098 BZ_GME 0;
BA_ "GenSigAutoGenSnd" SG_ 1098 BZ_GME 0;
BA_ "GenSigSendType" SG_ 1098 BZ_GME 7;
BA_ "NWM-WakeupAllowed" SG_ 1098 BZ_GME 0;
BA_ "GenSigTimeoutMsg_DME_EDC16CP3000" SG_ 1098 BZ_GME 1098;
BA_ "GenSigTimeoutMsg_DME_ME7_MED9_C6" SG_ 1098 BZ_GME 1098;
BA_ "GenSigTimeoutMsg_DME_SIMOS6_C6" SG_ 1098 BZ_GME 1098;
BA_ "GenSigTimeoutMsg_ESP8_C6" SG_ 1098 BZ_GME 1098;
BA_ "GenSigAutoGenDsp" SG_ 1098 CHK_GME 0;
BA_ "GenSigAutoGenSnd" SG_ 1098 CHK_GME 0;
BA_ "GenSigSendType" SG_ 1098 CHK_GME 7;
BA_ "NWM-WakeupAllowed" SG_ 1098 CHK_GME 0;
BA_ "GenSigTimeoutMsg_DME_EDC16CP3000" SG_ 1098 CHK_GME 1098;
BA_ "GenSigTimeoutMsg_DME_ME7_MED9_C6" SG_ 1098 CHK_GME 1098;
BA_ "GenSigTimeoutMsg_DME_SIMOS6_C6" SG_ 1098 CHK_GME 1098;
BA_ "GenSigTimeoutMsg_ESP8_C6" SG_ 1098 CHK_GME 1098;
BA_ "GenSigAutoGenDsp" SG_ 1098 CVT_Anf_EPB 1;
BA_ "GenSigAutoGenSnd" SG_ 1098 CVT_Anf_EPB 1;
BA_ "GenSigSendType" SG_ 1098 CVT_Anf_EPB 7;
BA_ "NWM-WakeupAllowed" SG_ 1098 CVT_Anf_EPB 0;
BA_ "GenSigAutoGenDsp" SG_ 1098 CVT_Anf_EPB_gueltig 1;
BA_ "GenSigAutoGenSnd" SG_ 1098 CVT_Anf_EPB_gueltig 1;
BA_ "GenSigSendType" SG_ 1098 CVT_Anf_EPB_gueltig 7;
BA_ "NWM-WakeupAllowed" SG_ 1098 CVT_Anf_EPB_gueltig 0;
BA_ "GenSigAutoGenDsp" SG_ 1098 Dynamischer_Eingriff 0;
BA_ "GenSigAutoGenSnd" SG_ 1098 Dynamischer_Eingriff 0;
BA_ "GenSigSendType" SG_ 1098 Dynamischer_Eingriff 7;
BA_ "GenSigStartValue" SG_ 1098 Dynamischer_Eingriff 1022;
BA_ "NWM-WakeupAllowed" SG_ 1098 Dynamischer_Eingriff 0;
BA_ "GenSigTimeoutMsg_DME_EDC16CP3000" SG_ 1098 Dynamischer_Eingriff 1098;
BA_ "GenSigTimeoutMsg_DME_ME7_MED9_C6" SG_ 1098 Dynamischer_Eingriff 1098;
BA_ "GenSigAutoGenDsp" SG_ 1098 Getriebeverlustmoment 0;
BA_ "GenSigAutoGenSnd" SG_ 1098 Getriebeverlustmoment 0;
BA_ "GenSigSendType" SG_ 1098 Getriebeverlustmoment 7;
BA_ "GenSigStartValue" SG_ 1098 Getriebeverlustmoment 1022;
BA_ "NWM-WakeupAllowed" SG_ 1098 Getriebeverlustmoment 0;
BA_ "GenSigTimeoutMsg_DME_ME7_MED9_C6" SG_ 1098 Getriebeverlustmoment 1098;
BA_ "GenSigTimeoutMsg_ESP8_C6" SG_ 1098 Getriebeverlustmoment 1098;
BA_ "GenSigAutoGenDsp" SG_ 1098 Kuehlkreislaufventil_GME 0;
BA_ "GenSigAutoGenSnd" SG_ 1098 Kuehlkreislaufventil_GME 0;
BA_ "GenSigSendType" SG_ 1098 Kuehlkreislaufventil_GME 7;
BA_ "NWM-WakeupAllowed" SG_ 1098 Kuehlkreislaufventil_GME 0;
BA_ "GenSigAutoGenDsp" SG_ 1098 Langfristiger_Eingriff 0;
BA_ "GenSigAutoGenSnd" SG_ 1098 Langfristiger_Eingriff 0;
BA_ "GenSigSendType" SG_ 1098 Langfristiger_Eingriff 7;
BA_ "GenSigStartValue" SG_ 1098 Langfristiger_Eingriff 1022;
BA_ "NWM-WakeupAllowed" SG_ 1098 Langfristiger_Eingriff 0;
BA_ "GenSigTimeoutMsg_DME_EDC16CP3000" SG_ 1098 Langfristiger_Eingriff 1098;
BA_ "GenSigTimeoutMsg_DME_ME7_MED9_C6" SG_ 1098 Langfristiger_Eingriff 1098;
BA_ "GenSigTimeoutMsg_DME_SIMOS6_C6" SG_ 1098 Langfristiger_Eingriff 1098;
BA_ "GenSigAutoGenDsp" SG_ 1098 QBit_Uebertragungsfunktion 0;
BA_ "GenSigAutoGenSnd" SG_ 1098 QBit_Uebertragungsfunktion 0;
BA_ "GenSigSendType" SG_ 1098 QBit_Uebertragungsfunktion 7;
BA_ "GenSigStartValue" SG_ 1098 QBit_Uebertragungsfunktion 1;
BA_ "NWM-WakeupAllowed" SG_ 1098 QBit_Uebertragungsfunktion 0;
BA_ "GenSigAutoGenDsp" SG_ 1098 Schaltung_aktiv 0;
BA_ "GenSigAutoGenSnd" SG_ 1098 Schaltung_aktiv 0;
BA_ "GenSigSendType" SG_ 1098 Schaltung_aktiv 7;
BA_ "NWM-WakeupAllowed" SG_ 1098 Schaltung_aktiv 0;
BA_ "GenSigTimeoutMsg_DME_ME7_MED9_C6" SG_ 1098 Schaltung_aktiv 1098;
BA_ "GenSigTimeoutMsg_DME_SIMOS6_C6" SG_ 1098 Schaltung_aktiv 1098;
BA_ "GenSigAutoGenDsp" SG_ 1098 Status_Dyn_Eingriff 0;
BA_ "GenSigAutoGenSnd" SG_ 1098 Status_Dyn_Eingriff 0;
BA_ "GenSigSendType" SG_ 1098 Status_Dyn_Eingriff 7;
BA_ "NWM-WakeupAllowed" SG_ 1098 Status_Dyn_Eingriff 0;
BA_ "GenSigTimeoutMsg_DME_EDC16CP3000" SG_ 1098 Status_Dyn_Eingriff 1098;
BA_ "GenSigTimeoutMsg_DME_ME7_MED9_C6" SG_ 1098 Status_Dyn_Eingriff 1098;
BA_ "GenSigTimeoutMsg_DME_SIMOS6_C6" SG_ 1098 Status_Dyn_Eingriff 1098;
BA_ "GenSigAutoGenDsp" SG_ 1098 Status_Langfr_Eingriff 0;
BA_ "GenSigAutoGenSnd" SG_ 1098 Status_Langfr_Eingriff 0;
BA_ "GenSigSendType" SG_ 1098 Status_Langfr_Eingriff 7;
BA_ "NWM-WakeupAllowed" SG_ 1098 Status_Langfr_Eingriff 0;
BA_ "GenSigTimeoutMsg_DME_EDC16CP3000" SG_ 1098 Status_Langfr_Eingriff 1098;
BA_ "GenSigTimeoutMsg_DME_ME7_MED9_C6" SG_ 1098 Status_Langfr_Eingriff 1098;
BA_ "GenSigTimeoutMsg_DME_SIMOS6_C6" SG_ 1098 Status_Langfr_Eingriff 1098;
BA_ "GenSigAutoGenDsp" SG_ 1098 Uebertragungsfunktion_11Bit 0;
BA_ "GenSigAutoGenSnd" SG_ 1098 Uebertragungsfunktion_11Bit 0;
BA_ "GenSigSendType" SG_ 1098 Uebertragungsfunktion_11Bit 7;
BA_ "NWM-WakeupAllowed" SG_ 1098 Uebertragungsfunktion_11Bit 0;
BA_ "GenSigAutoGenDsp" SG_ 906 Abbrechen 0;
BA_ "GenSigAutoGenSnd" SG_ 906 Abbrechen 0;
BA_ "GenSigSendType" SG_ 906 Abbrechen 7;
BA_ "NWM-WakeupAllowed" SG_ 906 Abbrechen 0;
BA_ "GenSigTimeoutMsg_DME_EDC16CP3000" SG_ 906 Abbrechen 906;
BA_ "GenSigTimeoutMsg_DME_ME7_MED9_C6" SG_ 906 Abbrechen 906;
BA_ "GenSigTimeoutMsg_DME_SIMOS6_C6" SG_ 906 Abbrechen 906;
BA_ "GenSigAutoGenDsp" SG_ 906 ACC_Zeitlueckenverstellung 0;
BA_ "GenSigAutoGenSnd" SG_ 906 ACC_Zeitlueckenverstellung 0;
BA_ "GenSigSendType" SG_ 906 ACC_Zeitlueckenverstellung 7;
BA_ "NWM-WakeupAllowed" SG_ 906 ACC_Zeitlueckenverstellung 0;
BA_ "GenSigTimeoutMsg_DME_EDC16CP3000" SG_ 906 ACC_Zeitlueckenverstellung 906;
BA_ "GenSigTimeoutMsg_DME_ME7_MED9_C6" SG_ 906 ACC_Zeitlueckenverstellung 906;
BA_ "GenSigTimeoutMsg_DME_SIMOS6_C6" SG_ 906 ACC_Zeitlueckenverstellung 906;
BA_ "GenSigAutoGenDsp" SG_ 906 Bedienteil_Fehler 0;
BA_ "GenSigAutoGenSnd" SG_ 906 Bedienteil_Fehler 0;
BA_ "GenSigSendType" SG_ 906 Bedienteil_Fehler 7;
BA_ "NWM-WakeupAllowed" SG_ 906 Bedienteil_Fehler 0;
BA_ "GenSigTimeoutMsg_DME_EDC16CP3000" SG_ 906 Bedienteil_Fehler 906;
BA_ "GenSigTimeoutMsg_DME_ME7_MED9_C6" SG_ 906 Bedienteil_Fehler 906;
BA_ "GenSigTimeoutMsg_DME_SIMOS6_C6" SG_ 906 Bedienteil_Fehler 906;
BA_ "GenSigAutoGenDsp" SG_ 906 BZ_GRA_Neu 0;
BA_ "GenSigAutoGenSnd" SG_ 906 BZ_GRA_Neu 0;
BA_ "GenSigSendType" SG_ 906 BZ_GRA_Neu 7;
BA_ "NWM-WakeupAllowed" SG_ 906 BZ_GRA_Neu 0;
BA_ "GenSigTimeoutMsg__6HP_C6" SG_ 906 BZ_GRA_Neu 906;
BA_ "GenSigTimeoutMsg_DME_EDC16CP3000" SG_ 906 BZ_GRA_Neu 906;
BA_ "GenSigTimeoutMsg_DME_ME7_MED9_C6" SG_ 906 BZ_GRA_Neu 906;
BA_ "GenSigTimeoutMsg_DME_SIMOS6_C6" SG_ 906 BZ_GRA_Neu 906;
BA_ "GenSigAutoGenDsp" SG_ 906 CHK_GRA_Neu 0;
BA_ "GenSigAutoGenSnd" SG_ 906 CHK_GRA_Neu 0;
BA_ "GenSigSendType" SG_ 906 CHK_GRA_Neu 7;
BA_ "NWM-WakeupAllowed" SG_ 906 CHK_GRA_Neu 0;
BA_ "GenSigTimeoutMsg__6HP_C6" SG_ 906 CHK_GRA_Neu 906;
BA_ "GenSigTimeoutMsg_DME_EDC16CP3000" SG_ 906 CHK_GRA_Neu 906;
BA_ "GenSigTimeoutMsg_DME_ME7_MED9_C6" SG_ 906 CHK_GRA_Neu 906;
BA_ "GenSigTimeoutMsg_DME_SIMOS6_C6" SG_ 906 CHK_GRA_Neu 906;
BA_ "GenSigAutoGenDsp" SG_ 906 Codierinfo_SMLS 0;
BA_ "GenSigAutoGenSnd" SG_ 906 Codierinfo_SMLS 0;
BA_ "GenSigSendType" SG_ 906 Codierinfo_SMLS 7;
BA_ "NWM-WakeupAllowed" SG_ 906 Codierinfo_SMLS 0;
BA_ "GenSigTimeoutMsg_DME_EDC16CP3000" SG_ 906 Codierinfo_SMLS 906;
BA_ "GenSigTimeoutMsg_DME_ME7_MED9_C6" SG_ 906 Codierinfo_SMLS 906;
BA_ "GenSigTimeoutMsg_DME_SIMOS6_C6" SG_ 906 Codierinfo_SMLS 906;
BA_ "GenSigAutoGenDsp" SG_ 906 GRA_Hauptschalter 0;
BA_ "GenSigAutoGenSnd" SG_ 906 GRA_Hauptschalter 0;
BA_ "GenSigSendType" SG_ 906 GRA_Hauptschalter 7;
BA_ "NWM-WakeupAllowed" SG_ 906 GRA_Hauptschalter 0;
BA_ "GenSigTimeoutMsg_DME_EDC16CP3000" SG_ 906 GRA_Hauptschalter 906;
BA_ "GenSigTimeoutMsg_DME_ME7_MED9_C6" SG_ 906 GRA_Hauptschalter 906;
BA_ "GenSigTimeoutMsg_DME_SIMOS6_C6" SG_ 906 GRA_Hauptschalter 906;
BA_ "GenSigAutoGenDsp" SG_ 906 KurzTip_down 0;
BA_ "GenSigAutoGenSnd" SG_ 906 KurzTip_down 0;
BA_ "GenSigSendType" SG_ 906 KurzTip_down 7;
BA_ "NWM-WakeupAllowed" SG_ 906 KurzTip_down 0;
BA_ "GenSigTimeoutMsg_DME_EDC16CP3000" SG_ 906 KurzTip_down 906;
BA_ "GenSigTimeoutMsg_DME_ME7_MED9_C6" SG_ 906 KurzTip_down 906;
BA_ "GenSigTimeoutMsg_DME_SIMOS6_C6" SG_ 906 KurzTip_down 906;
BA_ "GenSigAutoGenDsp" SG_ 906 KurzTip_up 0;
BA_ "GenSigAutoGenSnd" SG_ 906 KurzTip_up 0;
BA_ "GenSigSendType" SG_ 906 KurzTip_up 7;
BA_ "NWM-WakeupAllowed" SG_ 906 KurzTip_up 0;
BA_ "GenSigTimeoutMsg_DME_EDC16CP3000" SG_ 906 KurzTip_up 906;
BA_ "GenSigTimeoutMsg_DME_ME7_MED9_C6" SG_ 906 KurzTip_up 906;
BA_ "GenSigTimeoutMsg_DME_SIMOS6_C6" SG_ 906 KurzTip_up 906;
BA_ "GenSigAutoGenDsp" SG_ 906 LangTip_down 0;
BA_ "GenSigAutoGenSnd" SG_ 906 LangTip_down 0;
BA_ "GenSigSendType" SG_ 906 LangTip_down 7;
BA_ "NWM-WakeupAllowed" SG_ 906 LangTip_down 0;
BA_ "GenSigTimeoutMsg_DME_EDC16CP3000" SG_ 906 LangTip_down 906;
BA_ "GenSigTimeoutMsg_DME_ME7_MED9_C6" SG_ 906 LangTip_down 906;
BA_ "GenSigTimeoutMsg_DME_SIMOS6_C6" SG_ 906 LangTip_down 906;
BA_ "GenSigAutoGenDsp" SG_ 906 LangTip_up 0;
BA_ "GenSigAutoGenSnd" SG_ 906 LangTip_up 0;
BA_ "GenSigSendType" SG_ 906 LangTip_up 7;
BA_ "NWM-WakeupAllowed" SG_ 906 LangTip_up 0;
BA_ "GenSigTimeoutMsg_DME_EDC16CP3000" SG_ 906 LangTip_up 906;
BA_ "GenSigTimeoutMsg_DME_ME7_MED9_C6" SG_ 906 LangTip_up 906;
BA_ "GenSigTimeoutMsg_DME_SIMOS6_C6" SG_ 906 LangTip_up 906;
BA_ "GenSigAutoGenDsp" SG_ 906 Sendercodierung 0;
BA_ "GenSigAutoGenSnd" SG_ 906 Sendercodierung 0;
BA_ "GenSigSendType" SG_ 906 Sendercodierung 7;
BA_ "NWM-WakeupAllowed" SG_ 906 Sendercodierung 0;
BA_ "GenSigTimeoutMsg_DME_EDC16CP3000" SG_ 906 Sendercodierung 906;
BA_ "GenSigTimeoutMsg_DME_ME7_MED9_C6" SG_ 906 Sendercodierung 906;
BA_ "GenSigTimeoutMsg_DME_SIMOS6_C6" SG_ 906 Sendercodierung 906;
BA_ "GenSigAutoGenDsp" SG_ 906 Tip_Setzen 0;
BA_ "GenSigAutoGenSnd" SG_ 906 Tip_Setzen 0;
BA_ "GenSigSendType" SG_ 906 Tip_Setzen 7;
BA_ "NWM-WakeupAllowed" SG_ 906 Tip_Setzen 0;
BA_ "GenSigTimeoutMsg_DME_EDC16CP3000" SG_ 906 Tip_Setzen 906;
BA_ "GenSigTimeoutMsg_DME_ME7_MED9_C6" SG_ 906 Tip_Setzen 906;
BA_ "GenSigTimeoutMsg_DME_SIMOS6_C6" SG_ 906 Tip_Setzen 906;
BA_ "GenSigAutoGenDsp" SG_ 906 Tip_Wiederaufnahme 0;
BA_ "GenSigAutoGenSnd" SG_ 906 Tip_Wiederaufnahme 0;
BA_ "GenSigSendType" SG_ 906 Tip_Wiederaufnahme 7;
BA_ "NWM-WakeupAllowed" SG_ 906 Tip_Wiederaufnahme 0;
BA_ "GenSigTimeoutMsg_DME_EDC16CP3000" SG_ 906 Tip_Wiederaufnahme 906;
BA_ "GenSigTimeoutMsg_DME_ME7_MED9_C6" SG_ 906 Tip_Wiederaufnahme 906;
BA_ "GenSigTimeoutMsg_DME_SIMOS6_C6" SG_ 906 Tip_Wiederaufnahme 906;
BA_ "GenSigAutoGenDsp" SG_ 906 Tiptronic_Limiter 0;
BA_ "GenSigAutoGenSnd" SG_ 906 Tiptronic_Limiter 0;
BA_ "GenSigSendType" SG_ 906 Tiptronic_Limiter 7;
BA_ "NWM-WakeupAllowed" SG_ 906 Tiptronic_Limiter 0;
BA_ "GenSigTimeoutMsg_DME_EDC16CP3000" SG_ 906 Tiptronic_Limiter 906;
BA_ "GenSigTimeoutMsg_DME_ME7_MED9_C6" SG_ 906 Tiptronic_Limiter 906;
BA_ "GenSigTimeoutMsg_DME_SIMOS6_C6" SG_ 906 Tiptronic_Limiter 906;
BA_ "GenSigAutoGenDsp" SG_ 906 Tiptronic_Tip_Down 0;
BA_ "GenSigAutoGenSnd" SG_ 906 Tiptronic_Tip_Down 0;
BA_ "GenSigSendType" SG_ 906 Tiptronic_Tip_Down 7;
BA_ "NWM-WakeupAllowed" SG_ 906 Tiptronic_Tip_Down 0;
BA_ "GenSigTimeoutMsg__6HP_C6" SG_ 906 Tiptronic_Tip_Down 906;
BA_ "GenSigTimeoutMsg_DME_EDC16CP3000" SG_ 906 Tiptronic_Tip_Down 906;
BA_ "GenSigTimeoutMsg_DME_ME7_MED9_C6" SG_ 906 Tiptronic_Tip_Down 906;
BA_ "GenSigTimeoutMsg_DME_SIMOS6_C6" SG_ 906 Tiptronic_Tip_Down 906;
BA_ "GenSigAutoGenDsp" SG_ 906 Tiptronic_Tip_Fehler 0;
BA_ "GenSigAutoGenSnd" SG_ 906 Tiptronic_Tip_Fehler 0;
BA_ "GenSigSendType" SG_ 906 Tiptronic_Tip_Fehler 7;
BA_ "NWM-WakeupAllowed" SG_ 906 Tiptronic_Tip_Fehler 0;
BA_ "GenSigTimeoutMsg__6HP_C6" SG_ 906 Tiptronic_Tip_Fehler 906;
BA_ "GenSigTimeoutMsg_DME_EDC16CP3000" SG_ 906 Tiptronic_Tip_Fehler 906;
BA_ "GenSigTimeoutMsg_DME_ME7_MED9_C6" SG_ 906 Tiptronic_Tip_Fehler 906;
BA_ "GenSigTimeoutMsg_DME_SIMOS6_C6" SG_ 906 Tiptronic_Tip_Fehler 906;
BA_ "GenSigAutoGenDsp" SG_ 906 Tiptronic_Tip_Up 0;
BA_ "GenSigAutoGenSnd" SG_ 906 Tiptronic_Tip_Up 0;
BA_ "GenSigSendType" SG_ 906 Tiptronic_Tip_Up 7;
BA_ "NWM-WakeupAllowed" SG_ 906 Tiptronic_Tip_Up 0;
BA_ "GenSigTimeoutMsg__6HP_C6" SG_ 906 Tiptronic_Tip_Up 906;
BA_ "GenSigTimeoutMsg_DME_EDC16CP3000" SG_ 906 Tiptronic_Tip_Up 906;
BA_ "GenSigTimeoutMsg_DME_ME7_MED9_C6" SG_ 906 Tiptronic_Tip_Up 906;
BA_ "GenSigTimeoutMsg_DME_SIMOS6_C6" SG_ 906 Tiptronic_Tip_Up 906;
BA_ "GenSigAutoGenDsp" SG_ 906 Typ_Hauptschalter 0;
BA_ "GenSigAutoGenSnd" SG_ 906 Typ_Hauptschalter 0;
BA_ "GenSigSendType" SG_ 906 Typ_Hauptschalter 7;
BA_ "NWM-WakeupAllowed" SG_ 906 Typ_Hauptschalter 0;
BA_ "GenSigTimeoutMsg_DME_EDC16CP3000" SG_ 906 Typ_Hauptschalter 906;
BA_ "GenSigTimeoutMsg_DME_ME7_MED9_C6" SG_ 906 Typ_Hauptschalter 906;
BA_ "GenSigTimeoutMsg_DME_SIMOS6_C6" SG_ 906 Typ_Hauptschalter 906;
BA_ "GenSigAutoGenDsp" SG_ 1490 Data1 0;
BA_ "GenSigAutoGenSnd" SG_ 1490 Data1 0;
BA_ "GenSigSendType" SG_ 1490 Data1 7;
BA_ "NWM-WakeupAllowed" SG_ 1490 Data1 0;
BA_ "GenSigTimeoutMsg__4CL_C6" SG_ 1490 Data1 1490;
BA_ "GenSigAutoGenDsp" SG_ 1490 Data2 0;
BA_ "GenSigAutoGenSnd" SG_ 1490 Data2 0;
BA_ "GenSigSendType" SG_ 1490 Data2 7;
BA_ "NWM-WakeupAllowed" SG_ 1490 Data2 0;
BA_ "GenSigTimeoutMsg__4CL_C6" SG_ 1490 Data2 1490;
BA_ "GenSigAutoGenDsp" SG_ 1490 Data3 0;
BA_ "GenSigAutoGenSnd" SG_ 1490 Data3 0;
BA_ "GenSigSendType" SG_ 1490 Data3 7;
BA_ "NWM-WakeupAllowed" SG_ 1490 Data3 0;
BA_ "GenSigTimeoutMsg__4CL_C6" SG_ 1490 Data3 1490;
BA_ "GenSigAutoGenDsp" SG_ 1490 Data4 0;
BA_ "GenSigAutoGenSnd" SG_ 1490 Data4 0;
BA_ "GenSigSendType" SG_ 1490 Data4 7;
BA_ "NWM-WakeupAllowed" SG_ 1490 Data4 0;
BA_ "GenSigTimeoutMsg__4CL_C6" SG_ 1490 Data4 1490;
BA_ "GenSigAutoGenDsp" SG_ 1490 Data5 0;
BA_ "GenSigAutoGenSnd" SG_ 1490 Data5 0;
BA_ "GenSigSendType" SG_ 1490 Data5 7;
BA_ "NWM-WakeupAllowed" SG_ 1490 Data5 0;
BA_ "GenSigTimeoutMsg__4CL_C6" SG_ 1490 Data5 1490;
BA_ "GenSigAutoGenDsp" SG_ 1490 Data6 0;
BA_ "GenSigAutoGenSnd" SG_ 1490 Data6 0;
BA_ "GenSigSendType" SG_ 1490 Data6 7;
BA_ "NWM-WakeupAllowed" SG_ 1490 Data6 0;
BA_ "GenSigTimeoutMsg__4CL_C6" SG_ 1490 Data6 1490;
BA_ "GenSigAutoGenDsp" SG_ 1490 Data7 0;
BA_ "GenSigAutoGenSnd" SG_ 1490 Data7 0;
BA_ "GenSigSendType" SG_ 1490 Data7 7;
BA_ "NWM-WakeupAllowed" SG_ 1490 Data7 0;
BA_ "GenSigTimeoutMsg__4CL_C6" SG_ 1490 Data7 1490;
BA_ "GenSigAutoGenDsp" SG_ 1490 Mux 1;
BA_ "GenSigAutoGenSnd" SG_ 1490 Mux 1;
BA_ "GenSigSendType" SG_ 1490 Mux 7;
BA_ "NWM-WakeupAllowed" SG_ 1490 Mux 0;
BA_ "GenSigTimeoutMsg__4CL_C6" SG_ 1490 Mux 1490;
BA_ "GenSigAutoGenDsp" SG_ 2016 ISO_Request_ECU_Data 0;
BA_ "GenSigAutoGenSnd" SG_ 2016 ISO_Request_ECU_Data 0;
BA_ "GenSigSendType" SG_ 2016 ISO_Request_ECU_Data 7;
BA_ "NWM-WakeupAllowed" SG_ 2016 ISO_Request_ECU_Data 0;
BA_ "GenSigAutoGenDsp" SG_ 2017 ISO_Request_ECU_Data 0;
BA_ "GenSigAutoGenSnd" SG_ 2017 ISO_Request_ECU_Data 0;
BA_ "GenSigSendType" SG_ 2017 ISO_Request_ECU_Data 7;
BA_ "NWM-WakeupAllowed" SG_ 2017 ISO_Request_ECU_Data 0;
BA_ "GenSigAutoGenDsp" SG_ 2018 ISO_Request_ECU_Data 0;
BA_ "GenSigAutoGenSnd" SG_ 2018 ISO_Request_ECU_Data 0;
BA_ "GenSigSendType" SG_ 2018 ISO_Request_ECU_Data 7;
BA_ "NWM-WakeupAllowed" SG_ 2018 ISO_Request_ECU_Data 0;
BA_ "GenSigAutoGenDsp" SG_ 2019 ISO_Request_ECU_Data 0;
BA_ "GenSigAutoGenSnd" SG_ 2019 ISO_Request_ECU_Data 0;
BA_ "GenSigSendType" SG_ 2019 ISO_Request_ECU_Data 7;
BA_ "NWM-WakeupAllowed" SG_ 2019 ISO_Request_ECU_Data 0;
BA_ "GenSigAutoGenDsp" SG_ 2020 ISO_Request_ECU_Data 0;
BA_ "GenSigAutoGenSnd" SG_ 2020 ISO_Request_ECU_Data 0;
BA_ "GenSigSendType" SG_ 2020 ISO_Request_ECU_Data 7;
BA_ "NWM-WakeupAllowed" SG_ 2020 ISO_Request_ECU_Data 0;
BA_ "GenSigAutoGenDsp" SG_ 2021 ISO_Request_ECU_Data 0;
BA_ "GenSigAutoGenSnd" SG_ 2021 ISO_Request_ECU_Data 0;
BA_ "GenSigSendType" SG_ 2021 ISO_Request_ECU_Data 7;
BA_ "NWM-WakeupAllowed" SG_ 2021 ISO_Request_ECU_Data 0;
BA_ "GenSigAutoGenDsp" SG_ 2022 ISO_Request_ECU_Data 0;
BA_ "GenSigAutoGenSnd" SG_ 2022 ISO_Request_ECU_Data 0;
BA_ "GenSigSendType" SG_ 2022 ISO_Request_ECU_Data 7;
BA_ "NWM-WakeupAllowed" SG_ 2022 ISO_Request_ECU_Data 0;
BA_ "GenSigAutoGenDsp" SG_ 2023 ISO_Request_ECU_Data 0;
BA_ "GenSigAutoGenSnd" SG_ 2023 ISO_Request_ECU_Data 0;
BA_ "GenSigSendType" SG_ 2023 ISO_Request_ECU_Data 7;
BA_ "NWM-WakeupAllowed" SG_ 2023 ISO_Request_ECU_Data 0;
BA_ "GenSigAutoGenDsp" SG_ 2015 ISO_Request_ECU_Data 0;
BA_ "GenSigAutoGenSnd" SG_ 2015 ISO_Request_ECU_Data 0;
BA_ "GenSigSendType" SG_ 2015 ISO_Request_ECU_Data 7;
BA_ "NWM-WakeupAllowed" SG_ 2015 ISO_Request_ECU_Data 0;
BA_ "GenSigAutoGenDsp" SG_ 2024 ISO_Response_ECU_Data 0;
BA_ "GenSigAutoGenSnd" SG_ 2024 ISO_Response_ECU_Data 0;
BA_ "GenSigSendType" SG_ 2024 ISO_Response_ECU_Data 7;
BA_ "NWM-WakeupAllowed" SG_ 2024 ISO_Response_ECU_Data 0;
BA_ "GenSigTimeoutMsg_Gateway_C6" SG_ 2024 ISO_Response_ECU_Data 2024;
BA_ "GenSigAutoGenDsp" SG_ 2025 ISO_Response_ECU_Data 0;
BA_ "GenSigAutoGenSnd" SG_ 2025 ISO_Response_ECU_Data 0;
BA_ "GenSigSendType" SG_ 2025 ISO_Response_ECU_Data 7;
BA_ "NWM-WakeupAllowed" SG_ 2025 ISO_Response_ECU_Data 0;
BA_ "GenSigTimeoutMsg_Gateway_C6" SG_ 2025 ISO_Response_ECU_Data 2025;
BA_ "GenSigAutoGenDsp" SG_ 2026 ISO_Response_ECU_Data 0;
BA_ "GenSigAutoGenSnd" SG_ 2026 ISO_Response_ECU_Data 0;
BA_ "GenSigSendType" SG_ 2026 ISO_Response_ECU_Data 7;
BA_ "NWM-WakeupAllowed" SG_ 2026 ISO_Response_ECU_Data 0;
BA_ "GenSigTimeoutMsg_Gateway_C6" SG_ 2026 ISO_Response_ECU_Data 2026;
BA_ "GenSigAutoGenDsp" SG_ 2027 ISO_Response_ECU_Data 0;
BA_ "GenSigAutoGenSnd" SG_ 2027 ISO_Response_ECU_Data 0;
BA_ "GenSigSendType" SG_ 2027 ISO_Response_ECU_Data 7;
BA_ "NWM-WakeupAllowed" SG_ 2027 ISO_Response_ECU_Data 0;
BA_ "GenSigTimeoutMsg_Gateway_C6" SG_ 2027 ISO_Response_ECU_Data 2027;
BA_ "GenSigAutoGenDsp" SG_ 2028 ISO_Response_ECU_Data 0;
BA_ "GenSigAutoGenSnd" SG_ 2028 ISO_Response_ECU_Data 0;
BA_ "GenSigSendType" SG_ 2028 ISO_Response_ECU_Data 7;
BA_ "NWM-WakeupAllowed" SG_ 2028 ISO_Response_ECU_Data 0;
BA_ "GenSigTimeoutMsg_Gateway_C6" SG_ 2028 ISO_Response_ECU_Data 2028;
BA_ "GenSigAutoGenDsp" SG_ 2029 ISO_Response_ECU_Data 0;
BA_ "GenSigAutoGenSnd" SG_ 2029 ISO_Response_ECU_Data 0;
BA_ "GenSigSendType" SG_ 2029 ISO_Response_ECU_Data 7;
BA_ "NWM-WakeupAllowed" SG_ 2029 ISO_Response_ECU_Data 0;
BA_ "GenSigTimeoutMsg_Gateway_C6" SG_ 2029 ISO_Response_ECU_Data 2029;
BA_ "GenSigAutoGenDsp" SG_ 2030 ISO_Response_ECU_Data 0;
BA_ "GenSigAutoGenSnd" SG_ 2030 ISO_Response_ECU_Data 0;
BA_ "GenSigSendType" SG_ 2030 ISO_Response_ECU_Data 7;
BA_ "NWM-WakeupAllowed" SG_ 2030 ISO_Response_ECU_Data 0;
BA_ "GenSigTimeoutMsg_Gateway_C6" SG_ 2030 ISO_Response_ECU_Data 2030;
BA_ "GenSigAutoGenDsp" SG_ 2031 ISO_Response_ECU_Data 0;
BA_ "GenSigAutoGenSnd" SG_ 2031 ISO_Response_ECU_Data 0;
BA_ "GenSigSendType" SG_ 2031 ISO_Response_ECU_Data 7;
BA_ "NWM-WakeupAllowed" SG_ 2031 ISO_Response_ECU_Data 0;
BA_ "GenSigTimeoutMsg_Gateway_C6" SG_ 2031 ISO_Response_ECU_Data 2031;
BA_ "GenSigAutoGenDsp" SG_ 1504 Ansteuerung_Kuehlerluefter 0;
BA_ "GenSigAutoGenSnd" SG_ 1504 Ansteuerung_Kuehlerluefter 0;
BA_ "GenSigSendType" SG_ 1504 Ansteuerung_Kuehlerluefter 7;
BA_ "NWM-WakeupAllowed" SG_ 1504 Ansteuerung_Kuehlerluefter 0;
BA_ "GenSigTimeoutMsg_DME_EDC16CP3000" SG_ 1504 Ansteuerung_Kuehlerluefter 1504;
BA_ "GenSigTimeoutMsg_DME_ME7_MED9_C6" SG_ 1504 Ansteuerung_Kuehlerluefter 1504;
BA_ "GenSigTimeoutMsg_DME_SIMOS6_C6" SG_ 1504 Ansteuerung_Kuehlerluefter 1504;
BA_ "GenSigAutoGenDsp" SG_ 1504 AussenTemp_aus_Wasserkasten 0;
BA_ "GenSigAutoGenSnd" SG_ 1504 AussenTemp_aus_Wasserkasten 0;
BA_ "GenSigSendType" SG_ 1504 AussenTemp_aus_Wasserkasten 7;
BA_ "NWM-WakeupAllowed" SG_ 1504 AussenTemp_aus_Wasserkasten 0;
BA_ "GenSigAutoGenDsp" SG_ 1504 Aussentemp_Stossf_ungef 0;
BA_ "GenSigAutoGenSnd" SG_ 1504 Aussentemp_Stossf_ungef 0;
BA_ "GenSigSendType" SG_ 1504 Aussentemp_Stossf_ungef 7;
BA_ "NWM-WakeupAllowed" SG_ 1504 Aussentemp_Stossf_ungef 0;
BA_ "GenSigAutoGenDsp" SG_ 1504 Geblaeselastinfo 0;
BA_ "GenSigAutoGenSnd" SG_ 1504 Geblaeselastinfo 0;
BA_ "GenSigSendType" SG_ 1504 Geblaeselastinfo 7;
BA_ "NWM-WakeupAllowed" SG_ 1504 Geblaeselastinfo 0;
BA_ "GenSigTimeoutMsg_DME_ME7_MED9_C6" SG_ 1504 Geblaeselastinfo 1504;
BA_ "GenSigAutoGenDsp" SG_ 1504 Heizung_ausgeschaltet 0;
BA_ "GenSigAutoGenSnd" SG_ 1504 Heizung_ausgeschaltet 0;
BA_ "GenSigSendType" SG_ 1504 Heizung_ausgeschaltet 7;
BA_ "NWM-WakeupAllowed" SG_ 1504 Heizung_ausgeschaltet 0;
BA_ "GenSigTimeoutMsg_DME_EDC16CP3000" SG_ 1504 Heizung_ausgeschaltet 1504;
BA_ "GenSigTimeoutMsg_DME_ME7_MED9_C6" SG_ 1504 Heizung_ausgeschaltet 1504;
BA_ "GenSigAutoGenDsp" SG_ 1504 HeizungFrontscheibe_ein 0;
BA_ "GenSigAutoGenSnd" SG_ 1504 HeizungFrontscheibe_ein 0;
BA_ "GenSigSendType" SG_ 1504 HeizungFrontscheibe_ein 7;
BA_ "NWM-WakeupAllowed" SG_ 1504 HeizungFrontscheibe_ein 0;
BA_ "GenSigTimeoutMsg_DME_ME7_MED9_C6" SG_ 1504 HeizungFrontscheibe_ein 1504;
BA_ "GenSigAutoGenDsp" SG_ 1504 HeizungHeckscheibe_ein 0;
BA_ "GenSigAutoGenSnd" SG_ 1504 HeizungHeckscheibe_ein 0;
BA_ "GenSigSendType" SG_ 1504 HeizungHeckscheibe_ein 7;
BA_ "NWM-WakeupAllowed" SG_ 1504 HeizungHeckscheibe_ein 0;
BA_ "GenSigTimeoutMsg_DME_ME7_MED9_C6" SG_ 1504 HeizungHeckscheibe_ein 1504;
BA_ "GenSigAutoGenDsp" SG_ 1504 KaeltemittelDruck 0;
BA_ "GenSigAutoGenSnd" SG_ 1504 KaeltemittelDruck 0;
BA_ "GenSigSendType" SG_ 1504 KaeltemittelDruck 7;
BA_ "NWM-WakeupAllowed" SG_ 1504 KaeltemittelDruck 0;
BA_ "GenSigTimeoutMsg_DME_ME7_MED9_C6" SG_ 1504 KaeltemittelDruck 1504;
BA_ "GenSigTimeoutMsg_DME_SIMOS6_C6" SG_ 1504 KaeltemittelDruck 1504;
BA_ "GenSigAutoGenDsp" SG_ 1504 Kaeltemitteldruck_alt 0;
BA_ "GenSigAutoGenSnd" SG_ 1504 Kaeltemitteldruck_alt 0;
BA_ "GenSigSendType" SG_ 1504 Kaeltemitteldruck_alt 7;
BA_ "NWM-WakeupAllowed" SG_ 1504 Kaeltemitteldruck_alt 0;
BA_ "GenSigAutoGenDsp" SG_ 1504 KD_Fehler_Klima 0;
BA_ "GenSigAutoGenSnd" SG_ 1504 KD_Fehler_Klima 0;
BA_ "GenSigSendType" SG_ 1504 KD_Fehler_Klima 7;
BA_ "NWM-WakeupAllowed" SG_ 1504 KD_Fehler_Klima 0;
BA_ "GenSigAutoGenDsp" SG_ 1504 Kompressor_ein 0;
BA_ "GenSigAutoGenSnd" SG_ 1504 Kompressor_ein 0;
BA_ "GenSigSendType" SG_ 1504 Kompressor_ein 7;
BA_ "NWM-WakeupAllowed" SG_ 1504 Kompressor_ein 0;
BA_ "GenSigTimeoutMsg_DME_EDC16CP3000" SG_ 1504 Kompressor_ein 1504;
BA_ "GenSigTimeoutMsg_DME_ME7_MED9_C6" SG_ 1504 Kompressor_ein 1504;
BA_ "GenSigTimeoutMsg_DME_SIMOS6_C6" SG_ 1504 Kompressor_ein 1504;
BA_ "GenSigAutoGenDsp" SG_ 1504 Kompressorlastinfo 0;
BA_ "GenSigAutoGenSnd" SG_ 1504 Kompressorlastinfo 0;
BA_ "GenSigSendType" SG_ 1504 Kompressorlastinfo 7;
BA_ "NWM-WakeupAllowed" SG_ 1504 Kompressorlastinfo 0;
BA_ "GenSigTimeoutMsg_DME_EDC16CP3000" SG_ 1504 Kompressorlastinfo 1504;
BA_ "GenSigTimeoutMsg_DME_ME7_MED9_C6" SG_ 1504 Kompressorlastinfo 1504;
BA_ "GenSigTimeoutMsg_DME_SIMOS6_C6" SG_ 1504 Kompressorlastinfo 1504;
BA_ "GenSigAutoGenDsp" SG_ 1504 Kompressormoment_alt 0;
BA_ "GenSigAutoGenSnd" SG_ 1504 Kompressormoment_alt 0;
BA_ "GenSigSendType" SG_ 1504 Kompressormoment_alt 7;
BA_ "NWM-WakeupAllowed" SG_ 1504 Kompressormoment_alt 0;
BA_ "GenSigAutoGenDsp" SG_ 1504 Restwaermefunktion 0;
BA_ "GenSigAutoGenSnd" SG_ 1504 Restwaermefunktion 0;
BA_ "GenSigSendType" SG_ 1504 Restwaermefunktion 7;
BA_ "NWM-WakeupAllowed" SG_ 1504 Restwaermefunktion 0;
BA_ "GenSigAutoGenDsp" SG_ 1504 SH_aktiv_Flag 0;
BA_ "GenSigAutoGenSnd" SG_ 1504 SH_aktiv_Flag 0;
BA_ "GenSigSendType" SG_ 1504 SH_aktiv_Flag 7;
BA_ "NWM-WakeupAllowed" SG_ 1504 SH_aktiv_Flag 0;
BA_ "GenSigAutoGenDsp" SG_ 1504 SH_MVW 0;
BA_ "GenSigAutoGenSnd" SG_ 1504 SH_MVW 0;
BA_ "GenSigSendType" SG_ 1504 SH_MVW 7;
BA_ "NWM-WakeupAllowed" SG_ 1504 SH_MVW 0;
BA_ "GenSigAutoGenDsp" SG_ 1504 Signal_fuer_Drehzahlanhebung 0;
BA_ "GenSigAutoGenSnd" SG_ 1504 Signal_fuer_Drehzahlanhebung 0;
BA_ "GenSigSendType" SG_ 1504 Signal_fuer_Drehzahlanhebung 7;
BA_ "NWM-WakeupAllowed" SG_ 1504 Signal_fuer_Drehzahlanhebung 0;
BA_ "GenSigTimeoutMsg_DME_EDC16CP3000" SG_ 1504 Signal_fuer_Drehzahlanhebung 1504;
BA_ "GenSigTimeoutMsg_DME_ME7_MED9_C6" SG_ 1504 Signal_fuer_Drehzahlanhebung 1504;
BA_ "GenSigTimeoutMsg_DME_SIMOS6_C6" SG_ 1504 Signal_fuer_Drehzahlanhebung 1504;
BA_ "GenSigAutoGenDsp" SG_ 1504 Temp_in_F 0;
BA_ "GenSigAutoGenSnd" SG_ 1504 Temp_in_F 0;
BA_ "GenSigSendType" SG_ 1504 Temp_in_F 7;
BA_ "NWM-WakeupAllowed" SG_ 1504 Temp_in_F 0;
BA_ "GenSigAutoGenDsp" SG_ 1504 Zuheizer_ein 0;
BA_ "GenSigAutoGenSnd" SG_ 1504 Zuheizer_ein 0;
BA_ "GenSigSendType" SG_ 1504 Zuheizer_ein 7;
BA_ "NWM-WakeupAllowed" SG_ 1504 Zuheizer_ein 0;
BA_ "GenSigTimeoutMsg_DME_EDC16CP3000" SG_ 1504 Zuheizer_ein 1504;
BA_ "GenSigTimeoutMsg_DME_ME7_MED9_C6" SG_ 1504 Zuheizer_ein 1504;
BA_ "GenSigTimeoutMsg_DME_SIMOS6_C6" SG_ 1504 Zuheizer_ein 1504;
BA_ "GenSigAutoGenDsp" SG_ 1504 Zustand_Klima 0;
BA_ "GenSigAutoGenSnd" SG_ 1504 Zustand_Klima 0;
BA_ "GenSigSendType" SG_ 1504 Zustand_Klima 7;
BA_ "NWM-WakeupAllowed" SG_ 1504 Zustand_Klima 0;
BA_ "GenSigTimeoutMsg_DME_SIMOS6_C6" SG_ 1504 Zustand_Klima 1504;
BA_ "GenSigAutoGenDsp" SG_ 800 ABS_Lampe_ein 0;
BA_ "GenSigAutoGenSnd" SG_ 800 ABS_Lampe_ein 0;
BA_ "GenSigSendType" SG_ 800 ABS_Lampe_ein 7;
BA_ "NWM-WakeupAllowed" SG_ 800 ABS_Lampe_ein 0;
BA_ "GenSigAutoGenDsp" SG_ 800 ACC_Anzeigefehler 0;
BA_ "GenSigAutoGenSnd" SG_ 800 ACC_Anzeigefehler 0;
BA_ "GenSigSendType" SG_ 800 ACC_Anzeigefehler 7;
BA_ "NWM-WakeupAllowed" SG_ 800 ACC_Anzeigefehler 0;
BA_ "GenSigAutoGenDsp" SG_ 800 ACC_Zusatzanzeige 0;
BA_ "GenSigAutoGenSnd" SG_ 800 ACC_Zusatzanzeige 0;
BA_ "GenSigSendType" SG_ 800 ACC_Zusatzanzeige 7;
BA_ "NWM-WakeupAllowed" SG_ 800 ACC_Zusatzanzeige 0;
BA_ "GenSigAutoGenDsp" SG_ 800 Airbag_Lampe_ein 0;
BA_ "GenSigAutoGenSnd" SG_ 800 Airbag_Lampe_ein 0;
BA_ "GenSigSendType" SG_ 800 Airbag_Lampe_ein 7;
BA_ "NWM-WakeupAllowed" SG_ 800 Airbag_Lampe_ein 0;
BA_ "GenSigAutoGenDsp" SG_ 800 angez_Geschw 0;
BA_ "GenSigAutoGenSnd" SG_ 800 angez_Geschw 0;
BA_ "GenSigSendType" SG_ 800 angez_Geschw 7;
BA_ "NWM-WakeupAllowed" SG_ 800 angez_Geschw 0;
BA_ "GenSigAutoGenDsp" SG_ 800 ASR_ESP_Lampe_ein 0;
BA_ "GenSigAutoGenSnd" SG_ 800 ASR_ESP_Lampe_ein 0;
BA_ "GenSigSendType" SG_ 800 ASR_ESP_Lampe_ein 7;
BA_ "NWM-WakeupAllowed" SG_ 800 ASR_ESP_Lampe_ein 0;
BA_ "GenSigAutoGenDsp" SG_ 800 BKL_ein 0;
BA_ "GenSigAutoGenSnd" SG_ 800 BKL_ein 0;
BA_ "GenSigSendType" SG_ 800 BKL_ein 7;
BA_ "NWM-WakeupAllowed" SG_ 800 BKL_ein 0;
BA_ "GenSigAutoGenDsp" SG_ 800 Bremsfluessigkeitswarnung 0;
BA_ "GenSigAutoGenSnd" SG_ 800 Bremsfluessigkeitswarnung 0;
BA_ "GenSigSendType" SG_ 800 Bremsfluessigkeitswarnung 7;
BA_ "NWM-WakeupAllowed" SG_ 800 Bremsfluessigkeitswarnung 0;
BA_ "GenSigAutoGenDsp" SG_ 800 BZ_Kombi1 0;
BA_ "GenSigAutoGenSnd" SG_ 800 BZ_Kombi1 0;
BA_ "GenSigSendType" SG_ 800 BZ_Kombi1 7;
BA_ "NWM-WakeupAllowed" SG_ 800 BZ_Kombi1 0;
BA_ "GenSigAutoGenDsp" SG_ 800 Dyn_Oeldr_warn 0;
BA_ "GenSigAutoGenSnd" SG_ 800 Dyn_Oeldr_warn 0;
BA_ "GenSigSendType" SG_ 800 Dyn_Oeldr_warn 7;
BA_ "NWM-WakeupAllowed" SG_ 800 Dyn_Oeldr_warn 0;
BA_ "GenSigAutoGenDsp" SG_ 800 Einheit_angez_Geschw 0;
BA_ "GenSigAutoGenSnd" SG_ 800 Einheit_angez_Geschw 0;
BA_ "GenSigSendType" SG_ 800 Einheit_angez_Geschw 7;
BA_ "NWM-WakeupAllowed" SG_ 800 Einheit_angez_Geschw 0;
BA_ "GenSigAutoGenDsp" SG_ 800 FStatus_Tank 0;
BA_ "GenSigAutoGenSnd" SG_ 800 FStatus_Tank 0;
BA_ "GenSigSendType" SG_ 800 FStatus_Tank 7;
BA_ "NWM-WakeupAllowed" SG_ 800 FStatus_Tank 0;
BA_ "GenSigTimeoutMsg_DME_ME7_MED9_C6" SG_ 800 FStatus_Tank 800;
BA_ "GenSigTimeoutMsg_DME_SIMOS6_C6" SG_ 800 FStatus_Tank 800;
BA_ "GenSigAutoGenDsp" SG_ 800 Handbremse_angezogen 0;
BA_ "GenSigAutoGenSnd" SG_ 800 Handbremse_angezogen 0;
BA_ "GenSigSendType" SG_ 800 Handbremse_angezogen 7;
BA_ "NWM-WakeupAllowed" SG_ 800 Handbremse_angezogen 0;
BA_ "GenSigAutoGenDsp" SG_ 800 Kombi_im_Stellgliedtest 0;
BA_ "GenSigAutoGenSnd" SG_ 800 Kombi_im_Stellgliedtest 0;
BA_ "GenSigSendType" SG_ 800 Kombi_im_Stellgliedtest 7;
BA_ "NWM-WakeupAllowed" SG_ 800 Kombi_im_Stellgliedtest 0;
BA_ "GenSigAutoGenDsp" SG_ 800 Konsistenz_ACC_Botschaften 0;
BA_ "GenSigAutoGenSnd" SG_ 800 Konsistenz_ACC_Botschaften 0;
BA_ "GenSigSendType" SG_ 800 Konsistenz_ACC_Botschaften 7;
BA_ "NWM-WakeupAllowed" SG_ 800 Konsistenz_ACC_Botschaften 0;
BA_ "GenSigAutoGenDsp" SG_ 800 Kuehlmittelmangel 0;
BA_ "GenSigAutoGenSnd" SG_ 800 Kuehlmittelmangel 0;
BA_ "GenSigSendType" SG_ 800 Kuehlmittelmangel 7;
BA_ "NWM-WakeupAllowed" SG_ 800 Kuehlmittelmangel 0;
BA_ "GenSigAutoGenDsp" SG_ 800 Ladekontroll_Lampe 0;
BA_ "GenSigAutoGenSnd" SG_ 800 Ladekontroll_Lampe 0;
BA_ "GenSigSendType" SG_ 800 Ladekontroll_Lampe 7;
BA_ "NWM-WakeupAllowed" SG_ 800 Ladekontroll_Lampe 0;
BA_ "GenSigAutoGenDsp" SG_ 800 LDW_Anzeigefehler 1;
BA_ "GenSigAutoGenSnd" SG_ 800 LDW_Anzeigefehler 1;
BA_ "GenSigSendType" SG_ 800 LDW_Anzeigefehler 7;
BA_ "NWM-WakeupAllowed" SG_ 800 LDW_Anzeigefehler 0;
BA_ "GenSigAutoGenDsp" SG_ 800 Lenkhilfe_Lampe_ein 0;
BA_ "GenSigAutoGenSnd" SG_ 800 Lenkhilfe_Lampe_ein 0;
BA_ "GenSigSendType" SG_ 800 Lenkhilfe_Lampe_ein 7;
BA_ "NWM-WakeupAllowed" SG_ 800 Lenkhilfe_Lampe_ein 0;
BA_ "GenSigAutoGenDsp" SG_ 800 Oeldruck 0;
BA_ "GenSigAutoGenSnd" SG_ 800 Oeldruck 0;
BA_ "GenSigSendType" SG_ 800 Oeldruck 7;
BA_ "NWM-WakeupAllowed" SG_ 800 Oeldruck 0;
BA_ "GenSigAutoGenDsp" SG_ 800 SIB_Kombi 0;
BA_ "GenSigAutoGenSnd" SG_ 800 SIB_Kombi 0;
BA_ "GenSigSendType" SG_ 800 SIB_Kombi 7;
BA_ "NWM-WakeupAllowed" SG_ 800 SIB_Kombi 0;
BA_ "GenSigAutoGenDsp" SG_ 800 Signalquelle_Geschwindigkeit 0;
BA_ "GenSigAutoGenSnd" SG_ 800 Signalquelle_Geschwindigkeit 0;
BA_ "GenSigSendType" SG_ 800 Signalquelle_Geschwindigkeit 7;
BA_ "NWM-WakeupAllowed" SG_ 800 Signalquelle_Geschwindigkeit 0;
BA_ "GenSigAutoGenDsp" SG_ 800 SILA_gueltig 0;
BA_ "GenSigAutoGenSnd" SG_ 800 SILA_gueltig 0;
BA_ "GenSigSendType" SG_ 800 SILA_gueltig 7;
BA_ "NWM-WakeupAllowed" SG_ 800 SILA_gueltig 0;
BA_ "GenSigAutoGenDsp" SG_ 800 Tankinhalt 0;
BA_ "GenSigAutoGenSnd" SG_ 800 Tankinhalt 0;
BA_ "GenSigSendType" SG_ 800 Tankinhalt 7;
BA_ "NWM-WakeupAllowed" SG_ 800 Tankinhalt 0;
BA_ "GenSigTimeoutMsg_DME_ME7_MED9_C6" SG_ 800 Tankinhalt 800;
BA_ "GenSigTimeoutMsg_DME_SIMOS6_C6" SG_ 800 Tankinhalt 800;
BA_ "GenSigAutoGenDsp" SG_ 800 Tankstop 0;
BA_ "GenSigAutoGenSnd" SG_ 800 Tankstop 0;
BA_ "GenSigSendType" SG_ 800 Tankstop 7;
BA_ "NWM-WakeupAllowed" SG_ 800 Tankstop 0;
BA_ "GenSigAutoGenDsp" SG_ 800 Tankwarnlampe 0;
BA_ "GenSigAutoGenSnd" SG_ 800 Tankwarnlampe 0;
BA_ "GenSigSendType" SG_ 800 Tankwarnlampe 7;
BA_ "NWM-WakeupAllowed" SG_ 800 Tankwarnlampe 0;
BA_ "GenSigTimeoutMsg_DME_EDC16CP3000" SG_ 800 Tankwarnlampe 800;
BA_ "GenSigTimeoutMsg_DME_SIMOS6_C6" SG_ 800 Tankwarnlampe 800;
BA_ "GenSigAutoGenDsp" SG_ 800 Tankwarnung 0;
BA_ "GenSigAutoGenSnd" SG_ 800 Tankwarnung 0;
BA_ "GenSigSendType" SG_ 800 Tankwarnung 7;
BA_ "NWM-WakeupAllowed" SG_ 800 Tankwarnung 0;
BA_ "GenSigTimeoutMsg_DME_ME7_MED9_C6" SG_ 800 Tankwarnung 800;
BA_ "GenSigTimeoutMsg_DME_SIMOS6_C6" SG_ 800 Tankwarnung 800;
BA_ "GenSigAutoGenDsp" SG_ 800 Vorgluehlampe_Kombi 0;
BA_ "GenSigAutoGenSnd" SG_ 800 Vorgluehlampe_Kombi 0;
BA_ "GenSigSendType" SG_ 800 Vorgluehlampe_Kombi 7;
BA_ "NWM-WakeupAllowed" SG_ 800 Vorgluehlampe_Kombi 0;
BA_ "GenSigTimeoutMsg_DME_EDC16CP3000" SG_ 800 Vorgluehlampe_Kombi 800;
BA_ "GenSigAutoGenDsp" SG_ 800 Wakeup_Komfort 0;
BA_ "GenSigAutoGenSnd" SG_ 800 Wakeup_Komfort 0;
BA_ "GenSigSendType" SG_ 800 Wakeup_Komfort 7;
BA_ "NWM-WakeupAllowed" SG_ 800 Wakeup_Komfort 0;
BA_ "GenSigAutoGenDsp" SG_ 1056 Aussentemp_gef 0;
BA_ "GenSigAutoGenSnd" SG_ 1056 Aussentemp_gef 0;
BA_ "GenSigSendType" SG_ 1056 Aussentemp_gef 7;
BA_ "NWM-WakeupAllowed" SG_ 1056 Aussentemp_gef 0;
BA_ "GenSigTimeoutMsg__6HP_C6" SG_ 1056 Aussentemp_gef 1056;
BA_ "GenSigTimeoutMsg_DME_EDC16CP3000" SG_ 1056 Aussentemp_gef 1056;
BA_ "GenSigTimeoutMsg_DME_ME7_MED9_C6" SG_ 1056 Aussentemp_gef 1056;
BA_ "GenSigTimeoutMsg_DME_SIMOS6_C6" SG_ 1056 Aussentemp_gef 1056;
BA_ "GenSigTimeoutMsg_EPB_C6" SG_ 1056 Aussentemp_gef 1056;
BA_ "GenSigTimeoutMsg_ESP8_C6" SG_ 1056 Aussentemp_gef 1056;
BA_ "GenSigAutoGenDsp" SG_ 1056 Aussentemp_ungef 0;
BA_ "GenSigAutoGenSnd" SG_ 1056 Aussentemp_ungef 0;
BA_ "GenSigSendType" SG_ 1056 Aussentemp_ungef 7;
BA_ "NWM-WakeupAllowed" SG_ 1056 Aussentemp_ungef 0;
BA_ "GenSigTimeoutMsg_DME_SIMOS6_C6" SG_ 1056 Aussentemp_ungef 1056;
BA_ "GenSigAutoGenDsp" SG_ 1056 FSPE_Kombi 0;
BA_ "GenSigAutoGenSnd" SG_ 1056 FSPE_Kombi 0;
BA_ "GenSigSendType" SG_ 1056 FSPE_Kombi 7;
BA_ "NWM-WakeupAllowed" SG_ 1056 FSPE_Kombi 0;
BA_ "GenSigAutoGenDsp" SG_ 1056 FStatus_Aussentemp 0;
BA_ "GenSigAutoGenSnd" SG_ 1056 FStatus_Aussentemp 0;
BA_ "GenSigSendType" SG_ 1056 FStatus_Aussentemp 7;
BA_ "NWM-WakeupAllowed" SG_ 1056 FStatus_Aussentemp 0;
BA_ "GenSigTimeoutMsg_DME_EDC16CP3000" SG_ 1056 FStatus_Aussentemp 1056;
BA_ "GenSigTimeoutMsg_DME_SIMOS6_C6" SG_ 1056 FStatus_Aussentemp 1056;
BA_ "GenSigTimeoutMsg_EPB_C6" SG_ 1056 FStatus_Aussentemp 1056;
BA_ "GenSigTimeoutMsg_ESP8_C6" SG_ 1056 FStatus_Aussentemp 1056;
BA_ "GenSigAutoGenDsp" SG_ 1056 FStatus_KL58d 0;
BA_ "GenSigAutoGenSnd" SG_ 1056 FStatus_KL58d 0;
BA_ "GenSigSendType" SG_ 1056 FStatus_KL58d 7;
BA_ "NWM-WakeupAllowed" SG_ 1056 FStatus_KL58d 0;
BA_ "GenSigTimeoutMsg_Airbag_C6" SG_ 1056 FStatus_KL58d 1056;
BA_ "GenSigAutoGenDsp" SG_ 1056 FStatus_KL58s 0;
BA_ "GenSigAutoGenSnd" SG_ 1056 FStatus_KL58s 0;
BA_ "GenSigSendType" SG_ 1056 FStatus_KL58s 7;
BA_ "NWM-WakeupAllowed" SG_ 1056 FStatus_KL58s 0;
BA_ "GenSigAutoGenDsp" SG_ 1056 GRA_high_Anzeige 1;
BA_ "GenSigAutoGenSnd" SG_ 1056 GRA_high_Anzeige 1;
BA_ "GenSigSendType" SG_ 1056 GRA_high_Anzeige 7;
BA_ "NWM-WakeupAllowed" SG_ 1056 GRA_high_Anzeige 0;
BA_ "GenSigAutoGenDsp" SG_ 1056 Klemme_58d 0;
BA_ "GenSigAutoGenSnd" SG_ 1056 Klemme_58d 0;
BA_ "GenSigSendType" SG_ 1056 Klemme_58d 7;
BA_ "NWM-WakeupAllowed" SG_ 1056 Klemme_58d 0;
BA_ "GenSigTimeoutMsg_Airbag_C6" SG_ 1056 Klemme_58d 1056;
BA_ "GenSigAutoGenDsp" SG_ 1056 Klemme_58s 0;
BA_ "GenSigAutoGenSnd" SG_ 1056 Klemme_58s 0;
BA_ "GenSigSendType" SG_ 1056 Klemme_58s 7;
BA_ "NWM-WakeupAllowed" SG_ 1056 Klemme_58s 0;
BA_ "GenSigAutoGenDsp" SG_ 1056 MFA_v_Einheit 1;
BA_ "GenSigAutoGenSnd" SG_ 1056 MFA_v_Einheit 1;
BA_ "GenSigSendType" SG_ 1056 MFA_v_Einheit 7;
BA_ "NWM-WakeupAllowed" SG_ 1056 MFA_v_Einheit 0;
BA_ "GenSigAutoGenDsp" SG_ 1056 Oelwarnschwelle_pOue 0;
BA_ "GenSigAutoGenSnd" SG_ 1056 Oelwarnschwelle_pOue 0;
BA_ "GenSigSendType" SG_ 1056 Oelwarnschwelle_pOue 7;
BA_ "NWM-WakeupAllowed" SG_ 1056 Oelwarnschwelle_pOue 0;
BA_ "GenSigAutoGenDsp" SG_ 1056 Temperatureinheit 0;
BA_ "GenSigAutoGenSnd" SG_ 1056 Temperatureinheit 0;
BA_ "GenSigSendType" SG_ 1056 Temperatureinheit 7;
BA_ "NWM-WakeupAllowed" SG_ 1056 Temperatureinheit 0;
BA_ "GenSigAutoGenDsp" SG_ 1056 TOG_nicht_verbaut 0;
BA_ "GenSigAutoGenSnd" SG_ 1056 TOG_nicht_verbaut 0;
BA_ "GenSigSendType" SG_ 1056 TOG_nicht_verbaut 7;
BA_ "NWM-WakeupAllowed" SG_ 1056 TOG_nicht_verbaut 0;
BA_ "GenSigTimeoutMsg_DME_ME7_MED9_C6" SG_ 1056 TOG_nicht_verbaut 1056;
BA_ "GenSigAutoGenDsp" SG_ 1056 Waschwasser_Warnung 0;
BA_ "GenSigAutoGenSnd" SG_ 1056 Waschwasser_Warnung 0;
BA_ "GenSigSendType" SG_ 1056 Waschwasser_Warnung 7;
BA_ "NWM-WakeupAllowed" SG_ 1056 Waschwasser_Warnung 0;
BA_ "GenSigAutoGenDsp" SG_ 1312 Baureihe 1;
BA_ "GenSigAutoGenSnd" SG_ 1312 Baureihe 1;
BA_ "GenSigSendType" SG_ 1312 Baureihe 7;
BA_ "NWM-WakeupAllowed" SG_ 1312 Baureihe 0;
BA_ "GenSigAutoGenDsp" SG_ 1312 Derivat 1;
BA_ "GenSigAutoGenSnd" SG_ 1312 Derivat 1;
BA_ "GenSigSendType" SG_ 1312 Derivat 7;
BA_ "NWM-WakeupAllowed" SG_ 1312 Derivat 0;
BA_ "GenSigAutoGenDsp" SG_ 1312 Generation 1;
BA_ "GenSigAutoGenSnd" SG_ 1312 Generation 1;
BA_ "GenSigSendType" SG_ 1312 Generation 7;
BA_ "NWM-WakeupAllowed" SG_ 1312 Generation 0;
BA_ "GenSigAutoGenDsp" SG_ 1312 Kilometerstand 0;
BA_ "GenSigAutoGenSnd" SG_ 1312 Kilometerstand 0;
BA_ "GenSigSendType" SG_ 1312 Kilometerstand 7;
BA_ "NWM-WakeupAllowed" SG_ 1312 Kilometerstand 0;
BA_ "GenSigTimeoutMsg__6HP_C6" SG_ 1312 Kilometerstand 1312;
BA_ "GenSigTimeoutMsg_DME_ME7_MED9_C6" SG_ 1312 Kilometerstand 1312;
BA_ "GenSigTimeoutMsg_DME_SIMOS6_C6" SG_ 1312 Kilometerstand 1312;
BA_ "GenSigAutoGenDsp" SG_ 1312 Marke 1;
BA_ "GenSigAutoGenSnd" SG_ 1312 Marke 1;
BA_ "GenSigSendType" SG_ 1312 Marke 7;
BA_ "NWM-WakeupAllowed" SG_ 1312 Marke 0;
BA_ "GenSigAutoGenDsp" SG_ 1312 Multiplex_Laendervariante 0;
BA_ "GenSigAutoGenSnd" SG_ 1312 Multiplex_Laendervariante 0;
BA_ "GenSigSendType" SG_ 1312 Multiplex_Laendervariante 7;
BA_ "NWM-WakeupAllowed" SG_ 1312 Multiplex_Laendervariante 0;
BA_ "GenSigTimeoutMsg_Airbag_C6" SG_ 1312 Multiplex_Laendervariante 1312;
BA_ "GenSigAutoGenDsp" SG_ 1312 Multiplex_Sprachvariante 0;
BA_ "GenSigAutoGenSnd" SG_ 1312 Multiplex_Sprachvariante 0;
BA_ "GenSigSendType" SG_ 1312 Multiplex_Sprachvariante 7;
BA_ "NWM-WakeupAllowed" SG_ 1312 Multiplex_Sprachvariante 0;
BA_ "GenSigTimeoutMsg_Airbag_C6" SG_ 1312 Multiplex_Sprachvariante 1312;
BA_ "GenSigAutoGenDsp" SG_ 1312 Mux_Code_Kombi3 0;
BA_ "GenSigAutoGenSnd" SG_ 1312 Mux_Code_Kombi3 0;
BA_ "GenSigSendType" SG_ 1312 Mux_Code_Kombi3 7;
BA_ "NWM-WakeupAllowed" SG_ 1312 Mux_Code_Kombi3 0;
BA_ "GenSigTimeoutMsg_Airbag_C6" SG_ 1312 Mux_Code_Kombi3 1312;
BA_ "GenSigTimeoutMsg_ESP8_C6" SG_ 1312 Mux_Code_Kombi3 1312;
BA_ "GenSigAutoGenDsp" SG_ 1312 Reifenumfang 0;
BA_ "GenSigAutoGenSnd" SG_ 1312 Reifenumfang 0;
BA_ "GenSigSendType" SG_ 1312 Reifenumfang 7;
BA_ "NWM-WakeupAllowed" SG_ 1312 Reifenumfang 0;
BA_ "GenSigTimeoutMsg_ESP8_C6" SG_ 1312 Reifenumfang 1312;
BA_ "GenSigAutoGenDsp" SG_ 1312 Reset_Standzeit 0;
BA_ "GenSigAutoGenSnd" SG_ 1312 Reset_Standzeit 0;
BA_ "GenSigSendType" SG_ 1312 Reset_Standzeit 7;
BA_ "NWM-WakeupAllowed" SG_ 1312 Reset_Standzeit 0;
BA_ "GenSigTimeoutMsg_DME_ME7_MED9_C6" SG_ 1312 Reset_Standzeit 1312;
BA_ "GenSigTimeoutMsg_EPB_C6" SG_ 1312 Reset_Standzeit 1312;
BA_ "GenSigTimeoutMsg_ESP8_C6" SG_ 1312 Reset_Standzeit 1312;
BA_ "GenSigAutoGenDsp" SG_ 1312 Schluesselinfo 0;
BA_ "GenSigAutoGenSnd" SG_ 1312 Schluesselinfo 0;
BA_ "GenSigSendType" SG_ 1312 Schluesselinfo 7;
BA_ "NWM-WakeupAllowed" SG_ 1312 Schluesselinfo 0;
BA_ "GenSigAutoGenDsp" SG_ 1312 Standzeit 0;
BA_ "GenSigAutoGenSnd" SG_ 1312 Standzeit 0;
BA_ "GenSigSendType" SG_ 1312 Standzeit 7;
BA_ "NWM-WakeupAllowed" SG_ 1312 Standzeit 0;
BA_ "GenSigTimeoutMsg_DME_ME7_MED9_C6" SG_ 1312 Standzeit 1312;
BA_ "GenSigTimeoutMsg_DME_SIMOS6_C6" SG_ 1312 Standzeit 1312;
BA_ "GenSigTimeoutMsg_EPB_C6" SG_ 1312 Standzeit 1312;
BA_ "GenSigTimeoutMsg_ESP8_C6" SG_ 1312 Standzeit 1312;
BA_ "GenSigAutoGenDsp" SG_ 1312 Verbauliste 1;
BA_ "GenSigAutoGenSnd" SG_ 1312 Verbauliste 1;
BA_ "GenSigSendType" SG_ 1312 Verbauliste 7;
BA_ "NWM-WakeupAllowed" SG_ 1312 Verbauliste 0;
BA_ "GenSigAutoGenDsp" SG_ 916 AFS_Fehlerlampe 0;
BA_ "GenSigAutoGenSnd" SG_ 916 AFS_Fehlerlampe 0;
BA_ "GenSigSendType" SG_ 916 AFS_Fehlerlampe 7;
BA_ "NWM-WakeupAllowed" SG_ 916 AFS_Fehlerlampe 0;
BA_ "GenSigTimeoutMsg_Gateway_C6" SG_ 916 AFS_Fehlerlampe 916;
BA_ "GenSigAutoGenDsp" SG_ 916 AFS_Fehlertext 1;
BA_ "GenSigAutoGenSnd" SG_ 916 AFS_Fehlertext 1;
BA_ "GenSigSendType" SG_ 916 AFS_Fehlertext 7;
BA_ "NWM-WakeupAllowed" SG_ 916 AFS_Fehlertext 0;
BA_ "GenSigTimeoutMsg_Gateway_C6" SG_ 916 AFS_Fehlertext 916;
BA_ "GenSigAutoGenDsp" SG_ 916 AFS_LED_Blinkmode 1;
BA_ "GenSigAutoGenSnd" SG_ 916 AFS_LED_Blinkmode 1;
BA_ "GenSigSendType" SG_ 916 AFS_LED_Blinkmode 7;
BA_ "NWM-WakeupAllowed" SG_ 916 AFS_LED_Blinkmode 0;
BA_ "GenSigTimeoutMsg_Gateway_C6" SG_ 916 AFS_LED_Blinkmode 916;
BA_ "GenSigAutoGenDsp" SG_ 916 BZ_LWR_Zustand 0;
BA_ "GenSigAutoGenSnd" SG_ 916 BZ_LWR_Zustand 0;
BA_ "GenSigSendType" SG_ 916 BZ_LWR_Zustand 7;
BA_ "NWM-WakeupAllowed" SG_ 916 BZ_LWR_Zustand 0;
BA_ "GenSigTimeoutMsg_Gateway_C6" SG_ 916 BZ_LWR_Zustand 916;
BA_ "GenSigAutoGenDsp" SG_ 916 Einfederung_Karosse_hinten 0;
BA_ "GenSigAutoGenSnd" SG_ 916 Einfederung_Karosse_hinten 0;
BA_ "GenSigSendType" SG_ 916 Einfederung_Karosse_hinten 7;
BA_ "NWM-WakeupAllowed" SG_ 916 Einfederung_Karosse_hinten 0;
BA_ "GenSigTimeoutMsg_Gateway_C6" SG_ 916 Einfederung_Karosse_hinten 916;
BA_ "GenSigAutoGenDsp" SG_ 916 Einfederung_Karosse_vorn 0;
BA_ "GenSigAutoGenSnd" SG_ 916 Einfederung_Karosse_vorn 0;
BA_ "GenSigSendType" SG_ 916 Einfederung_Karosse_vorn 7;
BA_ "NWM-WakeupAllowed" SG_ 916 Einfederung_Karosse_vorn 0;
BA_ "GenSigTimeoutMsg_Gateway_C6" SG_ 916 Einfederung_Karosse_vorn 916;
BA_ "GenSigAutoGenDsp" SG_ 916 Ersatzlichtfunktion_links 0;
BA_ "GenSigAutoGenSnd" SG_ 916 Ersatzlichtfunktion_links 0;
BA_ "GenSigSendType" SG_ 916 Ersatzlichtfunktion_links 7;
BA_ "NWM-WakeupAllowed" SG_ 916 Ersatzlichtfunktion_links 0;
BA_ "GenSigTimeoutMsg_Gateway_C6" SG_ 916 Ersatzlichtfunktion_links 916;
BA_ "GenSigAutoGenDsp" SG_ 916 Ersatzlichtfunktion_rechts 0;
BA_ "GenSigAutoGenSnd" SG_ 916 Ersatzlichtfunktion_rechts 0;
BA_ "GenSigSendType" SG_ 916 Ersatzlichtfunktion_rechts 7;
BA_ "NWM-WakeupAllowed" SG_ 916 Ersatzlichtfunktion_rechts 0;
BA_ "GenSigTimeoutMsg_Gateway_C6" SG_ 916 Ersatzlichtfunktion_rechts 916;
BA_ "GenSigAutoGenDsp" SG_ 916 FSPE_LWR_AFS 0;
BA_ "GenSigAutoGenSnd" SG_ 916 FSPE_LWR_AFS 0;
BA_ "GenSigSendType" SG_ 916 FSPE_LWR_AFS 7;
BA_ "NWM-WakeupAllowed" SG_ 916 FSPE_LWR_AFS 0;
BA_ "GenSigTimeoutMsg_Gateway_C6" SG_ 916 FSPE_LWR_AFS 916;
BA_ "GenSigAutoGenDsp" SG_ 916 LWR_AFS_Grundeinstellung 0;
BA_ "GenSigAutoGenSnd" SG_ 916 LWR_AFS_Grundeinstellung 0;
BA_ "GenSigSendType" SG_ 916 LWR_AFS_Grundeinstellung 7;
BA_ "NWM-WakeupAllowed" SG_ 916 LWR_AFS_Grundeinstellung 0;
BA_ "GenSigTimeoutMsg_Gateway_C6" SG_ 916 LWR_AFS_Grundeinstellung 916;
BA_ "GenSigAutoGenDsp" SG_ 916 LWR_AFS_Parametrisierung 0;
BA_ "GenSigAutoGenSnd" SG_ 916 LWR_AFS_Parametrisierung 0;
BA_ "GenSigSendType" SG_ 916 LWR_AFS_Parametrisierung 7;
BA_ "NWM-WakeupAllowed" SG_ 916 LWR_AFS_Parametrisierung 0;
BA_ "GenSigTimeoutMsg_Gateway_C6" SG_ 916 LWR_AFS_Parametrisierung 916;
BA_ "GenSigAutoGenDsp" SG_ 916 LWR_Fehlerlampe 0;
BA_ "GenSigAutoGenSnd" SG_ 916 LWR_Fehlerlampe 0;
BA_ "GenSigSendType" SG_ 916 LWR_Fehlerlampe 7;
BA_ "NWM-WakeupAllowed" SG_ 916 LWR_Fehlerlampe 0;
BA_ "GenSigTimeoutMsg_Gateway_C6" SG_ 916 LWR_Fehlerlampe 916;
BA_ "GenSigAutoGenDsp" SG_ 916 LWR_Initialisierungslauf 0;
BA_ "GenSigAutoGenSnd" SG_ 916 LWR_Initialisierungslauf 0;
BA_ "GenSigSendType" SG_ 916 LWR_Initialisierungslauf 7;
BA_ "NWM-WakeupAllowed" SG_ 916 LWR_Initialisierungslauf 0;
BA_ "GenSigTimeoutMsg_Gateway_C6" SG_ 916 LWR_Initialisierungslauf 916;
BA_ "GenSigAutoGenDsp" SG_ 916 LWR_Modus 0;
BA_ "GenSigAutoGenSnd" SG_ 916 LWR_Modus 0;
BA_ "GenSigSendType" SG_ 916 LWR_Modus 7;
BA_ "NWM-WakeupAllowed" SG_ 916 LWR_Modus 0;
BA_ "GenSigTimeoutMsg_Gateway_C6" SG_ 916 LWR_Modus 916;
BA_ "GenSigAutoGenDsp" SG_ 916 LWR_Sicherheitsposition 0;
BA_ "GenSigAutoGenSnd" SG_ 916 LWR_Sicherheitsposition 0;
BA_ "GenSigSendType" SG_ 916 LWR_Sicherheitsposition 7;
BA_ "NWM-WakeupAllowed" SG_ 916 LWR_Sicherheitsposition 0;
BA_ "GenSigTimeoutMsg_Gateway_C6" SG_ 916 LWR_Sicherheitsposition 916;
BA_ "GenSigAutoGenDsp" SG_ 916 Sollwert_LD_EVG 0;
BA_ "GenSigAutoGenSnd" SG_ 916 Sollwert_LD_EVG 0;
BA_ "GenSigSendType" SG_ 916 Sollwert_LD_EVG 7;
BA_ "GenSigStartValue" SG_ 916 Sollwert_LD_EVG 254;
BA_ "NWM-WakeupAllowed" SG_ 916 Sollwert_LD_EVG 0;
BA_ "GenSigTimeoutMsg_Gateway_C6" SG_ 916 Sollwert_LD_EVG 916;
BA_ "GenSigAutoGenDsp" SG_ 916 Stellung_Schrittmotoren 0;
BA_ "GenSigAutoGenSnd" SG_ 916 Stellung_Schrittmotoren 0;
BA_ "GenSigSendType" SG_ 916 Stellung_Schrittmotoren 7;
BA_ "GenSigStartValue" SG_ 916 Stellung_Schrittmotoren 254;
BA_ "NWM-WakeupAllowed" SG_ 916 Stellung_Schrittmotoren 0;
BA_ "GenSigTimeoutMsg_Gateway_C6" SG_ 916 Stellung_Schrittmotoren 916;
BA_ "GenSigAutoGenDsp" SG_ 194 BZ_LWS1 0;
BA_ "GenSigAutoGenSnd" SG_ 194 BZ_LWS1 0;
BA_ "GenSigSendType" SG_ 194 BZ_LWS1 7;
BA_ "NWM-WakeupAllowed" SG_ 194 BZ_LWS1 0;
BA_ "GenSigTimeoutMsg__4CL_C6" SG_ 194 BZ_LWS1 194;
BA_ "GenSigTimeoutMsg_DME_SIMOS6_C6" SG_ 194 BZ_LWS1 194;
BA_ "GenSigTimeoutMsg_ESP8_C6" SG_ 194 BZ_LWS1 194;
BA_ "GenSigTimeoutMsg_Gateway_C6" SG_ 194 BZ_LWS1 194;
BA_ "GenSigAutoGenDsp" SG_ 194 Codierdaten 0;
BA_ "GenSigAutoGenSnd" SG_ 194 Codierdaten 0;
BA_ "GenSigSendType" SG_ 194 Codierdaten 7;
BA_ "NWM-WakeupAllowed" SG_ 194 Codierdaten 0;
BA_ "GenSigTimeoutMsg_ESP8_C6" SG_ 194 Codierdaten 194;
BA_ "GenSigTimeoutMsg_Gateway_C6" SG_ 194 Codierdaten 194;
BA_ "GenSigAutoGenDsp" SG_ 194 Interner_Status 0;
BA_ "GenSigAutoGenSnd" SG_ 194 Interner_Status 0;
BA_ "GenSigSendType" SG_ 194 Interner_Status 7;
BA_ "GenSigStartValue" SG_ 194 Interner_Status 1;
BA_ "NWM-WakeupAllowed" SG_ 194 Interner_Status 0;
BA_ "GenSigTimeoutMsg__4CL_C6" SG_ 194 Interner_Status 194;
BA_ "GenSigTimeoutMsg_DME_ME7_MED9_C6" SG_ 194 Interner_Status 194;
BA_ "GenSigTimeoutMsg_DME_SIMOS6_C6" SG_ 194 Interner_Status 194;
BA_ "GenSigTimeoutMsg_ESP8_C6" SG_ 194 Interner_Status 194;
BA_ "GenSigTimeoutMsg_Gateway_C6" SG_ 194 Interner_Status 194;
BA_ "GenSigTimeoutMsg_LWR_AFS_C6" SG_ 194 Interner_Status 194;
BA_ "GenSigAutoGenDsp" SG_ 194 Lenkradwinkel 0;
BA_ "GenSigAutoGenSnd" SG_ 194 Lenkradwinkel 0;
BA_ "GenSigSendType" SG_ 194 Lenkradwinkel 7;
BA_ "NWM-WakeupAllowed" SG_ 194 Lenkradwinkel 0;
BA_ "GenSigTimeoutMsg__4CL_C6" SG_ 194 Lenkradwinkel 194;
BA_ "GenSigTimeoutMsg__6HP_C6" SG_ 194 Lenkradwinkel 194;
BA_ "GenSigTimeoutMsg_DME_ME7_MED9_C6" SG_ 194 Lenkradwinkel 194;
BA_ "GenSigTimeoutMsg_DME_SIMOS6_C6" SG_ 194 Lenkradwinkel 194;
BA_ "GenSigTimeoutMsg_ESP8_C6" SG_ 194 Lenkradwinkel 194;
BA_ "GenSigTimeoutMsg_Gateway_C6" SG_ 194 Lenkradwinkel 194;
BA_ "GenSigTimeoutMsg_LWR_AFS_C6" SG_ 194 Lenkradwinkel 194;
BA_ "GenSigAutoGenDsp" SG_ 194 Lenkradwinkel_Sign 0;
BA_ "GenSigAutoGenSnd" SG_ 194 Lenkradwinkel_Sign 0;
BA_ "GenSigSendType" SG_ 194 Lenkradwinkel_Sign 7;
BA_ "GenSigStartValue" SG_ 194 Lenkradwinkel_Sign 1;
BA_ "NWM-WakeupAllowed" SG_ 194 Lenkradwinkel_Sign 0;
BA_ "GenSigTimeoutMsg__4CL_C6" SG_ 194 Lenkradwinkel_Sign 194;
BA_ "GenSigTimeoutMsg__6HP_C6" SG_ 194 Lenkradwinkel_Sign 194;
BA_ "GenSigTimeoutMsg_DME_SIMOS6_C6" SG_ 194 Lenkradwinkel_Sign 194;
BA_ "GenSigTimeoutMsg_ESP8_C6" SG_ 194 Lenkradwinkel_Sign 194;
BA_ "GenSigTimeoutMsg_Gateway_C6" SG_ 194 Lenkradwinkel_Sign 194;
BA_ "GenSigTimeoutMsg_LWR_AFS_C6" SG_ 194 Lenkradwinkel_Sign 194;
BA_ "GenSigAutoGenDsp" SG_ 194 Lenkradwinkelgeschw_Sign 0;
BA_ "GenSigAutoGenSnd" SG_ 194 Lenkradwinkelgeschw_Sign 0;
BA_ "GenSigSendType" SG_ 194 Lenkradwinkelgeschw_Sign 7;
BA_ "GenSigStartValue" SG_ 194 Lenkradwinkelgeschw_Sign 1;
BA_ "NWM-WakeupAllowed" SG_ 194 Lenkradwinkelgeschw_Sign 0;
BA_ "GenSigTimeoutMsg__4CL_C6" SG_ 194 Lenkradwinkelgeschw_Sign 194;
BA_ "GenSigTimeoutMsg_DME_SIMOS6_C6" SG_ 194 Lenkradwinkelgeschw_Sign 194;
BA_ "GenSigTimeoutMsg_Gateway_C6" SG_ 194 Lenkradwinkelgeschw_Sign 194;
BA_ "GenSigAutoGenDsp" SG_ 194 Lenkradwinkelgeschwindigkeit 0;
BA_ "GenSigAutoGenSnd" SG_ 194 Lenkradwinkelgeschwindigkeit 0;
BA_ "GenSigSendType" SG_ 194 Lenkradwinkelgeschwindigkeit 7;
BA_ "NWM-WakeupAllowed" SG_ 194 Lenkradwinkelgeschwindigkeit 0;
BA_ "GenSigTimeoutMsg__4CL_C6" SG_ 194 Lenkradwinkelgeschwindigkeit 194;
BA_ "GenSigTimeoutMsg_DME_ME7_MED9_C6" SG_ 194 Lenkradwinkelgeschwindigkeit 194;
BA_ "GenSigTimeoutMsg_DME_SIMOS6_C6" SG_ 194 Lenkradwinkelgeschwindigkeit 194;
BA_ "GenSigTimeoutMsg_Gateway_C6" SG_ 194 Lenkradwinkelgeschwindigkeit 194;
BA_ "GenSigAutoGenDsp" SG_ 194 Lenkwinkel_ID 0;
BA_ "GenSigAutoGenSnd" SG_ 194 Lenkwinkel_ID 0;
BA_ "GenSigSendType" SG_ 194 Lenkwinkel_ID 7;
BA_ "NWM-WakeupAllowed" SG_ 194 Lenkwinkel_ID 0;
BA_ "GenSigTimeoutMsg_ESP8_C6" SG_ 194 Lenkwinkel_ID 194;
BA_ "GenSigTimeoutMsg_Gateway_C6" SG_ 194 Lenkwinkel_ID 194;
BA_ "GenSigAutoGenDsp" SG_ 194 Pruefsumme_LWS1 0;
BA_ "GenSigAutoGenSnd" SG_ 194 Pruefsumme_LWS1 0;
BA_ "GenSigSendType" SG_ 194 Pruefsumme_LWS1 7;
BA_ "NWM-WakeupAllowed" SG_ 194 Pruefsumme_LWS1 0;
BA_ "GenSigTimeoutMsg__4CL_C6" SG_ 194 Pruefsumme_LWS1 194;
BA_ "GenSigTimeoutMsg_DME_SIMOS6_C6" SG_ 194 Pruefsumme_LWS1 194;
BA_ "GenSigTimeoutMsg_ESP8_C6" SG_ 194 Pruefsumme_LWS1 194;
BA_ "GenSigTimeoutMsg_Gateway_C6" SG_ 194 Pruefsumme_LWS1 194;
BA_ "GenSigAutoGenDsp" SG_ 194 Quelle_fuer_Init 0;
BA_ "GenSigAutoGenSnd" SG_ 194 Quelle_fuer_Init 0;
BA_ "GenSigSendType" SG_ 194 Quelle_fuer_Init 7;
BA_ "NWM-WakeupAllowed" SG_ 194 Quelle_fuer_Init 0;
BA_ "GenSigTimeoutMsg_Gateway_C6" SG_ 194 Quelle_fuer_Init 194;
BA_ "GenSigAutoGenDsp" SG_ 194 Status_KL30_Ausfall 0;
BA_ "GenSigAutoGenSnd" SG_ 194 Status_KL30_Ausfall 0;
BA_ "GenSigSendType" SG_ 194 Status_KL30_Ausfall 7;
BA_ "NWM-WakeupAllowed" SG_ 194 Status_KL30_Ausfall 0;
BA_ "GenSigTimeoutMsg_Gateway_C6" SG_ 194 Status_KL30_Ausfall 194;
BA_ "GenSigAutoGenDsp" SG_ 1984 Command_Code_Word 0;
BA_ "GenSigAutoGenSnd" SG_ 1984 Command_Code_Word 0;
BA_ "GenSigSendType" SG_ 1984 Command_Code_Word 7;
BA_ "NWM-WakeupAllowed" SG_ 1984 Command_Code_Word 0;
BA_ "GenSigTimeoutMsg_LWS_C6" SG_ 1984 Command_Code_Word 1984;
BA_ "GenSigAutoGenDsp" SG_ 1984 LWS_Identifier 0;
BA_ "GenSigAutoGenSnd" SG_ 1984 LWS_Identifier 0;
BA_ "GenSigSendType" SG_ 1984 LWS_Identifier 7;
BA_ "NWM-WakeupAllowed" SG_ 1984 LWS_Identifier 0;
BA_ "GenSigTimeoutMsg_LWS_C6" SG_ 1984 LWS_Identifier 1984;
BA_ "GenSigAutoGenDsp" SG_ 1478 ERR_LOCATION_1 0;
BA_ "GenSigAutoGenSnd" SG_ 1478 ERR_LOCATION_1 0;
BA_ "GenSigSendType" SG_ 1478 ERR_LOCATION_1 7;
BA_ "NWM-WakeupAllowed" SG_ 1478 ERR_LOCATION_1 0;
BA_ "GenSigTimeoutMsg_ESP8_C6" SG_ 1478 ERR_LOCATION_1 1478;
BA_ "GenSigAutoGenDsp" SG_ 1478 ERR_LOCATION_2 0;
BA_ "GenSigAutoGenSnd" SG_ 1478 ERR_LOCATION_2 0;
BA_ "GenSigSendType" SG_ 1478 ERR_LOCATION_2 7;
BA_ "NWM-WakeupAllowed" SG_ 1478 ERR_LOCATION_2 0;
BA_ "GenSigTimeoutMsg_ESP8_C6" SG_ 1478 ERR_LOCATION_2 1478;
BA_ "GenSigAutoGenDsp" SG_ 1478 ERR_LOCATION_3 0;
BA_ "GenSigAutoGenSnd" SG_ 1478 ERR_LOCATION_3 0;
BA_ "GenSigSendType" SG_ 1478 ERR_LOCATION_3 7;
BA_ "NWM-WakeupAllowed" SG_ 1478 ERR_LOCATION_3 0;
BA_ "GenSigTimeoutMsg_ESP8_C6" SG_ 1478 ERR_LOCATION_3 1478;
BA_ "GenSigAutoGenDsp" SG_ 1478 ERR_LOCATION_4 0;
BA_ "GenSigAutoGenSnd" SG_ 1478 ERR_LOCATION_4 0;
BA_ "GenSigSendType" SG_ 1478 ERR_LOCATION_4 7;
BA_ "NWM-WakeupAllowed" SG_ 1478 ERR_LOCATION_4 0;
BA_ "GenSigTimeoutMsg_ESP8_C6" SG_ 1478 ERR_LOCATION_4 1478;
BA_ "GenSigAutoGenDsp" SG_ 1478 LWS_LRW_AKT 0;
BA_ "GenSigAutoGenSnd" SG_ 1478 LWS_LRW_AKT 0;
BA_ "GenSigSendType" SG_ 1478 LWS_LRW_AKT 7;
BA_ "NWM-WakeupAllowed" SG_ 1478 LWS_LRW_AKT 0;
BA_ "GenSigTimeoutMsg_ESP8_C6" SG_ 1478 LWS_LRW_AKT 1478;
BA_ "GenSigAutoGenDsp" SG_ 1478 LWS_SEG_NR 0;
BA_ "GenSigAutoGenSnd" SG_ 1478 LWS_SEG_NR 0;
BA_ "GenSigSendType" SG_ 1478 LWS_SEG_NR 7;
BA_ "NWM-WakeupAllowed" SG_ 1478 LWS_SEG_NR 0;
BA_ "GenSigTimeoutMsg_ESP8_C6" SG_ 1478 LWS_SEG_NR 1478;
BA_ "GenSigAutoGenDsp" SG_ 1478 LWS_STATUS 0;
BA_ "GenSigAutoGenSnd" SG_ 1478 LWS_STATUS 0;
BA_ "GenSigSendType" SG_ 1478 LWS_STATUS 7;
BA_ "NWM-WakeupAllowed" SG_ 1478 LWS_STATUS 0;
BA_ "GenSigTimeoutMsg_ESP8_C6" SG_ 1478 LWS_STATUS 1478;
BA_ "GenSigAutoGenDsp" SG_ 1986 Codierbytes 0;
BA_ "GenSigAutoGenSnd" SG_ 1986 Codierbytes 0;
BA_ "GenSigSendType" SG_ 1986 Codierbytes 7;
BA_ "NWM-WakeupAllowed" SG_ 1986 Codierbytes 0;
BA_ "GenSigTimeoutMsg_LWS_C6" SG_ 1986 Codierbytes 1986;
BA_ "GenSigAutoGenDsp" SG_ 1986 ID_fuer_LWS_Init 0;
BA_ "GenSigAutoGenSnd" SG_ 1986 ID_fuer_LWS_Init 0;
BA_ "GenSigSendType" SG_ 1986 ID_fuer_LWS_Init 7;
BA_ "NWM-WakeupAllowed" SG_ 1986 ID_fuer_LWS_Init 0;
BA_ "GenSigTimeoutMsg_LWS_C6" SG_ 1986 ID_fuer_LWS_Init 1986;
BA_ "GenSigAutoGenDsp" SG_ 640 Fahrerwunschmoment 0;
BA_ "GenSigAutoGenSnd" SG_ 640 Fahrerwunschmoment 0;
BA_ "GenSigSendType" SG_ 640 Fahrerwunschmoment 7;
BA_ "NWM-WakeupAllowed" SG_ 640 Fahrerwunschmoment 0;
BA_ "GenSigTimeoutMsg__4CL_C6" SG_ 640 Fahrerwunschmoment 640;
BA_ "GenSigTimeoutMsg__6HP_C6" SG_ 640 Fahrerwunschmoment 640;
BA_ "GenSigTimeoutMsg_EPB_C6" SG_ 640 Fahrerwunschmoment 640;
BA_ "GenSigTimeoutMsg_ESP8_C6" SG_ 640 Fahrerwunschmoment 640;
BA_ "GenSigTimeoutMsg_Gateway_C6" SG_ 640 Fahrerwunschmoment 640;
BA_ "GenSigAutoGenDsp" SG_ 640 Fahrpedalwert_DK_Poti 0;
BA_ "GenSigAutoGenSnd" SG_ 640 Fahrpedalwert_DK_Poti 0;
BA_ "GenSigSendType" SG_ 640 Fahrpedalwert_DK_Poti 7;
BA_ "NWM-WakeupAllowed" SG_ 640 Fahrpedalwert_DK_Poti 0;
BA_ "GenSigTimeoutMsg__6HP_C6" SG_ 640 Fahrpedalwert_DK_Poti 640;
BA_ "GenSigTimeoutMsg_ESP8_C6" SG_ 640 Fahrpedalwert_DK_Poti 640;
BA_ "GenSigTimeoutMsg_Gateway_C6" SG_ 640 Fahrpedalwert_DK_Poti 640;
BA_ "GenSigAutoGenDsp" SG_ 640 Fahrpedalwert_ungenau 0;
BA_ "GenSigAutoGenSnd" SG_ 640 Fahrpedalwert_ungenau 0;
BA_ "GenSigSendType" SG_ 640 Fahrpedalwert_ungenau 7;
BA_ "NWM-WakeupAllowed" SG_ 640 Fahrpedalwert_ungenau 0;
BA_ "GenSigTimeoutMsg__6HP_C6" SG_ 640 Fahrpedalwert_ungenau 640;
BA_ "GenSigTimeoutMsg_ESP8_C6" SG_ 640 Fahrpedalwert_ungenau 640;
BA_ "GenSigTimeoutMsg_Gateway_C6" SG_ 640 Fahrpedalwert_ungenau 640;
BA_ "GenSigAutoGenDsp" SG_ 640 FStatus_Brems_Momeingr 0;
BA_ "GenSigAutoGenSnd" SG_ 640 FStatus_Brems_Momeingr 0;
BA_ "GenSigSendType" SG_ 640 FStatus_Brems_Momeingr 7;
BA_ "NWM-WakeupAllowed" SG_ 640 FStatus_Brems_Momeingr 0;
BA_ "GenSigTimeoutMsg_ESP8_C6" SG_ 640 FStatus_Brems_Momeingr 640;
BA_ "GenSigTimeoutMsg_Gateway_C6" SG_ 640 FStatus_Brems_Momeingr 640;
BA_ "GenSigAutoGenDsp" SG_ 640 Inneres_Motormoment 0;
BA_ "GenSigAutoGenSnd" SG_ 640 Inneres_Motormoment 0;
BA_ "GenSigSendType" SG_ 640 Inneres_Motormoment 7;
BA_ "NWM-WakeupAllowed" SG_ 640 Inneres_Motormoment 0;
BA_ "GenSigTimeoutMsg__6HP_C6" SG_ 640 Inneres_Motormoment 640;
BA_ "GenSigTimeoutMsg_EPB_C6" SG_ 640 Inneres_Motormoment 640;
BA_ "GenSigTimeoutMsg_ESP8_C6" SG_ 640 Inneres_Motormoment 640;
BA_ "GenSigTimeoutMsg_Gateway_C6" SG_ 640 Inneres_Motormoment 640;
BA_ "GenSigAutoGenDsp" SG_ 640 Inneres_Motormoment_oeE 0;
BA_ "GenSigAutoGenSnd" SG_ 640 Inneres_Motormoment_oeE 0;
BA_ "GenSigSendType" SG_ 640 Inneres_Motormoment_oeE 7;
BA_ "NWM-WakeupAllowed" SG_ 640 Inneres_Motormoment_oeE 0;
BA_ "GenSigTimeoutMsg__6HP_C6" SG_ 640 Inneres_Motormoment_oeE 640;
BA_ "GenSigTimeoutMsg_Gateway_C6" SG_ 640 Inneres_Motormoment_oeE 640;
BA_ "GenSigAutoGenDsp" SG_ 640 Kickdownschalter 0;
BA_ "GenSigAutoGenSnd" SG_ 640 Kickdownschalter 0;
BA_ "GenSigSendType" SG_ 640 Kickdownschalter 7;
BA_ "NWM-WakeupAllowed" SG_ 640 Kickdownschalter 0;
BA_ "GenSigTimeoutMsg__6HP_C6" SG_ 640 Kickdownschalter 640;
BA_ "GenSigTimeoutMsg_Gateway_C6" SG_ 640 Kickdownschalter 640;
BA_ "GenSigAutoGenDsp" SG_ 640 Kupplungsschalter 0;
BA_ "GenSigAutoGenSnd" SG_ 640 Kupplungsschalter 0;
BA_ "GenSigSendType" SG_ 640 Kupplungsschalter 7;
BA_ "NWM-WakeupAllowed" SG_ 640 Kupplungsschalter 0;
BA_ "GenSigTimeoutMsg_EPB_C6" SG_ 640 Kupplungsschalter 640;
BA_ "GenSigTimeoutMsg_ESP8_C6" SG_ 640 Kupplungsschalter 640;
BA_ "GenSigTimeoutMsg_Gateway_C6" SG_ 640 Kupplungsschalter 640;
BA_ "GenSigAutoGenDsp" SG_ 640 Leergasinformation 0;
BA_ "GenSigAutoGenSnd" SG_ 640 Leergasinformation 0;
BA_ "GenSigSendType" SG_ 640 Leergasinformation 7;
BA_ "NWM-WakeupAllowed" SG_ 640 Leergasinformation 0;
BA_ "GenSigTimeoutMsg_EPB_C6" SG_ 640 Leergasinformation 640;
BA_ "GenSigTimeoutMsg_ESP8_C6" SG_ 640 Leergasinformation 640;
BA_ "GenSigTimeoutMsg_Gateway_C6" SG_ 640 Leergasinformation 640;
BA_ "GenSigAutoGenDsp" SG_ 640 Mech_Motor_Verlustmoment 0;
BA_ "GenSigAutoGenSnd" SG_ 640 Mech_Motor_Verlustmoment 0;
BA_ "GenSigSendType" SG_ 640 Mech_Motor_Verlustmoment 7;
BA_ "NWM-WakeupAllowed" SG_ 640 Mech_Motor_Verlustmoment 0;
BA_ "GenSigTimeoutMsg__6HP_C6" SG_ 640 Mech_Motor_Verlustmoment 640;
BA_ "GenSigTimeoutMsg_EPB_C6" SG_ 640 Mech_Motor_Verlustmoment 640;
BA_ "GenSigTimeoutMsg_ESP8_C6" SG_ 640 Mech_Motor_Verlustmoment 640;
BA_ "GenSigTimeoutMsg_Gateway_C6" SG_ 640 Mech_Motor_Verlustmoment 640;
BA_ "GenSigAutoGenDsp" SG_ 640 Mmot_Angabe_ungenau 0;
BA_ "GenSigAutoGenSnd" SG_ 640 Mmot_Angabe_ungenau 0;
BA_ "GenSigSendType" SG_ 640 Mmot_Angabe_ungenau 7;
BA_ "NWM-WakeupAllowed" SG_ 640 Mmot_Angabe_ungenau 0;
BA_ "GenSigTimeoutMsg__6HP_C6" SG_ 640 Mmot_Angabe_ungenau 640;
BA_ "GenSigTimeoutMsg_EPB_C6" SG_ 640 Mmot_Angabe_ungenau 640;
BA_ "GenSigTimeoutMsg_ESP8_C6" SG_ 640 Mmot_Angabe_ungenau 640;
BA_ "GenSigTimeoutMsg_Gateway_C6" SG_ 640 Mmot_Angabe_ungenau 640;
BA_ "GenSigAutoGenDsp" SG_ 640 Motordrehzahl 0;
BA_ "GenSigAutoGenSnd" SG_ 640 Motordrehzahl 0;
BA_ "GenSigSendType" SG_ 640 Motordrehzahl 7;
BA_ "NWM-WakeupAllowed" SG_ 640 Motordrehzahl 0;
BA_ "GenSigTimeoutMsg__4CL_C6" SG_ 640 Motordrehzahl 640;
BA_ "GenSigTimeoutMsg__6HP_C6" SG_ 640 Motordrehzahl 640;
BA_ "GenSigTimeoutMsg_EPB_C6" SG_ 640 Motordrehzahl 640;
BA_ "GenSigTimeoutMsg_ESP8_C6" SG_ 640 Motordrehzahl 640;
BA_ "GenSigTimeoutMsg_Gateway_C6" SG_ 640 Motordrehzahl 640;
BA_ "GenSigTimeoutMsg_LWR_AFS_C6" SG_ 640 Motordrehzahl 640;
BA_ "GenSigAutoGenDsp" SG_ 640 Time_Out_Bremse 0;
BA_ "GenSigAutoGenSnd" SG_ 640 Time_Out_Bremse 0;
BA_ "GenSigSendType" SG_ 640 Time_Out_Bremse 7;
BA_ "NWM-WakeupAllowed" SG_ 640 Time_Out_Bremse 0;
BA_ "GenSigTimeoutMsg_ESP8_C6" SG_ 640 Time_Out_Bremse 640;
BA_ "GenSigTimeoutMsg_Gateway_C6" SG_ 640 Time_Out_Bremse 640;
BA_ "GenSigAutoGenDsp" SG_ 648 Ansteuerung_Klima 0;
BA_ "GenSigAutoGenSnd" SG_ 648 Ansteuerung_Klima 0;
BA_ "GenSigSendType" SG_ 648 Ansteuerung_Klima 7;
BA_ "NWM-WakeupAllowed" SG_ 648 Ansteuerung_Klima 0;
BA_ "GenSigTimeoutMsg__6HP_C6" SG_ 648 Ansteuerung_Klima 648;
BA_ "GenSigTimeoutMsg_Gateway_C6" SG_ 648 Ansteuerung_Klima 648;
BA_ "GenSigAutoGenDsp" SG_ 648 Begrenzungsmoment 0;
BA_ "GenSigAutoGenSnd" SG_ 648 Begrenzungsmoment 0;
BA_ "GenSigSendType" SG_ 648 Begrenzungsmoment 7;
BA_ "GenSigStartValue" SG_ 648 Begrenzungsmoment 254;
BA_ "NWM-WakeupAllowed" SG_ 648 Begrenzungsmoment 0;
BA_ "GenSigTimeoutMsg_Gateway_C6" SG_ 648 Begrenzungsmoment 648;
BA_ "GenSigAutoGenDsp" SG_ 648 Bremslichtschalter_Motor 0;
BA_ "GenSigAutoGenSnd" SG_ 648 Bremslichtschalter_Motor 0;
BA_ "GenSigSendType" SG_ 648 Bremslichtschalter_Motor 7;
BA_ "NWM-WakeupAllowed" SG_ 648 Bremslichtschalter_Motor 0;
BA_ "GenSigTimeoutMsg__6HP_C6" SG_ 648 Bremslichtschalter_Motor 648;
BA_ "GenSigTimeoutMsg_Gateway_C6" SG_ 648 Bremslichtschalter_Motor 648;
BA_ "GenSigAutoGenDsp" SG_ 648 Bremstestschalter_Motor 0;
BA_ "GenSigAutoGenSnd" SG_ 648 Bremstestschalter_Motor 0;
BA_ "GenSigSendType" SG_ 648 Bremstestschalter_Motor 7;
BA_ "NWM-WakeupAllowed" SG_ 648 Bremstestschalter_Motor 0;
BA_ "GenSigTimeoutMsg__6HP_C6" SG_ 648 Bremstestschalter_Motor 648;
BA_ "GenSigTimeoutMsg_Gateway_C6" SG_ 648 Bremstestschalter_Motor 648;
BA_ "GenSigAutoGenDsp" SG_ 648 CAN_Stand 0;
BA_ "GenSigAutoGenSnd" SG_ 648 CAN_Stand 0;
BA_ "GenSigSendType" SG_ 648 CAN_Stand 7;
BA_ "NWM-WakeupAllowed" SG_ 648 CAN_Stand 0;
BA_ "GenSigTimeoutMsg_Gateway_C6" SG_ 648 CAN_Stand 648;
BA_ "GenSigAutoGenDsp" SG_ 648 FStatus_Kuehlmitteltemp_Motor 0;
BA_ "GenSigAutoGenSnd" SG_ 648 FStatus_Kuehlmitteltemp_Motor 0;
BA_ "GenSigSendType" SG_ 648 FStatus_Kuehlmitteltemp_Motor 7;
BA_ "NWM-WakeupAllowed" SG_ 648 FStatus_Kuehlmitteltemp_Motor 0;
BA_ "GenSigTimeoutMsg__6HP_C6" SG_ 648 FStatus_Kuehlmitteltemp_Motor 648;
BA_ "GenSigTimeoutMsg_Gateway_C6" SG_ 648 FStatus_Kuehlmitteltemp_Motor 648;
BA_ "GenSigAutoGenDsp" SG_ 648 Getriebecode 0;
BA_ "GenSigAutoGenSnd" SG_ 648 Getriebecode 0;
BA_ "GenSigSendType" SG_ 648 Getriebecode 7;
BA_ "NWM-WakeupAllowed" SG_ 648 Getriebecode 0;
BA_ "GenSigTimeoutMsg_Gateway_C6" SG_ 648 Getriebecode 648;
BA_ "GenSigAutoGenDsp" SG_ 648 GRA_auf_angez_Geschw 1;
BA_ "GenSigAutoGenSnd" SG_ 648 GRA_auf_angez_Geschw 1;
BA_ "GenSigSendType" SG_ 648 GRA_auf_angez_Geschw 7;
BA_ "NWM-WakeupAllowed" SG_ 648 GRA_auf_angez_Geschw 0;
BA_ "GenSigTimeoutMsg_Gateway_C6" SG_ 648 GRA_auf_angez_Geschw 648;
BA_ "GenSigAutoGenDsp" SG_ 648 GRA_Status 0;
BA_ "GenSigAutoGenSnd" SG_ 648 GRA_Status 0;
BA_ "GenSigSendType" SG_ 648 GRA_Status 7;
BA_ "NWM-WakeupAllowed" SG_ 648 GRA_Status 0;
BA_ "GenSigTimeoutMsg__6HP_C6" SG_ 648 GRA_Status 648;
BA_ "GenSigTimeoutMsg_Gateway_C6" SG_ 648 GRA_Status 648;
BA_ "GenSigAutoGenDsp" SG_ 648 Kuehlmitteltemperatur 0;
BA_ "GenSigAutoGenSnd" SG_ 648 Kuehlmitteltemperatur 0;
BA_ "GenSigSendType" SG_ 648 Kuehlmitteltemperatur 7;
BA_ "NWM-WakeupAllowed" SG_ 648 Kuehlmitteltemperatur 0;
BA_ "GenSigTimeoutMsg__6HP_C6" SG_ 648 Kuehlmitteltemperatur 648;
BA_ "GenSigTimeoutMsg_Gateway_C6" SG_ 648 Kuehlmitteltemperatur 648;
BA_ "GenSigAutoGenDsp" SG_ 648 Leerlaufsolldrehzahl 0;
BA_ "GenSigAutoGenSnd" SG_ 648 Leerlaufsolldrehzahl 0;
BA_ "GenSigSendType" SG_ 648 Leerlaufsolldrehzahl 7;
BA_ "NWM-WakeupAllowed" SG_ 648 Leerlaufsolldrehzahl 0;
BA_ "GenSigTimeoutMsg__6HP_C6" SG_ 648 Leerlaufsolldrehzahl 648;
BA_ "GenSigTimeoutMsg_Gateway_C6" SG_ 648 Leerlaufsolldrehzahl 648;
BA_ "GenSigAutoGenDsp" SG_ 648 MDI_max 0;
BA_ "GenSigAutoGenSnd" SG_ 648 MDI_max 0;
BA_ "GenSigSendType" SG_ 648 MDI_max 7;
BA_ "NWM-WakeupAllowed" SG_ 648 MDI_max 0;
BA_ "GenSigTimeoutMsg__6HP_C6" SG_ 648 MDI_max 648;
BA_ "GenSigTimeoutMsg_EPB_C6" SG_ 648 MDI_max 648;
BA_ "GenSigTimeoutMsg_ESP8_C6" SG_ 648 MDI_max 648;
BA_ "GenSigTimeoutMsg_Gateway_C6" SG_ 648 MDI_max 648;
BA_ "GenSigAutoGenDsp" SG_ 648 Min_Mmot__ZW_Rueckn 0;
BA_ "GenSigAutoGenSnd" SG_ 648 Min_Mmot__ZW_Rueckn 0;
BA_ "GenSigSendType" SG_ 648 Min_Mmot__ZW_Rueckn 7;
BA_ "NWM-WakeupAllowed" SG_ 648 Min_Mmot__ZW_Rueckn 0;
BA_ "GenSigTimeoutMsg_ESP8_C6" SG_ 648 Min_Mmot__ZW_Rueckn 648;
BA_ "GenSigTimeoutMsg_Gateway_C6" SG_ 648 Min_Mmot__ZW_Rueckn 648;
BA_ "GenSigAutoGenDsp" SG_ 648 Motorcode 0;
BA_ "GenSigAutoGenSnd" SG_ 648 Motorcode 0;
BA_ "GenSigSendType" SG_ 648 Motorcode 7;
BA_ "NWM-WakeupAllowed" SG_ 648 Motorcode 0;
BA_ "GenSigTimeoutMsg_Gateway_C6" SG_ 648 Motorcode 648;
BA_ "GenSigAutoGenDsp" SG_ 648 Mux_Code_Motor2 0;
BA_ "GenSigAutoGenSnd" SG_ 648 Mux_Code_Motor2 0;
BA_ "GenSigSendType" SG_ 648 Mux_Code_Motor2 7;
BA_ "NWM-WakeupAllowed" SG_ 648 Mux_Code_Motor2 0;
BA_ "GenSigTimeoutMsg__6HP_C6" SG_ 648 Mux_Code_Motor2 648;
BA_ "GenSigTimeoutMsg_EPB_C6" SG_ 648 Mux_Code_Motor2 648;
BA_ "GenSigTimeoutMsg_ESP8_C6" SG_ 648 Mux_Code_Motor2 648;
BA_ "GenSigTimeoutMsg_Gateway_C6" SG_ 648 Mux_Code_Motor2 648;
BA_ "GenSigAutoGenDsp" SG_ 648 OBD2_Freeze_Frame 0;
BA_ "GenSigAutoGenSnd" SG_ 648 OBD2_Freeze_Frame 0;
BA_ "GenSigSendType" SG_ 648 OBD2_Freeze_Frame 7;
BA_ "NWM-WakeupAllowed" SG_ 648 OBD2_Freeze_Frame 0;
BA_ "GenSigTimeoutMsg_Gateway_C6" SG_ 648 OBD2_Freeze_Frame 648;
BA_ "GenSigAutoGenDsp" SG_ 648 Soll_Geschw_GRA 0;
BA_ "GenSigAutoGenSnd" SG_ 648 Soll_Geschw_GRA 0;
BA_ "GenSigSendType" SG_ 648 Soll_Geschw_GRA 7;
BA_ "NWM-WakeupAllowed" SG_ 648 Soll_Geschw_GRA 0;
BA_ "GenSigTimeoutMsg__6HP_C6" SG_ 648 Soll_Geschw_GRA 648;
BA_ "GenSigTimeoutMsg_Gateway_C6" SG_ 648 Soll_Geschw_GRA 648;
BA_ "GenSigAutoGenDsp" SG_ 648 Status_Normalbetrieb 0;
BA_ "GenSigAutoGenSnd" SG_ 648 Status_Normalbetrieb 0;
BA_ "GenSigSendType" SG_ 648 Status_Normalbetrieb 7;
BA_ "NWM-WakeupAllowed" SG_ 648 Status_Normalbetrieb 0;
BA_ "GenSigTimeoutMsg__6HP_C6" SG_ 648 Status_Normalbetrieb 648;
BA_ "GenSigTimeoutMsg_Gateway_C6" SG_ 648 Status_Normalbetrieb 648;
BA_ "GenSigAutoGenDsp" SG_ 896 Ansauglufttemperatur 0;
BA_ "GenSigAutoGenSnd" SG_ 896 Ansauglufttemperatur 0;
BA_ "GenSigSendType" SG_ 896 Ansauglufttemperatur 7;
BA_ "NWM-WakeupAllowed" SG_ 896 Ansauglufttemperatur 0;
BA_ "GenSigTimeoutMsg_Gateway_C6" SG_ 896 Ansauglufttemperatur 896;
BA_ "GenSigAutoGenDsp" SG_ 896 Fahrpedal_Rohsignal 0;
BA_ "GenSigAutoGenSnd" SG_ 896 Fahrpedal_Rohsignal 0;
BA_ "GenSigSendType" SG_ 896 Fahrpedal_Rohsignal 7;
BA_ "NWM-WakeupAllowed" SG_ 896 Fahrpedal_Rohsignal 0;
BA_ "GenSigTimeoutMsg_EPB_C6" SG_ 896 Fahrpedal_Rohsignal 896;
BA_ "GenSigTimeoutMsg_Gateway_C6" SG_ 896 Fahrpedal_Rohsignal 896;
BA_ "GenSigAutoGenDsp" SG_ 896 Fahrpedalgradient 0;
BA_ "GenSigAutoGenSnd" SG_ 896 Fahrpedalgradient 0;
BA_ "GenSigSendType" SG_ 896 Fahrpedalgradient 7;
BA_ "NWM-WakeupAllowed" SG_ 896 Fahrpedalgradient 0;
BA_ "GenSigTimeoutMsg_Gateway_C6" SG_ 896 Fahrpedalgradient 896;
BA_ "GenSigAutoGenDsp" SG_ 896 Fahrpedalwert_ungenau 0;
BA_ "GenSigAutoGenSnd" SG_ 896 Fahrpedalwert_ungenau 0;
BA_ "GenSigSendType" SG_ 896 Fahrpedalwert_ungenau 7;
BA_ "NWM-WakeupAllowed" SG_ 896 Fahrpedalwert_ungenau 0;
BA_ "GenSigTimeoutMsg_EPB_C6" SG_ 896 Fahrpedalwert_ungenau 896;
BA_ "GenSigTimeoutMsg_Gateway_C6" SG_ 896 Fahrpedalwert_ungenau 896;
BA_ "GenSigAutoGenDsp" SG_ 896 FStatus_Ansauglufttemp 0;
BA_ "GenSigAutoGenSnd" SG_ 896 FStatus_Ansauglufttemp 0;
BA_ "GenSigSendType" SG_ 896 FStatus_Ansauglufttemp 7;
BA_ "NWM-WakeupAllowed" SG_ 896 FStatus_Ansauglufttemp 0;
BA_ "GenSigTimeoutMsg_Gateway_C6" SG_ 896 FStatus_Ansauglufttemp 896;
BA_ "GenSigAutoGenDsp" SG_ 896 Kein_EGas 0;
BA_ "GenSigAutoGenSnd" SG_ 896 Kein_EGas 0;
BA_ "GenSigSendType" SG_ 896 Kein_EGas 7;
BA_ "NWM-WakeupAllowed" SG_ 896 Kein_EGas 0;
BA_ "GenSigTimeoutMsg_Gateway_C6" SG_ 896 Kein_EGas 896;
BA_ "GenSigAutoGenDsp" SG_ 896 Kein_Start_Stop 0;
BA_ "GenSigAutoGenSnd" SG_ 896 Kein_Start_Stop 0;
BA_ "GenSigSendType" SG_ 896 Kein_Start_Stop 7;
BA_ "NWM-WakeupAllowed" SG_ 896 Kein_Start_Stop 0;
BA_ "GenSigTimeoutMsg_Gateway_C6" SG_ 896 Kein_Start_Stop 896;
BA_ "GenSigAutoGenDsp" SG_ 896 Motordrehzahlbeeinflussung 0;
BA_ "GenSigAutoGenSnd" SG_ 896 Motordrehzahlbeeinflussung 0;
BA_ "GenSigSendType" SG_ 896 Motordrehzahlbeeinflussung 7;
BA_ "NWM-WakeupAllowed" SG_ 896 Motordrehzahlbeeinflussung 0;
BA_ "GenSigTimeoutMsg_Gateway_C6" SG_ 896 Motordrehzahlbeeinflussung 896;
BA_ "GenSigAutoGenDsp" SG_ 896 Motorwunschdrehzahl 0;
BA_ "GenSigAutoGenSnd" SG_ 896 Motorwunschdrehzahl 0;
BA_ "GenSigSendType" SG_ 896 Motorwunschdrehzahl 7;
BA_ "NWM-WakeupAllowed" SG_ 896 Motorwunschdrehzahl 0;
BA_ "GenSigTimeoutMsg_Gateway_C6" SG_ 896 Motorwunschdrehzahl 896;
BA_ "GenSigAutoGenDsp" SG_ 896 Motorwunschdrehzahlprioritaet 0;
BA_ "GenSigAutoGenSnd" SG_ 896 Motorwunschdrehzahlprioritaet 0;
BA_ "GenSigSendType" SG_ 896 Motorwunschdrehzahlprioritaet 7;
BA_ "NWM-WakeupAllowed" SG_ 896 Motorwunschdrehzahlprioritaet 0;
BA_ "GenSigTimeoutMsg_Gateway_C6" SG_ 896 Motorwunschdrehzahlprioritaet 896;
BA_ "GenSigAutoGenDsp" SG_ 896 Radwunschmoment 0;
BA_ "GenSigAutoGenSnd" SG_ 896 Radwunschmoment 0;
BA_ "GenSigSendType" SG_ 896 Radwunschmoment 7;
BA_ "NWM-WakeupAllowed" SG_ 896 Radwunschmoment 0;
BA_ "GenSigTimeoutMsg_Gateway_C6" SG_ 896 Radwunschmoment 896;
BA_ "GenSigAutoGenDsp" SG_ 896 Signum_Fahrpedalgradient 1;
BA_ "GenSigAutoGenSnd" SG_ 896 Signum_Fahrpedalgradient 1;
BA_ "GenSigSendType" SG_ 896 Signum_Fahrpedalgradient 7;
BA_ "NWM-WakeupAllowed" SG_ 896 Signum_Fahrpedalgradient 0;
BA_ "GenSigTimeoutMsg_Gateway_C6" SG_ 896 Signum_Fahrpedalgradient 896;
BA_ "GenSigAutoGenDsp" SG_ 896 Signum_Rwmom 0;
BA_ "GenSigAutoGenSnd" SG_ 896 Signum_Rwmom 0;
BA_ "GenSigSendType" SG_ 896 Signum_Rwmom 7;
BA_ "NWM-WakeupAllowed" SG_ 896 Signum_Rwmom 0;
BA_ "GenSigTimeoutMsg_Gateway_C6" SG_ 896 Signum_Rwmom 896;
BA_ "GenSigAutoGenDsp" SG_ 896 Steuerungsbit_Fahrpedalgradient 0;
BA_ "GenSigAutoGenSnd" SG_ 896 Steuerungsbit_Fahrpedalgradient 0;
BA_ "GenSigSendType" SG_ 896 Steuerungsbit_Fahrpedalgradient 7;
BA_ "NWM-WakeupAllowed" SG_ 896 Steuerungsbit_Fahrpedalgradient 0;
BA_ "GenSigTimeoutMsg_Gateway_C6" SG_ 896 Steuerungsbit_Fahrpedalgradient 896;
BA_ "GenSigAutoGenDsp" SG_ 896 Vorgluehmeldung 0;
BA_ "GenSigAutoGenSnd" SG_ 896 Vorgluehmeldung 0;
BA_ "GenSigSendType" SG_ 896 Vorgluehmeldung 7;
BA_ "NWM-WakeupAllowed" SG_ 896 Vorgluehmeldung 0;
BA_ "GenSigTimeoutMsg_Gateway_C6" SG_ 896 Vorgluehmeldung 896;
BA_ "GenSigAutoGenDsp" SG_ 1152 Abgastyp 0;
BA_ "GenSigAutoGenSnd" SG_ 1152 Abgastyp 0;
BA_ "GenSigSendType" SG_ 1152 Abgastyp 7;
BA_ "NWM-WakeupAllowed" SG_ 1152 Abgastyp 0;
BA_ "GenSigTimeoutMsg__6HP_C6" SG_ 1152 Abgastyp 1152;
BA_ "GenSigTimeoutMsg_Gateway_C6" SG_ 1152 Abgastyp 1152;
BA_ "GenSigAutoGenDsp" SG_ 1152 Anlasser_Ausspuren 0;
BA_ "GenSigAutoGenSnd" SG_ 1152 Anlasser_Ausspuren 0;
BA_ "GenSigSendType" SG_ 1152 Anlasser_Ausspuren 7;
BA_ "NWM-WakeupAllowed" SG_ 1152 Anlasser_Ausspuren 0;
BA_ "GenSigTimeoutMsg_Gateway_C6" SG_ 1152 Anlasser_Ausspuren 1152;
BA_ "GenSigAutoGenDsp" SG_ 1152 Anlasser_Freigabe 0;
BA_ "GenSigAutoGenSnd" SG_ 1152 Anlasser_Freigabe 0;
BA_ "GenSigSendType" SG_ 1152 Anlasser_Freigabe 7;
BA_ "NWM-WakeupAllowed" SG_ 1152 Anlasser_Freigabe 0;
BA_ "GenSigTimeoutMsg_Gateway_C6" SG_ 1152 Anlasser_Freigabe 1152;
BA_ "GenSigAutoGenDsp" SG_ 1152 CHK_Motor5 0;
BA_ "GenSigAutoGenSnd" SG_ 1152 CHK_Motor5 0;
BA_ "GenSigSendType" SG_ 1152 CHK_Motor5 7;
BA_ "NWM-WakeupAllowed" SG_ 1152 CHK_Motor5 0;
BA_ "GenSigTimeoutMsg_ESP8_C6" SG_ 1152 CHK_Motor5 1152;
BA_ "GenSigTimeoutMsg_Gateway_C6" SG_ 1152 CHK_Motor5 1152;
BA_ "GenSigAutoGenDsp" SG_ 1152 Doppelte_Momente 0;
BA_ "GenSigAutoGenSnd" SG_ 1152 Doppelte_Momente 0;
BA_ "GenSigSendType" SG_ 1152 Doppelte_Momente 7;
BA_ "NWM-WakeupAllowed" SG_ 1152 Doppelte_Momente 0;
BA_ "GenSigTimeoutMsg__6HP_C6" SG_ 1152 Doppelte_Momente 1152;
BA_ "GenSigTimeoutMsg_ESP8_C6" SG_ 1152 Doppelte_Momente 1152;
BA_ "GenSigTimeoutMsg_Gateway_C6" SG_ 1152 Doppelte_Momente 1152;
BA_ "GenSigAutoGenDsp" SG_ 1152 Drehzahl_max_Drehmoment 0;
BA_ "GenSigAutoGenSnd" SG_ 1152 Drehzahl_max_Drehmoment 0;
BA_ "GenSigSendType" SG_ 1152 Drehzahl_max_Drehmoment 7;
BA_ "NWM-WakeupAllowed" SG_ 1152 Drehzahl_max_Drehmoment 0;
BA_ "GenSigTimeoutMsg_Gateway_C6" SG_ 1152 Drehzahl_max_Drehmoment 1152;
BA_ "GenSigAutoGenDsp" SG_ 1152 Drehzahlmesser_Daempfung 0;
BA_ "GenSigAutoGenSnd" SG_ 1152 Drehzahlmesser_Daempfung 0;
BA_ "GenSigSendType" SG_ 1152 Drehzahlmesser_Daempfung 7;
BA_ "NWM-WakeupAllowed" SG_ 1152 Drehzahlmesser_Daempfung 0;
BA_ "GenSigTimeoutMsg_Gateway_C6" SG_ 1152 Drehzahlmesser_Daempfung 1152;
BA_ "GenSigAutoGenDsp" SG_ 1152 EGas_Lampe 0;
BA_ "GenSigAutoGenSnd" SG_ 1152 EGas_Lampe 0;
BA_ "GenSigSendType" SG_ 1152 EGas_Lampe 7;
BA_ "NWM-WakeupAllowed" SG_ 1152 EGas_Lampe 0;
BA_ "GenSigTimeoutMsg_Gateway_C6" SG_ 1152 EGas_Lampe 1152;
BA_ "GenSigAutoGenDsp" SG_ 1152 FStatus_BKU_Pumpe 0;
BA_ "GenSigAutoGenSnd" SG_ 1152 FStatus_BKU_Pumpe 0;
BA_ "GenSigSendType" SG_ 1152 FStatus_BKU_Pumpe 7;
BA_ "NWM-WakeupAllowed" SG_ 1152 FStatus_BKU_Pumpe 0;
BA_ "GenSigTimeoutMsg_Gateway_C6" SG_ 1152 FStatus_BKU_Pumpe 1152;
BA_ "GenSigAutoGenDsp" SG_ 1152 GRA_Hauptschalter 0;
BA_ "GenSigAutoGenSnd" SG_ 1152 GRA_Hauptschalter 0;
BA_ "GenSigSendType" SG_ 1152 GRA_Hauptschalter 7;
BA_ "NWM-WakeupAllowed" SG_ 1152 GRA_Hauptschalter 0;
BA_ "GenSigTimeoutMsg_Gateway_C6" SG_ 1152 GRA_Hauptschalter 1152;
BA_ "GenSigAutoGenDsp" SG_ 1152 Heissleuchte 0;
BA_ "GenSigAutoGenSnd" SG_ 1152 Heissleuchte 0;
BA_ "GenSigSendType" SG_ 1152 Heissleuchte 7;
BA_ "NWM-WakeupAllowed" SG_ 1152 Heissleuchte 0;
BA_ "GenSigTimeoutMsg_Gateway_C6" SG_ 1152 Heissleuchte 1152;
BA_ "GenSigAutoGenDsp" SG_ 1152 HLVW_Motor 0;
BA_ "GenSigAutoGenSnd" SG_ 1152 HLVW_Motor 0;
BA_ "GenSigSendType" SG_ 1152 HLVW_Motor 7;
BA_ "NWM-WakeupAllowed" SG_ 1152 HLVW_Motor 0;
BA_ "GenSigTimeoutMsg_Gateway_C6" SG_ 1152 HLVW_Motor 1152;
BA_ "GenSigAutoGenDsp" SG_ 1152 Interlock_Schalter 0;
BA_ "GenSigAutoGenSnd" SG_ 1152 Interlock_Schalter 0;
BA_ "GenSigSendType" SG_ 1152 Interlock_Schalter 7;
BA_ "NWM-WakeupAllowed" SG_ 1152 Interlock_Schalter 0;
BA_ "GenSigTimeoutMsg_Gateway_C6" SG_ 1152 Interlock_Schalter 1152;
BA_ "GenSigAutoGenDsp" SG_ 1152 Kennfeldkuehlung 0;
BA_ "GenSigAutoGenSnd" SG_ 1152 Kennfeldkuehlung 0;
BA_ "GenSigSendType" SG_ 1152 Kennfeldkuehlung 7;
BA_ "NWM-WakeupAllowed" SG_ 1152 Kennfeldkuehlung 0;
BA_ "GenSigTimeoutMsg_Gateway_C6" SG_ 1152 Kennfeldkuehlung 1152;
BA_ "GenSigAutoGenDsp" SG_ 1152 KK_aus 0;
BA_ "GenSigAutoGenSnd" SG_ 1152 KK_aus 0;
BA_ "GenSigSendType" SG_ 1152 KK_aus 7;
BA_ "NWM-WakeupAllowed" SG_ 1152 KK_aus 0;
BA_ "GenSigTimeoutMsg_Gateway_C6" SG_ 1152 KK_aus 1152;
BA_ "GenSigAutoGenDsp" SG_ 1152 KK_Leistungsreduzierung 0;
BA_ "GenSigAutoGenSnd" SG_ 1152 KK_Leistungsreduzierung 0;
BA_ "GenSigSendType" SG_ 1152 KK_Leistungsreduzierung 7;
BA_ "NWM-WakeupAllowed" SG_ 1152 KK_Leistungsreduzierung 0;
BA_ "GenSigTimeoutMsg_Gateway_C6" SG_ 1152 KK_Leistungsreduzierung 1152;
BA_ "GenSigAutoGenDsp" SG_ 1152 Kraftstoffverbrauchsignal 0;
BA_ "GenSigAutoGenSnd" SG_ 1152 Kraftstoffverbrauchsignal 0;
BA_ "GenSigSendType" SG_ 1152 Kraftstoffverbrauchsignal 7;
BA_ "NWM-WakeupAllowed" SG_ 1152 Kraftstoffverbrauchsignal 0;
BA_ "GenSigTimeoutMsg_Gateway_C6" SG_ 1152 Kraftstoffverbrauchsignal 1152;
BA_ "GenSigAutoGenDsp" SG_ 1152 Kuehlerluefteransteuerung 0;
BA_ "GenSigAutoGenSnd" SG_ 1152 Kuehlerluefteransteuerung 0;
BA_ "GenSigSendType" SG_ 1152 Kuehlerluefteransteuerung 7;
BA_ "NWM-WakeupAllowed" SG_ 1152 Kuehlerluefteransteuerung 0;
BA_ "GenSigTimeoutMsg_Gateway_C6" SG_ 1152 Kuehlerluefteransteuerung 1152;
BA_ "GenSigAutoGenDsp" SG_ 1152 Ladekontroll_Lampe 0;
BA_ "GenSigAutoGenSnd" SG_ 1152 Ladekontroll_Lampe 0;
BA_ "GenSigSendType" SG_ 1152 Ladekontroll_Lampe 7;
BA_ "NWM-WakeupAllowed" SG_ 1152 Ladekontroll_Lampe 0;
BA_ "GenSigTimeoutMsg_Gateway_C6" SG_ 1152 Ladekontroll_Lampe 1152;
BA_ "GenSigAutoGenDsp" SG_ 1152 Lampe_Tankdeckelwarnung 0;
BA_ "GenSigAutoGenSnd" SG_ 1152 Lampe_Tankdeckelwarnung 0;
BA_ "GenSigSendType" SG_ 1152 Lampe_Tankdeckelwarnung 7;
BA_ "NWM-WakeupAllowed" SG_ 1152 Lampe_Tankdeckelwarnung 0;
BA_ "GenSigTimeoutMsg_Gateway_C6" SG_ 1152 Lampe_Tankdeckelwarnung 1152;
BA_ "GenSigAutoGenDsp" SG_ 1152 Max_Drehmoment_630Nm 0;
BA_ "GenSigAutoGenSnd" SG_ 1152 Max_Drehmoment_630Nm 0;
BA_ "GenSigSendType" SG_ 1152 Max_Drehmoment_630Nm 7;
BA_ "NWM-WakeupAllowed" SG_ 1152 Max_Drehmoment_630Nm 0;
BA_ "GenSigTimeoutMsg_Gateway_C6" SG_ 1152 Max_Drehmoment_630Nm 1152;
BA_ "GenSigAutoGenDsp" SG_ 1152 Motortext_Bits 0;
BA_ "GenSigAutoGenSnd" SG_ 1152 Motortext_Bits 0;
BA_ "GenSigSendType" SG_ 1152 Motortext_Bits 7;
BA_ "NWM-WakeupAllowed" SG_ 1152 Motortext_Bits 0;
BA_ "GenSigTimeoutMsg_Gateway_C6" SG_ 1152 Motortext_Bits 1152;
BA_ "GenSigAutoGenDsp" SG_ 1152 Motortyp 0;
BA_ "GenSigAutoGenSnd" SG_ 1152 Motortyp 0;
BA_ "GenSigSendType" SG_ 1152 Motortyp 7;
BA_ "NWM-WakeupAllowed" SG_ 1152 Motortyp 0;
BA_ "GenSigTimeoutMsg_Gateway_C6" SG_ 1152 Motortyp 1152;
BA_ "GenSigAutoGenDsp" SG_ 1152 Mux_Code_Motor5 0;
BA_ "GenSigAutoGenSnd" SG_ 1152 Mux_Code_Motor5 0;
BA_ "GenSigSendType" SG_ 1152 Mux_Code_Motor5 7;
BA_ "NWM-WakeupAllowed" SG_ 1152 Mux_Code_Motor5 0;
BA_ "GenSigTimeoutMsg__6HP_C6" SG_ 1152 Mux_Code_Motor5 1152;
BA_ "GenSigTimeoutMsg_Gateway_C6" SG_ 1152 Mux_Code_Motor5 1152;
BA_ "GenSigAutoGenDsp" SG_ 1152 OBD2_Lampe 0;
BA_ "GenSigAutoGenSnd" SG_ 1152 OBD2_Lampe 0;
BA_ "GenSigSendType" SG_ 1152 OBD2_Lampe 7;
BA_ "NWM-WakeupAllowed" SG_ 1152 OBD2_Lampe 0;
BA_ "GenSigTimeoutMsg_Gateway_C6" SG_ 1152 OBD2_Lampe 1152;
BA_ "GenSigAutoGenDsp" SG_ 1152 Partikelfilter_Lampe 0;
BA_ "GenSigAutoGenSnd" SG_ 1152 Partikelfilter_Lampe 0;
BA_ "GenSigSendType" SG_ 1152 Partikelfilter_Lampe 7;
BA_ "NWM-WakeupAllowed" SG_ 1152 Partikelfilter_Lampe 0;
BA_ "GenSigTimeoutMsg_Gateway_C6" SG_ 1152 Partikelfilter_Lampe 1152;
BA_ "GenSigAutoGenDsp" SG_ 1152 Textbit_Tankdeckelwarn 0;
BA_ "GenSigAutoGenSnd" SG_ 1152 Textbit_Tankdeckelwarn 0;
BA_ "GenSigSendType" SG_ 1152 Textbit_Tankdeckelwarn 7;
BA_ "NWM-WakeupAllowed" SG_ 1152 Textbit_Tankdeckelwarn 0;
BA_ "GenSigTimeoutMsg_Gateway_C6" SG_ 1152 Textbit_Tankdeckelwarn 1152;
BA_ "GenSigAutoGenDsp" SG_ 1152 Typ_Startersteuerung 0;
BA_ "GenSigAutoGenSnd" SG_ 1152 Typ_Startersteuerung 0;
BA_ "GenSigSendType" SG_ 1152 Typ_Startersteuerung 7;
BA_ "NWM-WakeupAllowed" SG_ 1152 Typ_Startersteuerung 0;
BA_ "GenSigTimeoutMsg_Gateway_C6" SG_ 1152 Typ_Startersteuerung 1152;
BA_ "GenSigAutoGenDsp" SG_ 1152 Verbrauch_Ueberlauf 0;
BA_ "GenSigAutoGenSnd" SG_ 1152 Verbrauch_Ueberlauf 0;
BA_ "GenSigSendType" SG_ 1152 Verbrauch_Ueberlauf 7;
BA_ "NWM-WakeupAllowed" SG_ 1152 Verbrauch_Ueberlauf 0;
BA_ "GenSigTimeoutMsg_Gateway_C6" SG_ 1152 Verbrauch_Ueberlauf 1152;
BA_ "GenSigAutoGenDsp" SG_ 1152 Vorgluehlampe_Motor 0;
BA_ "GenSigAutoGenSnd" SG_ 1152 Vorgluehlampe_Motor 0;
BA_ "GenSigSendType" SG_ 1152 Vorgluehlampe_Motor 7;
BA_ "NWM-WakeupAllowed" SG_ 1152 Vorgluehlampe_Motor 0;
BA_ "GenSigTimeoutMsg_Gateway_C6" SG_ 1152 Vorgluehlampe_Motor 1152;
VAL_ 1088 Geschwindigkeit_halten 0 "keine_Anforderung" 1 "Geschwindigkeit_halten" ;
VAL_ 1088 Inneres_Sollmotormoment 255 "Fehler" ;
VAL_ 1088 OBD_Status 1 "MIL_ein" 0 "MIL_aus" ;
VAL_ 1088 Fahrwiderstandsindex 255 "Fehler" ;
VAL_ 1088 Status_Wandlerschutz 1 "Schutz_angef" 0 "kein_Schutz" ;
VAL_ 1088 Klimakompressor_aus 0 "keine_Anforderung" 1 "Kompressor_aus" ;
VAL_ 1088 FSPE_Getriebe1 1 "KD_Fehler_eingetr" 0 "kein_KD_Fehler_eingetr" ;
VAL_ 1088 Uebertragungsfunktion_8Bit 255 "Fehler" ;
VAL_ 1088 SIB_Getriebe 1 "Sleep_bereit" 0 "CAN_wird_benoetigt" ;
VAL_ 1088 Wandlerkupplung 0 "WK_geoeffnet" 2 "WK_geschlossen" 3 "Fehler" 1 "WK_geregelt" ;
VAL_ 1088 Aufnahmemoment_Leerlauf 255 "Fehler" ;
VAL_ 1088 Codierung_MSG 1 "Codierung_niO" 0 "Codierung_iO" ;
VAL_ 1088 EGS_Anforderung 0 "keine_Anforderung" 1 "EGS-Anforderung" ;
VAL_ 1088 Getriebeinfo 1 "CVT" 0 "Stufenautomat" ;
VAL_ 1088 Waehlhebelposition 15 "Fehler" 14 "Tippgasse" 0 "Zwischenstellung" 13 "Position_L" 2 "Position_2" 12 "Position_S" 6 "Position_N" 4 "Position_4" 8 "Position_P" 7 "Position_R" 11 "Position_Z2" 1 "Position_1" 9 "Position_RSP" 3 "Position_3" 10 "Position_Z1" 5 "Position_D" ;
VAL_ 1088 Kuehlleistung 3 "Stufe_3" 2 "Stufe_2" 1 "Stufe_1" 0 "OFF" ;
VAL_ 1088 Getriebe_Notlauf 1 "kein_Schalten" 15 "Totalausfall" 2 "Schalten_nach_N" 3 "50Prozent_Schalten" 4 "Fahren_ohne_UeK" 6 "Gang1_Ziel0" 5 "Gang0_Ziel1" 7 "Gang1_Ziel1" ;
VAL_ 1088 Zielgang 3 "Gang_3" 5 "Gang_5" 1 "Gang_1" 4 "Gang_4" 7 "Gang_R" 0 "Gang_P_N" 2 "Gang_2" 6 "1m_Gang" 14 "Istgang_nd" 9 "Gang_7" 8 "Gang_6" 15 "Fehler" ;
VAL_ 1088 Schaltung_aktiv 0 "keine_Schaltung" 1 "Schaltung_laeuft" ;
VAL_ 1088 Motor_aus 0 "Motor_startbereit" 1 "Motor_aus" ;
VAL_ 1088 Geschwindigkeit_Umkehr 1 "Bremsunterstuetzung_notwendig" 0 "keine_Bremsunterstuetzung" ;
VAL_ 1344 Gong_Kuppl_temp_Warn 1 "ein" 0 "aus" ;
VAL_ 1344 Warnungsunterdrueckung 1 "Unterdrueckung" 0 "keine_Unterdrueckung" ;
VAL_ 1344 Shift_Lock_Lampe 1 "SL_Lampe_ein" 0 "SL_Lampe_aus" ;
VAL_ 1344 Leerlaufsolldrehzahl 255 "Fehler" ;
VAL_ 1344 LFR_Adaption 1 "fuer_Adaption_nicht_geeignet" 0 "fuer_Adaption_geeignet" ;
VAL_ 1344 Schubabschaltunterstuetzung 1 "aktiv" 0 "inaktiv" ;
VAL_ 1344 Gradientenbegrenzung 255 "keine_Begrenzung" ;
VAL_ 1344 Drehzahlmesser_Daempfung 0 "normal" 1 "dynamisch" ;
VAL_ 1344 WBA_Blinken 0 "kein_WBA_Blinken" 1 "WBA_Blinken" ;
VAL_ 1344 Zwischengasflag 1 "aktiv" 0 "inaktiv" ;
VAL_ 1100 Getriebeverlustmoment_GRA_ACC 0 "Init" 255 "Fehler" ;
VAL_ 1098 Status_Dyn_Eingriff 7 "Fehler" 5 "MomRed_Getriebeschutz" 1 "reduzierender_Eingriff" 2 "erhoehender_Eingriff" 0 "keine_Anforderung" ;
VAL_ 1098 Schaltung_aktiv 1 "Schaltung_aktiv" 0 "keine_Schaltung" ;
VAL_ 1098 Dynamischer_Eingriff 1022 "kein_Eingriff" 1023 "Fehler" ;
VAL_ 1098 Kuehlkreislaufventil_GME 0 "Ventil_aus" 1 "Ventil_angesteuert" ;
VAL_ 1098 QBit_Uebertragungsfunktion 0 "gueltiger_Wert" 1 "Ersatz_Init_Fehlerwert" ;
VAL_ 1098 Uebertragungsfunktion_11Bit 2047 "Fehler" ;
VAL_ 1098 Getriebeverlustmoment 1023 "Fehler" ;
VAL_ 1098 Status_Langfr_Eingriff 2 "erhoehender_Eingriff_in_T1" 0 "keine_Anforderung" 1 "reduzierender_Eingriff_in_T1" 5 "MomRed_Getriebeschutz" 7 "Fehler" ;
VAL_ 1098 CVT_Anf_EPB 0 "EPB_oeffnen" 1 "EPB_schliessen" ;
VAL_ 1098 CVT_Anf_EPB_gueltig 0 "Anforderung_ungueltig" 1 "Anforderung_gueltig" ;
VAL_ 800 Tankstop 1 "Tankstop_erkannt" 0 "kein_Tankstop" ;
VAL_ 800 Dyn_Oeldr_warn 0 "iO" 1 "Warnung" ;
VAL_ 800 Einheit_angez_Geschw 0 "kmh" 1 "mph" ;
VAL_ 800 Kombi_im_Stellgliedtest 1 "ja" 0 "nein" ;
VAL_ 800 Lenkhilfe_Lampe_ein 0 "EPS_Lampe_aus" 1 "EPS_Lampe_ein" ;
VAL_ 800 ACC_Anzeigefehler 0 "kein_Fehler" 1 "Anzeige_defekt" ;
VAL_ 800 Tankinhalt 127 "Fehler" ;
VAL_ 800 SILA_gueltig 1 "gueltig" 0 "ungueltig" ;
VAL_ 800 Konsistenz_ACC_Botschaften 0 "iO" 1 "Fehler" ;
VAL_ 800 BKL_ein 0 "BKL_aus" 1 "BKL_ein" ;
VAL_ 800 Signalquelle_Geschwindigkeit 0 "Tachogeber" 1 "ABS_Signal" ;
VAL_ 800 SIB_Kombi 0 "CAN_wird_benoetigt" 1 "Sleep_bereit" ;
VAL_ 800 Wakeup_Komfort 1 "Wakeup_Komfort" 0 "keine_Anforderung" ;
VAL_ 800 Tankwarnlampe 1 "Lampe_ein" 0 "Lampe_aus" ;
VAL_ 800 Vorgluehlampe_Kombi 1 "Lampe_ein" 0 "Lampe_aus" ;
VAL_ 800 ACC_Zusatzanzeige 4 "Zeitluecke_4" 3 "Zeitluecke_3" 6 "Zeitluecke_6" 1 "Zeitluecke_1" 7 "Zeitluecke_7" 0 "keine_Anzeige" 5 "Zeitluecke_5" 2 "Zeitluecke_2" ;
VAL_ 800 ABS_Lampe_ein 1 "ABS_Lampe_ein" 0 "ABS_Lampe_aus" ;
VAL_ 800 Tankwarnung 0 "iO" 1 "Tankwarnung" ;
VAL_ 800 ASR_ESP_Lampe_ein 1 "ASR_ESP_Lampe_ein" 0 "ASR_ESP_Lampe_aus" ;
VAL_ 800 Oeldruck 1 "groesser_als_Schwellwert" 0 "kleiner_als_Schwellwert" ;
VAL_ 800 Airbag_Lampe_ein 0 "Airbag_Lampe_aus" 1 "Airbag_Lampe_ein" ;
VAL_ 800 Bremsfluessigkeitswarnung 0 "Lampe_aus" 1 "Bremsfluess_warn" ;
VAL_ 800 Ladekontroll_Lampe 0 "Lampe_aus" 1 "Lampe_ein" ;
VAL_ 800 FStatus_Tank 1 "Tankfuellstand_niO" 0 "Tankfuellstand_iO" ;
VAL_ 800 Kuehlmittelmangel 0 "iO" 1 "Mangel" ;
VAL_ 800 Handbremse_angezogen 0 "nicht_angez" 1 "angez" ;
VAL_ 800 LDW_Anzeigefehler 1 "Fehler" 0 "kein_Fehler" ;
VAL_ 1056 Aussentemp_ungef 255 "Fehler" ;
VAL_ 1056 FStatus_KL58s 1 "KL58s_niO" 0 "KL58s_iO" ;
VAL_ 1056 FSPE_Kombi 0 "kein_KD_Fehler_eingetr" 1 "KD_Fehler_eingetr" ;
VAL_ 1056 Klemme_58s 127 "kein_Ersatzwert" ;
VAL_ 1056 FStatus_Aussentemp 0 "iO" 1 "niO" ;
VAL_ 1056 Waschwasser_Warnung 0 "keine_Warnung" 1 "Waschwasserwarnung" ;
VAL_ 1056 TOG_nicht_verbaut 1 "TOG_nicht_verbaut" 0 "TOG_verbaut" ;
VAL_ 1056 Klemme_58d 127 "kein_Ersatzwert" ;
VAL_ 1056 Aussentemp_gef 0 "nicht_verbaut" 255 "Fehler" ;
VAL_ 1056 Temperatureinheit 0 "Celsius" 1 "Fahrenheit" ;
VAL_ 1056 FStatus_KL58d 0 "KL58d_iO" 1 "KL58d_niO" ;
VAL_ 1056 Oelwarnschwelle_pOue 0 "Schwelle_nicht_ueberschritten" 1 "Schwelle_ueberschritten" ;
VAL_ 1056 GRA_high_Anzeige 1 "ja" 0 "nein" ;
VAL_ 1056 MFA_v_Einheit 1 "mph" 0 "kmh" ;
VAL_ 1312 Kilometerstand 1048575 "Fehler" ;
VAL_ 1312 Schluesselinfo 0 "keine_Info" ;
VAL_ 1312 Reset_Standzeit 0 "Standzeit_iO" 1 "KL30_war_weg" ;
VAL_ 916 LWR_Sicherheitsposition 1 "Sicherheitsposition_an" 0 "Sicherheitsposition_aus" ;
VAL_ 916 LWR_Modus 1 "LWR_dynamisch" 0 "LWR_statisch" ;
VAL_ 916 Einfederung_Karosse_vorn 255 "Fehler" 254 "nicht_initialisiert" ;
VAL_ 916 Einfederung_Karosse_hinten 255 "Fehler" 254 "nicht_initialisiert" ;
VAL_ 916 LWR_Fehlerlampe 1 "LWR_Lampe_an" 0 "LWR_Lampe_aus" ;
VAL_ 916 LWR_Initialisierungslauf 1 "Initialisierungslauf_erfolgt" 0 "Initialisierungslauf_nicht_erfolgt" ;
VAL_ 916 LWR_AFS_Grundeinstellung 0 "Grundeinstellung_nicht_erfolgt" 1 "Grundeinstellung_erfolgt" ;
VAL_ 916 Stellung_Schrittmotoren 255 "" 254 "Init" ;
VAL_ 916 LWR_AFS_Parametrisierung 1 "Parametrisierung_erfolgt" 0 "Parametrisierung_nicht_erfolgt" ;
VAL_ 916 FSPE_LWR_AFS 0 "kein_KD_Fehler_eingetr" 1 "KD_Fehler_eingetr" ;
VAL_ 916 AFS_LED_Blinkmode 0 "kein_Blinken" 1 "Lampe_blinkt_mit_1Hz" ;
VAL_ 916 AFS_Fehlertext 1 "AFS_ohne_Funktion" 0 "kein_Text" ;
VAL_ 916 Ersatzlichtfunktion_rechts 0 "keine_Elfkt_rechts" 1 "Elfkt_rechts" ;
VAL_ 916 Sollwert_LD_EVG 254 "Init" 255 "Fehler" ;
VAL_ 916 Ersatzlichtfunktion_links 0 "keine_Elfkt_links" 1 "Elfkt_links" ;
VAL_ 916 AFS_Fehlerlampe 1 "AFS_Lampe_an" 0 "AFS_Lampe_aus" ;
VAL_ 194 Lenkradwinkel_Sign 1 "negativ" 0 "positiv" ;
VAL_ 194 Lenkradwinkelgeschw_Sign 0 "positiv" ;
VAL_ 194 Quelle_fuer_Init 0 "aus_Bremse3" 1 "EPS_Bit" ;
VAL_ 194 Interner_Status 0 "iO" 2 "sporadischer_Fehler" 3 "dauerhafter_Fehler" 1 "no_init" ;
VAL_ 194 Status_KL30_Ausfall 0 "iO" 1 "no_init_s" ;
VAL_ 640 Kickdownschalter 0 "kein_Kickdown" 1 "Kickdown" ;
VAL_ 640 Fahrpedalwert_DK_Poti 255 "Fehler" ;
VAL_ 640 Fahrerwunschmoment 255 "" ;
VAL_ 640 FStatus_Brems_Momeingr 1 "statisch_nicht_erfuellbar" 0 "erfuellbar" ;
VAL_ 640 Mech_Motor_Verlustmoment 255 "Fehler" ;
VAL_ 640 Inneres_Motormoment 255 "Fehler" ;
VAL_ 640 Fahrpedalwert_ungenau 0 "Fahrpedal_iO" 1 "Ersatzwert" ;
VAL_ 640 Inneres_Motormoment_oeE 255 "Fehler" ;
VAL_ 640 Time_Out_Bremse 1 "Timeout" 0 "Empfang_iO" ;
VAL_ 640 Leergasinformation 1 "Leergas" 0 "kein_Leergas" ;
VAL_ 640 Mmot_Angabe_ungenau 0 "Werte_iO" 1 "Momente_ungenau" ;
VAL_ 640 Kupplungsschalter 0 "Schalter_sagt_ausgekuppelt" 1 "Schalter_sagt_eingekuppelt" ;
VAL_ 648 GRA_Status 2 "uebersteuert" 1 "aktiviert" 3 "ADR_nicht_freigegeben" 0 "ADR_GRA_aus" ;
VAL_ 648 Min_Mmot__ZW_Rueckn 255 "Fehler" ;
VAL_ 648 Begrenzungsmoment 255 "Fehler" ;
VAL_ 648 OBD2_Freeze_Frame 0 "kein_OBD2FF_gesp" 1 "OBD2FF_gesp" ;
VAL_ 648 Getriebecode 7 "AG5_Jatco_ua" 11 "DQ250" 2 "AG4" 4 "VQ250" 10 "AG6_Jatco_ZF6HP_AISIN" 15 "Handschalter" 8 "Autom_Kuppl" 3 "VL300_CVT" 9 "Autom_Kuppl_mit_ASG" 1 "5HP24" 0 "5HP19" 5 "VQ35" 6 "AG4_Jatco_ua" ;
VAL_ 648 Status_Normalbetrieb 1 "Normalbetrieb" 0 "kein_Normalbetrieb" ;
VAL_ 648 CAN_Stand 38 "v465_v467" 25 "v435" 43 "v475" 31 "v445" 11 "v403" 45 "v477_v477a_v477c" 41 "v473c" 44 "v476_v476a_v476c" ;
VAL_ 648 Kuehlmitteltemperatur 255 "Fehler" ;
VAL_ 648 Ansteuerung_Klima 1 "Klima_ein" 0 "Klima_aus" ;
VAL_ 648 Bremslichtschalter_Motor 0 "kein_Bremsen" 1 "Bremse_betaetigt" ;
VAL_ 648 Bremstestschalter_Motor 0 "kein_Bremsen" 1 "Bremse_betaetigt" ;
VAL_ 648 Mux_Code_Motor2 0 "CAN-Stand" 1 "Codierung_Motor" 2 "Codierung_Getriebe" 3 "MDI_Max" ;
VAL_ 648 FStatus_Kuehlmitteltemp_Motor 1 "Temperatur_niO" 0 "Temperatur_iO" ;
VAL_ 648 Soll_Geschw_GRA 255 "Fehler" ;
VAL_ 648 Leerlaufsolldrehzahl 255 "Fehler" ;
VAL_ 896 Ansauglufttemperatur 255 "Fehler" ;
VAL_ 896 FStatus_Ansauglufttemp 1 "Ersatzwert" 0 "Geber_iO" ;
VAL_ 896 Radwunschmoment 4095 "Fehler" ;
VAL_ 896 Motorwunschdrehzahlprioritaet 0 "Wunsch" 1 "Zwang" ;
VAL_ 896 Fahrpedalgradient 255 "Fehler" ;
VAL_ 896 Kein_Start_Stop 0 "Start_Stop_erlaubt" 1 "kein_Start_Stop" ;
VAL_ 896 Vorgluehmeldung 1 "Motor_muss_gestartet_werden" 0 "keine_Anforderung" ;
VAL_ 896 Kein_EGas 0 "EGAS_Motor" 1 "kein_EGAS_Motor" ;
VAL_ 896 Motorwunschdrehzahl 255 "Fehler" ;
VAL_ 896 Fahrpedalwert_ungenau 0 "Fahrpedal_iO" 1 "Fahrpedal_ungenau" ;
VAL_ 896 Signum_Rwmom 1 "negativ" 0 "positiv" ;
VAL_ 896 Fahrpedal_Rohsignal 255 "Fehler" ;
VAL_ 896 Steuerungsbit_Fahrpedalgradient 0 "nicht_bedient" 1 "bedient" ;
VAL_ 896 Signum_Fahrpedalgradient 1 "negativ" 0 "positiv" ;
VAL_ 1152 Doppelte_Momente 0 "Einfach" 1 "" ;
VAL_ 1152 KK_Leistungsreduzierung 1 "ja" 0 "nein" ;
VAL_ 1152 Verbrauch_Ueberlauf 0 "kein_Ueberlauf" 1 "mind_1x_Ueberlauf" ;
VAL_ 1152 Kennfeldkuehlung 0 "nein" 1 "ja" ;
VAL_ 1152 KK_aus 0 "keine_Anforderung" 1 "Klimakomp_aus" ;
VAL_ 1152 Kuehlerluefteransteuerung 255 "Fehler" ;
VAL_ 1152 EGas_Lampe 1 "Lampe_ein" 0 "Lampe_aus" ;
VAL_ 1152 Heissleuchte 0 "Lampe_aus" 1 "Lampe_ein" ;
VAL_ 1152 Anlasser_Freigabe 1 "Startfreigabe" 0 "nicht_zulaessig" ;
VAL_ 1152 FStatus_BKU_Pumpe 1 "niO" 0 "iO" ;
VAL_ 1152 Vorgluehlampe_Motor 1 "Lampe_ein" 0 "Lampe_aus" ;
VAL_ 1152 Anlasser_Ausspuren 0 "Motor_laeuft_nicht_stabil" 1 "Anlasser_ausspuren" ;
VAL_ 1152 Partikelfilter_Lampe 1 "Lampe_ein" 0 "Lampe_aus" ;
VAL_ 1152 Mux_Code_Motor5 1 "Drehzahl" 0 "Max_Moment" 2 "Motortyp" 3 "Abgastyp" ;
VAL_ 1152 Ladekontroll_Lampe 1 "Lampe_ein" 0 "Lampe_aus" ;
VAL_ 1152 OBD2_Lampe 0 "Lampe_aus" 1 "Lampe_ein" ;
VAL_ 1152 HLVW_Motor 1 "Vorwarnung" 0 "keine_Warnung" ;
VAL_ 1152 Interlock_Schalter 0 "Interlock_nicht_betaetigt" 1 "Interlock_betaetigt" ;
VAL_ 1152 Typ_Startersteuerung 0 "konventionell" 1 "" ;
VAL_ 1152 Drehzahlmesser_Daempfung 0 "normal" 1 "dynamisch" ;
